VERSION ""

NS_ :

BS_:

BU_: ARM APIM_CDC APIM_CISM APIM ESPM DSP APIM_CIM FCIMB RACM_RCIM HUD_ADV WCM TRM_ITRM ACM GWM _delete IPC GENERIC TSTR

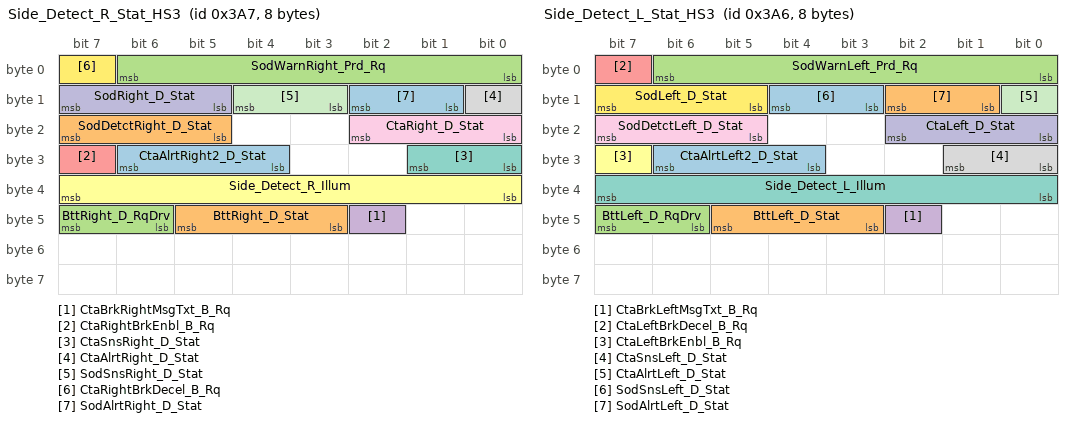
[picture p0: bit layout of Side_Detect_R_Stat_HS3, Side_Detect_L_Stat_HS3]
BO_ 935 Side_Detect_R_Stat_HS3: 8 GWM
 SG_ CtaAlrtRight2_D_Stat : 30|3@0+ (1,0) [0|7] "SED"  APIM_CDC,APIM_CIM,IPC
 SG_ BttRight_D_Stat : 45|3@0+ (1,0) [0|7] "SED"  APIM_CDC,APIM,APIM_CISM,APIM_CIM,IPC
 SG_ BttRight_D_RqDrv : 47|2@0+ (1,0) [0|3] "SED"  APIM_CDC,APIM,APIM_CISM,APIM_CIM,IPC
 SG_ CtaBrkRightMsgTxt_B_Rq : 42|1@0+ (1,0) [0|1] "SED"  APIM_CDC,APIM,APIM_CISM,APIM_CIM,IPC
 SG_ CtaRightBrkEnbl_B_Rq : 31|1@0+ (1,0) [0|1] "SED"  GENERIC
 SG_ Side_Detect_R_Illum : 39|8@0+ (1,0) [0|255] "Percent"  APIM_CDC,APIM_CIM,IPC
 SG_ CtaSnsRight_D_Stat : 25|2@0+ (1,0) [0|3] "SED"  APIM_CDC,APIM_CIM,IPC
 SG_ CtaAlrtRight_D_Stat : 8|1@0+ (1,0) [0|1] "SED"  APIM_CDC,APIM,APIM_CISM,APIM_CIM,IPC
 SG_ CtaRight_D_Stat : 18|3@0+ (1,0) [0|7] "SED"  APIM_CDC,APIM_CIM,IPC
 SG_ SodRight_D_Stat : 15|3@0+ (1,0) [0|7] "SED"  APIM_CDC,APIM_CIM,IPC
 SG_ SodSnsRight_D_Stat : 12|2@0+ (1,0) [0|3] "SED"  APIM_CDC,APIM_CIM,IPC
 SG_ CtaRightBrkDecel_B_Rq : 7|1@0+ (1,0) [0|1] "SED"  GENERIC
 SG_ SodAlrtRight_D_Stat : 10|2@0+ (1,0) [0|3] "SED"  APIM_CDC,APIM,APIM_CIM,HUD_ADV,APIM_CISM,IPC
 SG_ SodDetctRight_D_Stat : 23|3@0+ (1,0) [0|7] "SED"  APIM_CDC,APIM_CIM,IPC
 SG_ SodWarnRight_Prd_Rq : 6|7@0+ (1,0) [0|127] "millisecond" Vector__XXX

BO_ 934 Side_Detect_L_Stat_HS3: 8 GWM
 SG_ CtaAlrtLeft2_D_Stat : 30|3@0+ (1,0) [0|7] "SED"  APIM_CDC,APIM_CIM,IPC
 SG_ BttLeft_D_Stat : 45|3@0+ (1,0) [0|7] "SED"  APIM_CDC,APIM,APIM_CISM,APIM_CIM,IPC
 SG_ BttLeft_D_RqDrv : 47|2@0+ (1,0) [0|3] "SED"  APIM_CDC,APIM,APIM_CIM,APIM_CISM,IPC
 SG_ CtaBrkLeftMsgTxt_B_Rq : 42|1@0+ (1,0) [0|1] "SED"  APIM_CDC,APIM,APIM_CISM,APIM_CIM,IPC
 SG_ CtaLeftBrkDecel_B_Rq : 7|1@0+ (1,0) [0|1] "SED"  GENERIC
 SG_ CtaLeftBrkEnbl_B_Rq : 31|1@0+ (1,0) [0|1] "SED"  GENERIC
 SG_ Side_Detect_L_Illum : 39|8@0+ (1,0) [0|255] "Percent"  APIM_CDC,APIM_CIM,IPC
 SG_ CtaSnsLeft_D_Stat : 25|2@0+ (1,0) [0|3] "SED"  APIM_CDC,APIM_CIM,IPC
 SG_ SodDetctLeft_D_Stat : 23|3@0+ (1,0) [0|7] "SED"  APIM_CDC,APIM_CIM,IPC
 SG_ CtaLeft_D_Stat : 18|3@0+ (1,0) [0|7] "SED"  APIM_CDC,APIM_CIM,IPC
 SG_ CtaAlrtLeft_D_Stat : 8|1@0+ (1,0) [0|1] "SED"  APIM_CDC,APIM,APIM_CISM,APIM_CIM,IPC
 SG_ SodLeft_D_Stat : 15|3@0+ (1,0) [0|7] "SED"  APIM_CDC,APIM_CIM,IPC
 SG_ SodSnsLeft_D_Stat : 12|2@0+ (1,0) [0|3] "SED"  APIM_CDC,APIM_CIM,IPC
 SG_ SodAlrtLeft_D_Stat : 10|2@0+ (1,0) [0|3] "SED"  APIM_CDC,APIM,HUD_ADV,APIM_CISM,APIM_CIM,IPC
 SG_ SodWarnLeft_Prd_Rq : 6|7@0+ (1,0) [0|127] "millisecond" Vector__XXX

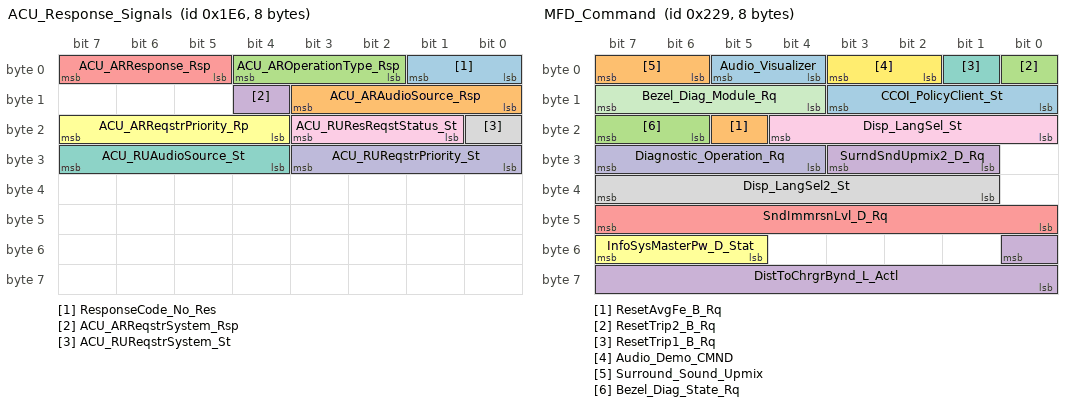
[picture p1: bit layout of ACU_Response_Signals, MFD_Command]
BO_ 486 ACU_Response_Signals: 8 APIM_CIM
 SG_ ResponseCode_No_Res : 1|2@0+ (1,0) [0|3] "SED"  APIM_CDC,APIM
 SG_ ACU_ARAudioSource_Rsp : 11|4@0+ (1,0) [0|15] "SED"  APIM_CDC,APIM,GWM,DSP,IPC
 SG_ ACU_AROperationType_Rsp : 4|3@0+ (1,0) [0|7] "SED"  APIM_CDC,APIM,GWM,DSP,IPC
 SG_ ACU_ARReqstrSystem_Rsp : 12|1@0+ (1,0) [0|1] "SED"  APIM_CDC,APIM,GWM,DSP,IPC
 SG_ ACU_ARResponse_Rsp : 7|3@0+ (1,0) [0|6] "SED"  APIM_CDC,APIM,GWM,DSP,IPC
 SG_ ACU_ARReqstrPriority_Rp : 23|4@0+ (1,0) [0|15] "SED"  APIM_CDC,APIM,GWM,DSP,IPC
 SG_ ACU_RUAudioSource_St : 31|4@0+ (1,0) [0|15] "SED"  HUD_ADV,APIM_CDC,APIM,DSP,GWM,RACM_RCIM,WCM,IPC
 SG_ ACU_RUReqstrSystem_St : 16|1@0+ (1,0) [0|1] "SED"  HUD_ADV,APIM_CDC,APIM,WCM,GWM,DSP,RACM_RCIM,IPC
 SG_ ACU_RUResReqstStatus_St : 19|3@0+ (1,0) [0|7] "SED"  HUD_ADV,APIM_CDC,APIM,DSP,GWM,RACM_RCIM,WCM,IPC
 SG_ ACU_RUReqstrPriority_St : 27|4@0+ (1,0) [0|15] "SED"  HUD_ADV,APIM_CDC,APIM,GWM,DSP,RACM_RCIM,WCM,IPC

BO_ 553 MFD_Command: 8 APIM
 SG_ CCOI_PolicyClient_St : 11|4@0+ (1,0) [0|15] "SED"  GWM
 SG_ ResetAvgFe_B_Rq : 21|1@0+ (1,0) [0|1] "SED"  IPC,GWM
 SG_ ResetTrip2_B_Rq : 0|1@0+ (1,0) [0|1] "SED"  IPC,GWM
 SG_ DistToChrgrBynd_L_Actl : 48|9@0+ (1,0) [0|509] "kilometer"  GWM
 SG_ SndImmrsnLvl_D_Rq : 47|8@0+ (1,0) [0|255] "SED"  DSP,GWM
 SG_ InfoSysMasterPw_D_Stat : 55|3@0+ (1,0) [0|7] "SED"  GWM
 SG_ ResetTrip1_B_Rq : 1|1@0+ (1,0) [0|1] "SED"  IPC,GWM
 SG_ Disp_LangSel2_St : 39|7@0+ (1,0) [0|127] "SED"  IPC,GWM
 SG_ Disp_LangSel_St : 20|5@0+ (1,0) [0|31] "SED"  GWM,RACM_RCIM,IPC
 SG_ Diagnostic_Operation_Rq : 31|4@0+ (1,0) [0|15] "SED"  DSP,GWM,ACM
 SG_ Bezel_Diag_Module_Rq : 15|4@0+ (1,0) [0|15] "SED"  DSP,GWM,ACM
 SG_ Audio_Demo_CMND : 3|2@0+ (1,0) [0|3] "SED"  GWM,DSP,ACM
 SG_ Audio_Visualizer : 5|2@0+ (1,0) [0|3] "SED"  GWM,DSP,ACM
 SG_ Surround_Sound_Upmix : 7|2@0+ (1,0) [0|3] "SED"  GWM,DSP
 SG_ Bezel_Diag_State_Rq : 23|2@0+ (1,0) [0|3] "SED"  DSP,GWM,ACM
 SG_ SurndSndUpmix2_D_Rq : 27|3@0+ (1,0) [0|7] "SED"  DSP,GWM

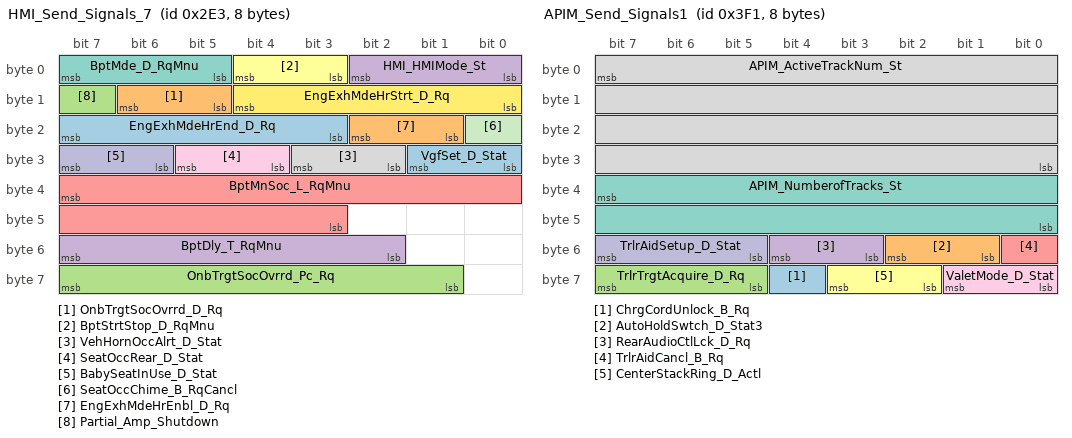
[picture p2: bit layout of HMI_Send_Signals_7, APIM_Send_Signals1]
BO_ 739 HMI_Send_Signals_7: 8 APIM
 SG_ VgfSet_D_Stat : 25|2@0+ (1,0) [0|3] "SED"  GWM
 SG_ OnbTrgtSocOvrrd_D_Rq : 14|2@0+ (1,0) [0|3] "SED"  GWM
 SG_ OnbTrgtSocOvrrd_Pc_Rq : 63|7@0+ (1,0) [0|127] "percent"  GWM
 SG_ BptDly_T_RqMnu : 55|6@0+ (0.5,0) [0|30.5] "minute"  GWM
 SG_ BptMnSoc_L_RqMnu : 39|13@0+ (0.1,0) [0|818.9] "kilometer"  GWM
 SG_ BptStrtStop_D_RqMnu : 4|2@0+ (1,0) [0|3] "SED"  GWM
 SG_ BptMde_D_RqMnu : 7|3@0+ (1,0) [0|7] "SED"  GWM
 SG_ VehHornOccAlrt_D_Stat : 27|2@0+ (1,0) [0|3] "SED"  GWM
 SG_ SeatOccRear_D_Stat : 29|2@0+ (1,0) [0|3] "SED"  GWM
 SG_ BabySeatInUse_D_Stat : 31|2@0+ (1,0) [0|3] "SED"  GWM
 SG_ SeatOccChime_B_RqCancl : 16|1@0+ (1,0) [0|1] "SED"  GWM
 SG_ EngExhMdeHrStrt_D_Rq : 12|5@0+ (1,0) [0|31] "SED"  GWM
 SG_ EngExhMdeHrEnd_D_Rq : 23|5@0+ (1,0) [0|31] "SED"  GWM
 SG_ EngExhMdeHrEnbl_D_Rq : 18|2@0+ (1,0) [0|3] "SED"  GWM
 SG_ Partial_Amp_Shutdown : 15|1@0+ (1,0) [0|1] "SED"  GWM,ACM
 SG_ HMI_HMIMode_St : 2|3@0+ (1,0) [0|7] "SED"  RACM_RCIM,DSP,HUD_ADV,ACM,WCM,IPC,GWM

BO_ 1009 APIM_Send_Signals1: 8 APIM
 SG_ ChrgCordUnlock_B_Rq : 60|1@0+ (1,0) [0|1] "SED"  GWM
 SG_ AutoHoldSwtch_D_Stat3 : 50|2@0+ (1,0) [0|3] "SED"  GWM
 SG_ TrlrTrgtAcquire_D_Rq : 63|3@0+ (1,0) [0|7] "SED"  GWM
 SG_ RearAudioCtlLck_D_Rq : 52|2@0+ (1,0) [0|3] "SED"  RACM_RCIM,GWM
 SG_ TrlrAidCancl_B_Rq : 48|1@0+ (1,0) [0|1] "SED"  GWM
 SG_ CenterStackRing_D_Actl : 59|2@0+ (1,0) [0|3] "SED"  GWM
 SG_ APIM_NumberofTracks_St : 39|16@0+ (1,0) [0|65535] "unitless"  RACM_RCIM,GWM,HUD_ADV,IPC
 SG_ APIM_ActiveTrackNum_St : 7|32@0+ (1,0) [0|4294967295] "unitless"  RACM_RCIM,GWM,HUD_ADV,IPC
 SG_ ValetMode_D_Stat : 57|2@0+ (1,0) [0|3] "SED"  GWM
 SG_ TrlrAidSetup_D_Stat : 55|3@0+ (1,0) [0|7] "SED"  GWM,IPC

BO_ 531 DesiredTorqBrk_HS3: 8 GWM
 SG_ VehStop_D_Stat : 28|2@0+ (1,0) [0|3] "SED"  GENERIC
 SG_ TracCtlPtActv_B_Actl : 31|1@0+ (1,0) [0|1] "SED"  GENERIC
 SG_ PrkBrkYwLamp_D_Rq : 38|2@0+ (1,0) [0|3] "SED"  APIM_CDC,APIM_CISM,APIM_CIM,IPC
 SG_ PrkBrkRedLamp_D_Rq : 30|2@0+ (1,0) [0|3] "SED"  APIM_CDC,APIM_CISM,APIM_CIM,IPC
 SG_ PrkBrkMsgTxt_D_Rq : 36|4@0+ (1,0) [0|15] "SED"  APIM_CDC,APIM_CISM,APIM_CIM,IPC
 SG_ PrkBrkStatus : 26|3@0+ (1,0) [0|7] "SED"  APIM_CDC,IPC,APIM,APIM_CIM,APIM_CISM
 SG_ LscmbbMntr_B_Err : 17|1@0+ (1,0) [0|1] "SED"  APIM_CDC,APIM,APIM_CISM,APIM_CIM,IPC
 SG_ LscmbbBrkDis_B_Actl : 19|1@0+ (1,0) [0|1] "SED"  GENERIC
 SG_ StabCtlBrkActv_B_Actl : 23|1@0+ (1,0) [0|1] "SED"  APIM_CDC,APIM,APIM_CIM,APIM_CISM
 SG_ CmbbBrkPrchg_B_Actl : 59|1@0+ (1,0) [0|1] "SED"  TRM_ITRM
 SG_ CmbbBrkDecel_B_Actl : 58|1@0+ (1,0) [0|1] "SED"  TRM_ITRM
 SG_ CmbbBaSensInc_B_Actl : 57|1@0+ (1,0) [0|1] "SED"  GENERIC
 SG_ AccBrkWarm_B_Actl : 63|1@0+ (1,0) [0|1] "SED"  GENERIC
 SG_ AccBrkTotTqMn_B_Actl : 62|1@0+ (1,0) [0|1] "SED"  TRM_ITRM
 SG_ AccBrkPrchgActv_B_Actl : 61|1@0+ (1,0) [0|1] "SED"  GENERIC
 SG_ AccBrkDis_B_Actl : 44|1@0+ (1,0) [0|1] "SED"  GENERIC
 SG_ AccBrkDeny_B_Actl : 42|1@0+ (1,0) [0|1] "SED"  GENERIC
 SG_ AccBrkActv_B_Actl : 43|1@0+ (1,0) [0|1] "SED"  GENERIC
 SG_ PrplDrgCtlActv_B_Actl : 46|1@0+ (1,0) [0|1] "SED"  GENERIC
 SG_ PrplWhlTot_Tq_RqMx : 7|16@0+ (4,-131072) [-131072|131068] "Nm"  GENERIC
 SG_ AbsActv_B_Actl : 45|1@0+ (1,0) [0|1] "SED"  APIM_CDC,APIM,APIM_CIM,APIM_CISM,TRM_ITRM
 SG_ CmbbBrkDis_B_Actl : 56|1@0+ (1,0) [0|1] "SED"  GENERIC
 SG_ CmbbDeny_B_ActlBrk : 60|1@0+ (1,0) [0|1] "SED"  GENERIC
 SG_ CcDis_B_Cmd : 47|1@0+ (1,0) [0|1] "SED"  GENERIC
 SG_ VehLongOvrGnd_A_Est : 41|10@0+ (0.035,-17.9) [-17.9|17.835] "m/s^2"  TRM_ITRM
 SG_ AccStopActv_B_ActlBrk : 22|1@0+ (1,0) [0|1] "SED"  GENERIC
 SG_ AccDis_B_ActlEpb : 32|1@0+ (1,0) [0|1] "SED"  GENERIC
 SG_ LscmbbDeny_B_ActlBrk : 18|1@0+ (1,0) [0|1] "SED"  GENERIC
 SG_ LscmbbBrkDecel_B_Actl : 20|1@0+ (1,0) [0|1] "SED"  GENERIC
 SG_ LscmbbBaSensInc_B_Actl : 21|1@0+ (1,0) [0|1] "SED"  GENERIC
 SG_ LscmbBrkPrchg_B_Actl : 16|1@0+ (1,0) [0|1] "SED"  GENERIC
 SG_ VehicleStationary : 39|1@0+ (1,0) [0|1] "SED"  GENERIC

BO_ 702 PHONE_MC_WORD_Rx: 8 IPC
 SG_ PHONE_MC_WORD_Rx : 7|64@0+ (1,0) [0|1.84467440737096E+019] "unitless"  APIM,APIM_CISM

BO_ 711 MyKeySrvr_MyKeyClient_Word: 8 IPC
 SG_ MyKeySrvr_Clnt_Word_Tx : 7|64@0+ (1,0) [0|1.84467440737096E+019] "unitless"  APIM,APIM_CISM

BO_ 549 IPC_Infotainment: 8 IPC
 SG_ BattTracLoThres_D_Rq2 : 52|3@0+ (1,0) [0|7] "SED"  GWM
 SG_ NavIod_D_Rq : 55|3@0+ (1,0) [0|7] "SED"  GWM,APIM_CISM
 SG_ StrtInGearOk_D_Stat : 17|2@0+ (1,0) [0|3] "SED"  GWM
 SG_ WwaActv_B_Stat : 46|1@0+ (1,0) [0|1] "SED"  APIM,APIM_CISM,GWM,ACM
 SG_ Veh_V2_Dsply : 39|9@0+ (1,0) [0|511] "unitless"  APIM_CDC,APIM,APIM_CISM,GWM,HUD_ADV
 SG_ IPC_MyKeyVolLimit_St : 9|2@0+ (1,0) [0|3] "SED"  APIM,APIM_CISM,GWM,DSP,ACM
 SG_ HudVertSzMnuOn_B_Rq : 21|1@0+ (1,0) [0|1] "SED"  GWM,HUD_ADV
 SG_ HudVertMnuOn_B_Rq : 11|1@0+ (1,0) [0|1] "SED"  GWM,HUD_ADV
 SG_ HudRotatMnuOn_B_Rq : 22|1@0+ (1,0) [0|1] "SED"  GWM,HUD_ADV
 SG_ HudCntntMnuOn_B_Rq : 20|1@0+ (1,0) [0|1] "SED"  GWM,HUD_ADV
 SG_ HudBrightMnuOn_B_Rq : 1|1@0+ (1,0) [0|1] "SED"  GWM,HUD_ADV
 SG_ HdcOn_B_Rq : 19|1@0+ (1,0) [0|1] "SED"  GWM
 SG_ IPC_Attn_Info_Audio : 4|3@0+ (1,0) [0|7] "SED"  APIM,APIM_CISM,GWM,DSP,ACM
 SG_ BeltminderAudioMute : 6|2@0+ (1,0) [0|3] "SED"  APIM,APIM_CISM,GWM,DSP,ACM
 SG_ Power_Up_Chime_Modules : 23|1@0+ (1,0) [0|1] "SED"  APIM_CISM,GWM,DSP,ACM
 SG_ Chime_Source : 15|2@0+ (1,0) [0|3] "SED"  APIM_CISM,GWM,DSP,ACM
 SG_ TjaLcEnbl_D_DrvRq : 41|2@0+ (1,0) [0|3] "SED"  GWM
 SG_ CCOI_PolicyClient_St2 : 45|4@0+ (1,0) [0|15] "SED"  GWM
 SG_ FactoryReset_Rq2 : 18|1@0+ (1,0) [0|1] "SED"  GWM
 SG_ IPC_New_Attn_Event : 0|1@0+ (1,0) [0|1] "SED"  APIM,APIM_CISM,GWM,DSP,ACM
 SG_ MetricActv_B_Dsply : 7|1@0+ (1,0) [0|1] "SED"  ARM,HUD_ADV,GWM

BO_ 765 Mc_Send_Signals_2: 8 IPC
 SG_ BalrSwtch_D_Stat : 57|2@0+ (1,0) [0|3] "SED"  GWM
 SG_ BalrMde_D_Rq : 59|2@0+ (1,0) [0|3] "SED"  GWM
 SG_ RstrnOnPsngr_D_RqMnu : 63|4@0+ (1,0) [0|15] "SED"  GWM
 SG_ WaitToStartLamp_D_Falt : 50|2@0+ (1,0) [0|3] "SED"  GWM
 SG_ EsaOn_B_Rq : 15|1@0+ (1,0) [0|1] "SED"  GWM
 SG_ BttOn_B_Rq : 26|1@0+ (1,0) [0|1] "SED"  GWM
 SG_ Btt_L_Actl : 39|7@0+ (0.1,0) [0|12.5] "meter"  GWM
 SG_ RearDiffLck_D_RqArb : 25|2@0+ (1,0) [0|3] "SED"  GWM
 SG_ AwdMde_D_RqArb : 47|3@0+ (1,0) [0|7] "SED"  GWM
 SG_ SelDrvMdeTxtReset_B_Rq : 40|1@0+ (1,0) [0|1] "SED"  GWM
 SG_ AutoTowAllw_D_RqMnu : 52|2@0+ (1,0) [0|3] "SED"  GWM
 SG_ DrvInputRequired_B_Rq : 32|1@0+ (1,0) [0|1] "SED"  GWM
 SG_ SelDrvMdeDsply_B_Avail : 41|1@0+ (1,0) [0|1] "SED"  GWM
 SG_ EngExhMdeQuiet_D_Rq : 17|2@0+ (1,0) [0|3] "SED"  GWM
 SG_ AirSusp_D_RqDrv : 31|2@0+ (1,0) [0|3] "SED"  GWM
 SG_ Mc_VehUntTrpCoUsrSel_St : 23|1@0+ (1,0) [0|1] "SED"  APIM,APIM_CISM,HUD_ADV,GWM
 SG_ Mc_VehUnitTempUsrSel_St : 22|1@0+ (1,0) [0|1] "SED"  APIM,APIM_CISM,HUD_ADV,RACM_RCIM,GWM
 SG_ Mc_VehDayNightUsrSel_St : 14|3@0+ (1,0) [0|7] "SED"  APIM,APIM_CISM,GWM,ACM
 SG_ Mc_VehTimeFrmtUsrSel_St : 1|2@0+ (1,0) [0|3] "SED"  APIM,APIM_CISM,GWM,HUD_ADV,RACM_RCIM
 SG_ Mc_VehThemeUsrSel_St : 11|4@0+ (1,0) [0|15] "SED"  APIM,APIM_CISM,GWM,GENERIC
 SG_ Mc_VehLangUsrSel_St : 7|6@0+ (1,0) [0|63] "SED"  APIM,APIM_CISM,HUD_ADV,ACM,GWM
 SG_ AwdRnge_D_ActlIpc : 29|3@0+ (1,0) [0|7] "SED"  GWM
 SG_ AwdDrvMde_D_Rq : 44|3@0+ (1,0) [0|7] "SED"  GWM
 SG_ EngExhMdeQuiet_D2_Rq : 55|3@0+ (1,0) [0|7] "SED"  GWM
 SG_ BrkLineLck_D_Rq : 19|2@0+ (1,0) [0|3] "SED"  GWM
 SG_ EdmSailMde_B_RqDrv : 48|1@0+ (1,0) [0|1] "SED"  GWM
 SG_ Running_Board_Cmd : 21|2@0+ (1,0) [0|3] "SED"  GWM

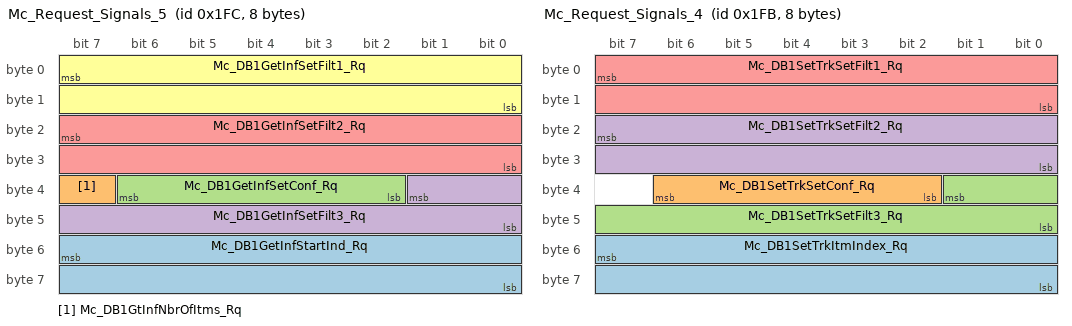
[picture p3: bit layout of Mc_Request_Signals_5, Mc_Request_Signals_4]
BO_ 508 Mc_Request_Signals_5: 8 IPC
 SG_ Mc_DB1GetInfStartInd_Rq : 55|16@0+ (1,0) [0|65535] "unitless"  APIM_CISM,ACM,GWM
 SG_ Mc_DB1GtInfNbrOfItms_Rq : 39|1@0+ (1,0) [0|1] "SED"  APIM_CISM,ACM,GWM
 SG_ Mc_DB1GetInfSetConf_Rq : 38|5@0+ (1,0) [0|31] "SED"  APIM_CISM,ACM,GWM
 SG_ Mc_DB1GetInfSetFilt3_Rq : 33|10@0+ (1,0) [0|1023] "unitless"  APIM_CISM,ACM,GWM
 SG_ Mc_DB1GetInfSetFilt2_Rq : 23|16@0+ (1,0) [0|65535] "unitless"  APIM_CISM,ACM,GWM
 SG_ Mc_DB1GetInfSetFilt1_Rq : 7|16@0+ (1,0) [0|65535] "unitless"  APIM_CISM,ACM,GWM

BO_ 507 Mc_Request_Signals_4: 8 IPC
 SG_ Mc_DB1SetTrkItmIndex_Rq : 55|16@0+ (1,0) [0|65535] "unitless"  APIM_CISM,ACM,GWM
 SG_ Mc_DB1SetTrkSetConf_Rq : 38|5@0+ (1,0) [0|31] "SED"  APIM_CISM,ACM,GWM
 SG_ Mc_DB1SetTrkSetFilt3_Rq : 33|10@0+ (1,0) [0|1023] "unitless"  APIM_CISM,ACM,GWM
 SG_ Mc_DB1SetTrkSetFilt2_Rq : 23|16@0+ (1,0) [0|65535] "unitless"  APIM_CISM,ACM,GWM
 SG_ Mc_DB1SetTrkSetFilt1_Rq : 7|16@0+ (1,0) [0|65535] "unitless"  APIM_CISM,ACM,GWM

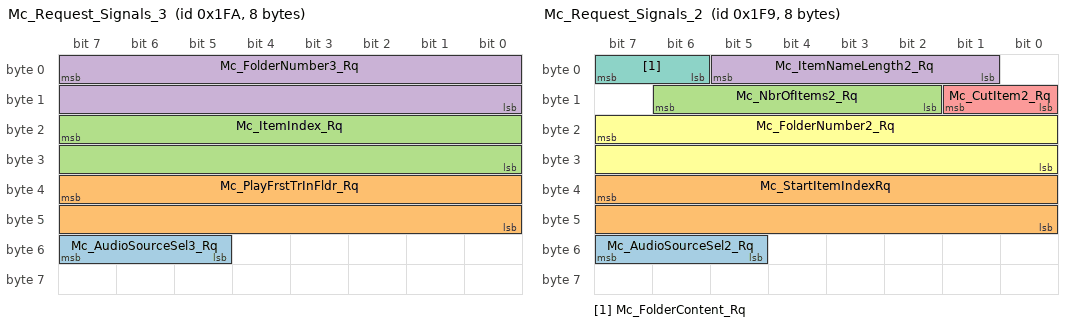
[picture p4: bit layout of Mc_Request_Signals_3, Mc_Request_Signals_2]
BO_ 506 Mc_Request_Signals_3: 8 IPC
 SG_ Mc_AudioSourceSel3_Rq : 55|3@0+ (1,0) [0|7] "SED"  APIM_CISM,ACM,GWM
 SG_ Mc_PlayFrstTrInFldr_Rq : 39|16@0+ (1,0) [0|65535] "unitless"  APIM_CISM,ACM,GWM
 SG_ Mc_ItemIndex_Rq : 23|16@0+ (1,0) [0|65535] "unitless"  APIM_CISM,ACM,GWM
 SG_ Mc_FolderNumber3_Rq : 7|16@0+ (1,0) [0|65535] "unitless"  APIM_CISM,ACM,GWM

BO_ 505 Mc_Request_Signals_2: 8 IPC
 SG_ Mc_AudioSourceSel2_Rq : 55|3@0+ (1,0) [0|7] "SED"  APIM_CISM,ACM,GWM
 SG_ Mc_StartItemIndexRq : 39|16@0+ (1,0) [0|65535] "unitless"  APIM_CISM,ACM,GWM
 SG_ Mc_NbrOfItems2_Rq : 14|5@0+ (1,0) [0|20] "SED"  APIM_CISM,ACM,GWM
 SG_ Mc_ItemNameLength2_Rq : 5|5@0+ (1,0) [0|20] "SED"  APIM_CISM,ACM,GWM
 SG_ Mc_CutItem2_Rq : 9|2@0+ (1,0) [0|3] "SED"  APIM_CISM,ACM,GWM
 SG_ Mc_FolderNumber2_Rq : 23|16@0+ (1,0) [0|65535] "unitless"  APIM_CISM,ACM,GWM
 SG_ Mc_FolderContent_Rq : 7|2@0+ (1,0) [0|3] "SED"  APIM_CISM,ACM,GWM

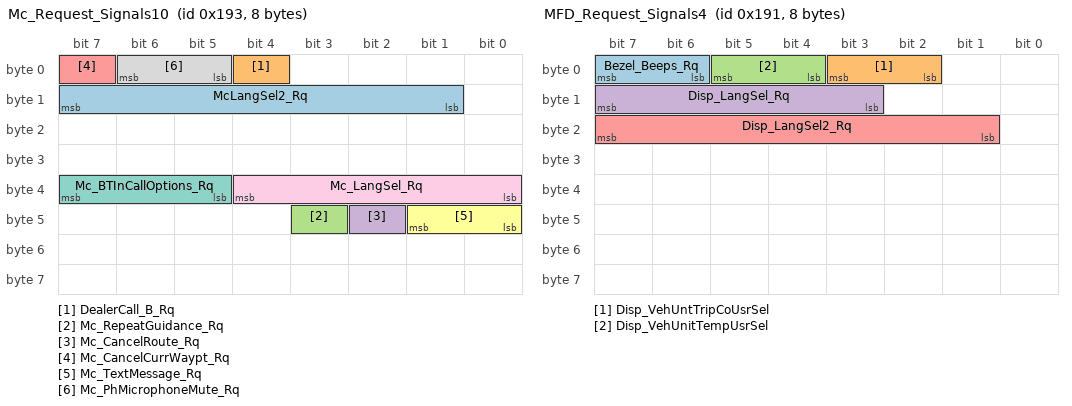
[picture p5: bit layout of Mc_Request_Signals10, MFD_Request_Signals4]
BO_ 403 Mc_Request_Signals10: 8 IPC
 SG_ McLangSel2_Rq : 15|7@0+ (1,0) [0|127] "SED"  APIM,APIM_CISM,GWM
 SG_ DealerCall_B_Rq : 4|1@0+ (1,0) [0|1] "SED"  APIM,APIM_CISM,GWM
 SG_ Mc_RepeatGuidance_Rq : 43|1@0+ (1,0) [0|1] "SED"  APIM,APIM_CISM,GWM
 SG_ Mc_CancelRoute_Rq : 42|1@0+ (1,0) [0|1] "SED"  APIM,APIM_CISM,GWM
 SG_ Mc_CancelCurrWaypt_Rq : 7|1@0+ (1,0) [0|1] "SED"  APIM,APIM_CISM,GWM
 SG_ Mc_TextMessage_Rq : 41|2@0+ (1,0) [0|3] "SED"  APIM,APIM_CISM,GWM
 SG_ Mc_BTInCallOptions_Rq : 39|3@0+ (1,0) [0|7] "SED"  APIM,APIM_CISM,GWM
 SG_ Mc_PhMicrophoneMute_Rq : 6|2@0+ (1,0) [0|3] "SED"  APIM,APIM_CISM,GWM
 SG_ Mc_LangSel_Rq : 36|5@0+ (1,0) [0|31] "SED"  APIM,APIM_CISM,GWM

BO_ 401 MFD_Request_Signals4: 8 APIM
 SG_ Bezel_Beeps_Rq : 7|2@0+ (1,0) [0|3] "SED"  FCIMB,GWM
 SG_ Disp_VehUntTripCoUsrSel : 3|2@0+ (1,0) [0|3] "SED"  GWM,IPC
 SG_ Disp_VehUnitTempUsrSel : 5|2@0+ (1,0) [0|3] "SED"  GWM,IPC
 SG_ Disp_LangSel_Rq : 15|5@0+ (1,0) [0|31] "SED"  GWM,IPC
 SG_ Disp_LangSel2_Rq : 23|7@0+ (1,0) [0|127] "SED"  IPC

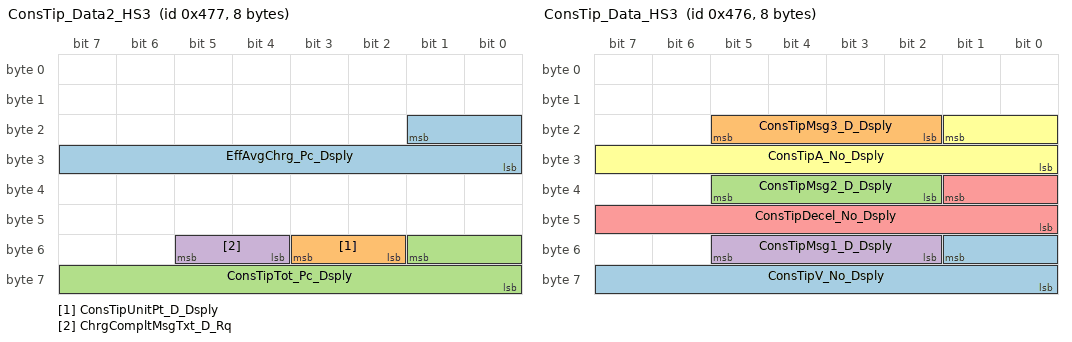
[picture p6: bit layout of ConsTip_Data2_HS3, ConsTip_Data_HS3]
BO_ 1143 ConsTip_Data2_HS3: 8 GWM
 SG_ EffAvgChrg_Pc_Dsply : 17|10@0+ (0.1,0) [0|102.3] "percent"  APIM_CDC,APIM_CISM,APIM_CIM,IPC
 SG_ ConsTipUnitPt_D_Dsply : 51|2@0+ (1,0) [0|3] "SED"  APIM_CDC,APIM,APIM_CIM,APIM_CISM,IPC
 SG_ ConsTipTot_Pc_Dsply : 49|10@0+ (0.1,0) [0|102.1] "percent"  APIM_CDC,APIM_CIM,IPC
 SG_ ChrgCompltMsgTxt_D_Rq : 53|2@0+ (1,0) [0|3] "SED"  APIM_CDC,APIM,APIM_CIM,APIM_CISM,IPC

BO_ 1142 ConsTip_Data_HS3: 8 GWM
 SG_ ConsTipV_No_Dsply : 49|10@0+ (0.1,0) [0|102.1] "percent"  APIM_CDC,APIM,APIM_CIM,APIM_CISM,IPC
 SG_ ConsTipMsg3_D_Dsply : 21|4@0+ (1,0) [0|15] "SED"  APIM_CDC,APIM,APIM_CIM,APIM_CISM,IPC
 SG_ ConsTipMsg2_D_Dsply : 37|4@0+ (1,0) [0|15] "SED"  APIM_CDC,APIM,APIM_CIM,APIM_CISM,IPC
 SG_ ConsTipMsg1_D_Dsply : 53|4@0+ (1,0) [0|15] "SED"  APIM_CDC,APIM,APIM_CIM,APIM_CISM,IPC
 SG_ ConsTipDecel_No_Dsply : 33|10@0+ (0.1,0) [0|102.1] "percent"  APIM_CDC,APIM,APIM_CIM,APIM_CISM,IPC
 SG_ ConsTipA_No_Dsply : 17|10@0+ (0.1,0) [0|102.1] "percent"  APIM_CDC,APIM,APIM_CIM,APIM_CISM,IPC

BO_ 973 Traffic_RecogitionData_HS3: 8 GWM
 SG_ PersCtaSplitView_D_Stat : 12|2@0+ (1,0) [0|3] "SED"  APIM_CDC,APIM,APIM_CIM,APIM_CISM
 SG_ LaSysOffStat_D_Dsply : 58|2@0+ (1,0) [0|3] "SED"  APIM_CDC,APIM_CIM,IPC
 SG_ TsrVl1RstrcMsgTxt2_D_Rq : 51|3@0+ (1,0) [0|7] "SED"  APIM_CDC,APIM_CISM,APIM_CIM,HUD_ADV,IPC
 SG_ TsrVl2RstrcMsgTxt2_D_Rq : 63|3@0+ (1,0) [0|7] "SED"  APIM_CDC,APIM_CISM,APIM_CIM,HUD_ADV,IPC
 SG_ TsrVl2PrmntMsgTxt_D_Rq : 60|2@0+ (1,0) [0|3] "SED"  APIM_CDC,APIM_CISM,APIM_CIM,HUD_ADV,IPC
 SG_ TsrVl1PrmntMsgTxt_D_Rq : 41|2@0+ (1,0) [0|3] "SED"  APIM_CDC,APIM_CISM,APIM_CIM,HUD_ADV,IPC
 SG_ TsrOvtkMsgTxt2_D_Rq : 55|4@0+ (1,0) [0|15] "SED"  APIM_CDC,APIM_CISM,HUD_ADV,APIM_CIM,IPC
 SG_ WwaWarn_B_Rq : 48|1@0+ (1,0) [0|1] "SED"  APIM_CDC,APIM_CISM,APIM_CIM,HUD_ADV,IPC
 SG_ RoadSignRgltry_D_Dsply : 19|2@0+ (1,0) [0|3] "SED"  APIM_CDC,APIM_CIM,IPC
 SG_ TsrVlUnitMsgTxt_D_Rq : 43|2@0+ (1,0) [0|3] "SED"  APIM_CDC,APIM,APIM_CISM,APIM_CIM,HUD_ADV,IPC
 SG_ TsrVLim2MsgTxt_D_Rq : 39|8@0+ (1,0) [0|255] "SED"  APIM_CDC,APIM_CISM,APIM_CIM,HUD_ADV,IPC
 SG_ TsrVLim1MsgTxt_D_Rq : 31|8@0+ (1,0) [0|255] "SED"  APIM_CDC,APIM_CISM,APIM_CIM,HUD_ADV,IPC
 SG_ TsrVl2StatMsgTxt_D_Rq : 47|2@0+ (1,0) [0|3] "SED"  APIM_CDC,APIM_CISM,APIM_CIM,HUD_ADV,IPC
 SG_ TsrVl2RstrcMsgTxt_D_Rq : 17|2@0+ (1,0) [0|3] "SED"  APIM_CDC,APIM_CISM,APIM_CIM,IPC
 SG_ TsrVl1StatMsgTxt_D_Rq : 21|2@0+ (1,0) [0|3] "SED"  APIM_CDC,APIM_CISM,APIM_CIM,HUD_ADV,IPC
 SG_ TsrVl1RstrcMsgTxt_D_Rq : 23|2@0+ (1,0) [0|3] "SED"  APIM_CDC,APIM_CISM,APIM_CIM,IPC
 SG_ TsrStatMsgTxt_D_Rq : 10|3@0+ (1,0) [0|7] "SED"  APIM_CDC,APIM_CISM,APIM_CIM,IPC
 SG_ TsrOvtkStatMsgTxt_D_Rq : 1|2@0+ (1,0) [0|3] "SED"  APIM_CDC,APIM_CISM,APIM_CIM,HUD_ADV,IPC
 SG_ TsrOvtkMsgTxt_D_Rq : 15|3@0+ (1,0) [0|7] "SED"  APIM_CDC,APIM_CISM,HUD_ADV,APIM_CIM,IPC
 SG_ TsrOswWarnMsgTxt_D_Rq : 3|2@0+ (1,0) [0|3] "SED"  APIM_CDC,APIM_CISM,HUD_ADV,APIM_CIM,IPC
 SG_ TsrMsgTxt_D_Rq : 7|4@0+ (1,0) [0|15] "SED"  APIM_CDC,APIM_CISM,APIM_CIM,IPC

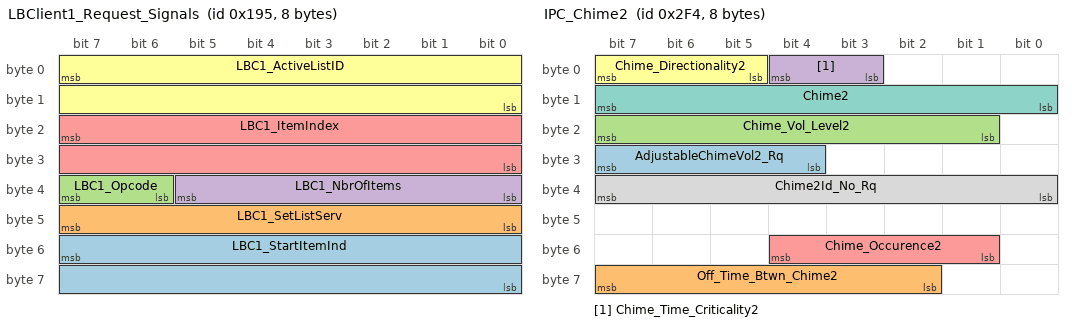
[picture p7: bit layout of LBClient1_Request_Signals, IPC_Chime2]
BO_ 405 LBClient1_Request_Signals: 8 IPC
 SG_ LBC1_StartItemInd : 55|16@0+ (1,0) [0|65535] "unitless"  APIM,APIM_CISM,GWM,ACM
 SG_ LBC1_SetListServ : 47|8@0+ (1,0) [0|255] "unitless"  APIM,APIM_CISM,GWM,ACM
 SG_ LBC1_Opcode : 39|2@0+ (1,0) [0|3] "SED"  APIM,APIM_CISM,GWM,ACM
 SG_ LBC1_NbrOfItems : 37|6@0+ (1,0) [0|63] "unitless"  APIM,APIM_CISM,GWM,ACM
 SG_ LBC1_ItemIndex : 23|16@0+ (1,0) [0|65535] "unitless"  APIM,APIM_CISM,GWM,ACM
 SG_ LBC1_ActiveListID : 7|16@0+ (1,0) [0|65535] "unitless"  APIM,APIM_CISM,GWM,ACM

BO_ 756 IPC_Chime2: 8 IPC
 SG_ AdjustableChimeVol2_Rq : 31|4@0+ (1,0) [0|15] "SED"  APIM_CISM,GWM,ACM,DSP
 SG_ Off_Time_Btwn_Chime2 : 63|6@0+ (1,0) [0|52] "unitless"  APIM_CISM,GWM,DSP,ACM
 SG_ Chime_Vol_Level2 : 23|7@0+ (1,0) [0|127] "unitless"  APIM_CISM,GWM,DSP,ACM
 SG_ Chime_Time_Criticality2 : 4|2@0+ (1,0) [0|3] "SED"  APIM_CISM,GWM,DSP,ACM
 SG_ Chime_Occurence2 : 52|4@0+ (1,0) [0|15] "SED"  APIM_CISM,GWM,DSP,ACM
 SG_ Chime_Directionality2 : 7|3@0+ (1,0) [0|7] "SED"  APIM_CISM,GWM,DSP,ACM
 SG_ Chime2 : 15|8@0+ (1,0) [0|255] "unitless"  APIM_CISM,GWM,DSP,ACM
 SG_ Chime2Id_No_Rq : 39|8@0+ (1,0) [0|255] "SED"  APIM_CISM,DSP,ACM

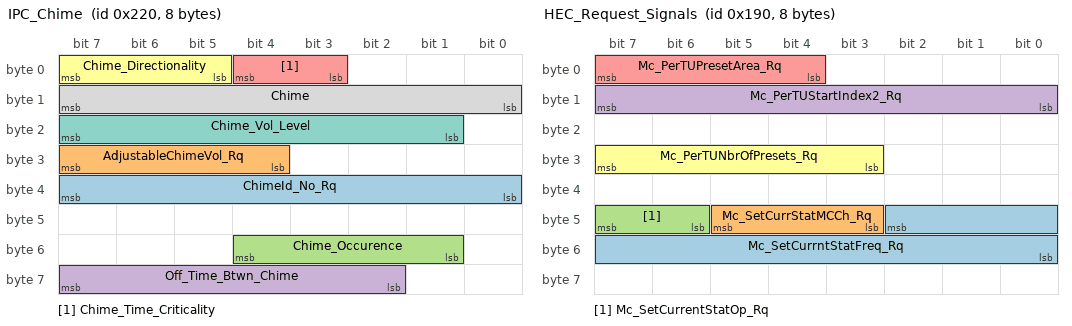
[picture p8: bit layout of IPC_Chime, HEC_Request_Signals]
BO_ 544 IPC_Chime: 8 IPC
 SG_ ChimeId_No_Rq : 39|8@0+ (1,0) [0|255] "SED"  APIM_CISM,GWM,ACM
 SG_ AdjustableChimeVol_Rq : 31|4@0+ (1,0) [0|15] "SED"  APIM_CISM,GWM,ACM,DSP
 SG_ Chime_Occurence : 52|4@0+ (1,0) [0|15] "SED"  APIM_CISM,GWM,DSP,ACM
 SG_ Off_Time_Btwn_Chime : 63|6@0+ (1,0) [0|52] "unitless"  APIM_CISM,GWM,DSP,ACM
 SG_ Chime_Time_Criticality : 4|2@0+ (1,0) [0|3] "SED"  APIM_CISM,GWM,DSP,ACM
 SG_ Chime_Directionality : 7|3@0+ (1,0) [0|7] "SED"  APIM_CISM,GWM,DSP,ACM
 SG_ Chime_Vol_Level : 23|7@0+ (1,0) [0|127] "unitless"  APIM_CISM,GWM,DSP,ACM
 SG_ Chime : 15|8@0+ (1,0) [0|255] "unitless"  APIM_CISM,GWM,DSP,ACM

BO_ 291 HEC_Response_Signals: 8 IPC
 SG_ LangUpdate_Rsp : 7|2@0+ (1,0) [0|3] "SED"  APIM,APIM_CISM,GWM

BO_ 400 HEC_Request_Signals: 8 IPC
 SG_ Mc_SetCurrntStatFreq_Rq : 42|11@0+ (1,0) [0|1557] "unitless"  GWM,APIM_CISM,ACM
 SG_ Mc_SetCurrStatMCCh_Rq : 45|3@0+ (1,0) [0|7] "SED"  GWM,APIM_CISM,ACM
 SG_ Mc_SetCurrentStatOp_Rq : 47|2@0+ (1,0) [0|3] "SED"  GWM,APIM_CISM,ACM
 SG_ Mc_PerTUStartIndex2_Rq : 15|8@0+ (1,0) [0|255] "unitless"  APIM,APIM_CISM,ACM,GWM
 SG_ Mc_PerTUPresetArea_Rq : 7|4@0+ (1,0) [0|15] "SED"  APIM,APIM_CISM,ACM,GWM
 SG_ Mc_PerTUNbrOfPresets_Rq : 31|5@0+ (1,0) [0|31] "SED"  APIM,APIM_CISM,ACM,GWM

BO_ 647 HEC_DispDimm: 8 IPC
 SG_ HEC_BTIncomingCall_Rq : 23|2@0+ (1,0) [0|3] "SED"  APIM,APIM_CISM
 SG_ HEC_BTEndTelService_Rq : 3|2@0+ (1,0) [0|3] "SED"  APIM,APIM_CISM

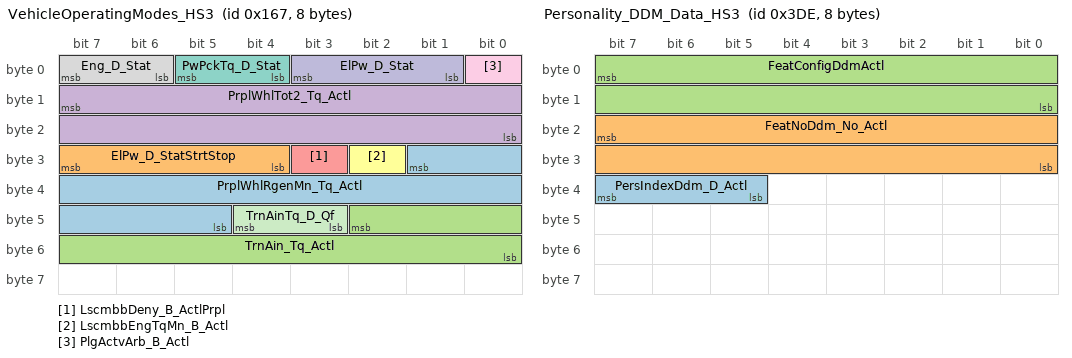
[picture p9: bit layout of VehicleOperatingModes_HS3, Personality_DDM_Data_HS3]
BO_ 359 VehicleOperatingModes_HS3: 8 GWM
 SG_ PrplWhlRgenMn_Tq_Actl : 25|13@0+ (4,-16380) [-16380|16380] "Nm"  GENERIC
 SG_ ElPw_D_StatStrtStop : 31|4@0+ (1,0) [0|15] "SED"  GENERIC
 SG_ TrnAin_Tq_Actl : 42|11@0+ (1,-500) [-500|1547] "Nm"  APIM_CDC,APIM,APIM_CISM,APIM_CIM,IPC,ACM
 SG_ PrplWhlTot2_Tq_Actl : 15|16@0+ (4,-131072) [-131072|131060] "Nm"  APIM_CDC,APIM,APIM_CISM,APIM_CIM,IPC
 SG_ LscmbbDeny_B_ActlPrpl : 27|1@0+ (1,0) [0|1] "SED"  GENERIC
 SG_ LscmbbEngTqMn_B_Actl : 26|1@0+ (1,0) [0|1] "SED"  GENERIC
 SG_ PwPckTq_D_Stat : 5|2@0+ (1,0) [0|3] "SED"  APIM_CDC,APIM,APIM_CISM,APIM_CIM,RACM_RCIM,TRM_ITRM,DSP,ACM,WCM,IPC
 SG_ Eng_D_Stat : 7|2@0+ (1,0) [0|3] "SED"  APIM_CDC,APIM,APIM_CISM,APIM_CIM,RACM_RCIM,TRM_ITRM,WCM,DSP,ACM
 SG_ PlgActvArb_B_Actl : 0|1@0+ (1,0) [0|1] "SED"  APIM_CDC,IPC
 SG_ ElPw_D_Stat : 3|3@0+ (1,0) [0|7] "SED"  APIM_CDC,APIM,APIM_CISM,RACM_RCIM,TRM_ITRM,APIM_CIM,DSP,ACM,IPC
 SG_ TrnAinTq_D_Qf : 44|2@0+ (1,0) [0|3] "SED"  APIM_CISM,ACM

BO_ 990 Personality_DDM_Data_HS3: 8 GWM
 SG_ PersIndexDdm_D_Actl : 39|3@0+ (1,0) [0|7] "SED"  APIM_CDC,APIM,APIM_CIM,APIM_CISM,IPC
 SG_ FeatNoDdm_No_Actl : 23|16@0+ (1,0) [0|65535] "Number"  APIM_CDC,APIM,APIM_CIM,APIM_CISM,IPC
 SG_ FeatConfigDdmActl : 7|16@0+ (1,0) [0|65535] "Undefined"  APIM_CDC,APIM,APIM_CIM,APIM_CISM,IPC

BO_ 989 Personality_HCM_Data_HS3: 8 GWM
 SG_ FeatNoHcm_No_Actl : 23|16@0+ (1,0) [0|65535] "Number"  APIM_CDC,APIM,APIM_CIM,APIM_CISM,IPC
 SG_ FeatConfigHcmActl : 7|16@0+ (1,0) [0|65535] "Undefined"  APIM_CDC,APIM,APIM_CIM,APIM_CISM,IPC

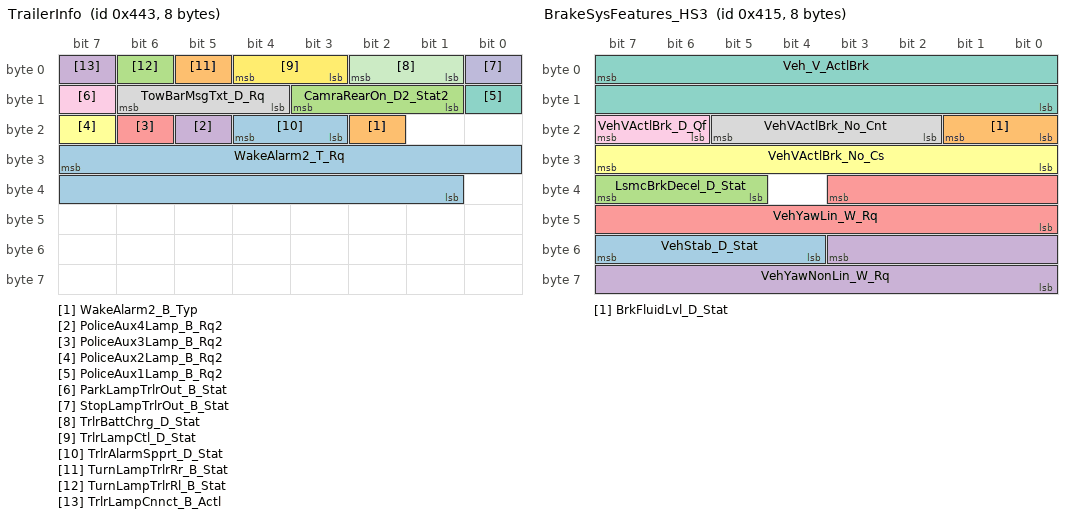
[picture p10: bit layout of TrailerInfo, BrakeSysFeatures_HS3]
BO_ 1091 TrailerInfo: 8 TRM_ITRM
 SG_ WakeAlarm2_T_Rq : 31|15@0+ (1,0) [0|32767] "minute"  GWM
 SG_ WakeAlarm2_B_Typ : 18|1@0+ (1,0) [0|1] "SED"  GWM
 SG_ CamraRearOn_D2_Stat2 : 11|3@0+ (1,0) [0|7] "SED"  APIM_CDC,APIM,APIM_CISM,APIM_CIM,GWM
 SG_ PoliceAux4Lamp_B_Rq2 : 21|1@0+ (1,0) [0|1] "SED"  APIM_CDC,APIM_CIM,IPC,GWM
 SG_ PoliceAux3Lamp_B_Rq2 : 22|1@0+ (1,0) [0|1] "SED"  APIM_CDC,APIM_CIM,IPC,GWM
 SG_ PoliceAux2Lamp_B_Rq2 : 23|1@0+ (1,0) [0|1] "SED"  APIM_CDC,APIM_CIM,IPC,GWM
 SG_ PoliceAux1Lamp_B_Rq2 : 8|1@0+ (1,0) [0|1] "SED"  APIM_CDC,APIM_CIM,IPC,GWM
 SG_ TowBarMsgTxt_D_Rq : 14|3@0+ (1,0) [0|7] "SED"  APIM_CDC,APIM_CIM,IPC,GWM
 SG_ ParkLampTrlrOut_B_Stat : 15|1@0+ (1,0) [0|1] "SED"  APIM_CDC,APIM_CIM,IPC,GWM
 SG_ StopLampTrlrOut_B_Stat : 0|1@0+ (1,0) [0|1] "SED"  APIM_CDC,APIM_CIM,IPC,GWM
 SG_ TrlrBattChrg_D_Stat : 2|2@0+ (1,0) [0|3] "SED"  APIM_CDC,APIM_CIM,IPC,GWM
 SG_ TrlrLampCtl_D_Stat : 4|2@0+ (1,0) [0|3] "SED"  APIM_CDC,APIM_CIM,IPC,GWM
 SG_ TrlrAlarmSpprt_D_Stat : 20|2@0+ (1,0) [0|3] "SED"  APIM_CDC,APIM,APIM_CISM,APIM_CIM,GWM
 SG_ TurnLampTrlrRr_B_Stat : 5|1@0+ (1,0) [0|1] "SED"  APIM_CDC,APIM_CIM,IPC,GWM
 SG_ TurnLampTrlrRl_B_Stat : 6|1@0+ (1,0) [0|1] "SED"  APIM_CDC,APIM_CIM,IPC,GWM
 SG_ TrlrLampCnnct_B_Actl : 7|1@0+ (1,0) [0|1] "SED"  APIM_CDC,APIM,APIM_CISM,APIM_CIM,IPC,GWM

BO_ 1045 BrakeSysFeatures_HS3: 8 GWM
 SG_ VehStab_D_Stat : 55|4@0+ (1,0) [0|15] "SED" Vector__XXX
 SG_ BrkFluidLvl_D_Stat : 17|2@0+ (1,0) [0|3] "SED" Vector__XXX
 SG_ LsmcBrkDecel_D_Stat : 39|3@0+ (1,0) [0|7] "SED" Vector__XXX
 SG_ VehYawNonLin_W_Rq : 51|12@0+ (0.03663,-75) [-75|74.92659] "deg/s" Vector__XXX
 SG_ VehYawLin_W_Rq : 35|12@0+ (0.03663,-75) [-75|74.92659] "deg/s" Vector__XXX
 SG_ VehVActlBrk_No_Cs : 31|8@0+ (1,0) [0|255] "unitless"  TRM_ITRM
 SG_ Veh_V_ActlBrk : 7|16@0+ (0.01,0) [0|655.35] "kph"  TRM_ITRM
 SG_ VehVActlBrk_No_Cnt : 21|4@0+ (1,0) [0|15] "unitless"  TRM_ITRM
 SG_ VehVActlBrk_D_Qf : 23|2@0+ (1,0) [0|3] "SED"  TRM_ITRM

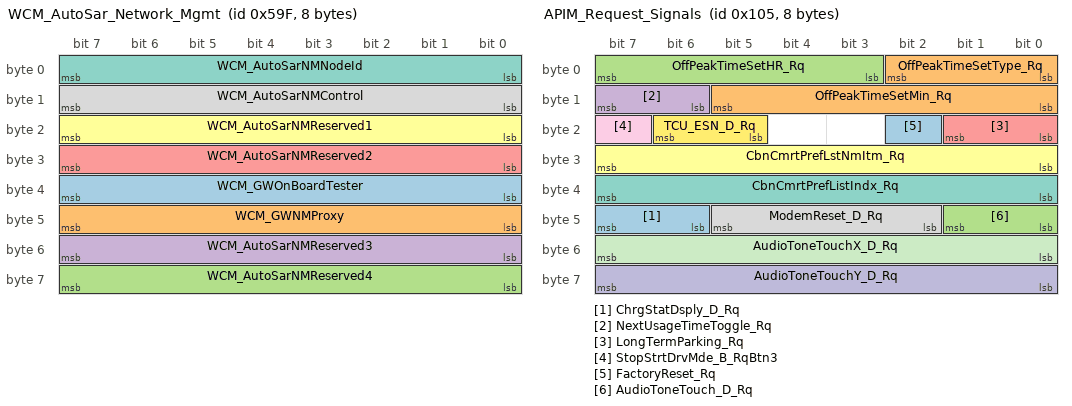
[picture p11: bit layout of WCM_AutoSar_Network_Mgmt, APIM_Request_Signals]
BO_ 1439 WCM_AutoSar_Network_Mgmt: 8 WCM
 SG_ WCM_GWOnBoardTester : 39|8@0+ (1,0) [0|255] "unitless"  IPC,HUD_ADV,GENERIC,ACM
 SG_ WCM_GWNMProxy : 47|8@0+ (1,0) [0|255] "unitless"  IPC,HUD_ADV,GENERIC,ACM
 SG_ WCM_AutoSarNMReserved4 : 63|8@0+ (1,0) [0|255] "unitless"  IPC,HUD_ADV,GENERIC,ACM
 SG_ WCM_AutoSarNMReserved3 : 55|8@0+ (1,0) [0|255] "unitless"  IPC,HUD_ADV,GENERIC,ACM
 SG_ WCM_AutoSarNMReserved2 : 31|8@0+ (1,0) [0|255] "unitless"  IPC,HUD_ADV,GENERIC,ACM
 SG_ WCM_AutoSarNMReserved1 : 23|8@0+ (1,0) [0|255] "unitless"  IPC,HUD_ADV,GENERIC,ACM
 SG_ WCM_AutoSarNMNodeId : 7|8@0+ (1,0) [0|255] "unitless"  IPC,HUD_ADV,GENERIC,ACM
 SG_ WCM_AutoSarNMControl : 15|8@0+ (1,0) [0|255] "unitless"  IPC,HUD_ADV,GENERIC,ACM

BO_ 261 APIM_Request_Signals: 8 ACM
 SG_ ChrgStatDsply_D_Rq : 47|2@0+ (1,0) [0|3] "SED"  GWM
 SG_ OffPeakTimeSetMin_Rq : 13|6@0+ (1,0) [0|63] "unitless"  GWM
 SG_ OffPeakTimeSetHR_Rq : 7|5@0+ (1,0) [0|31] "unitless"  GWM
 SG_ NextUsageTimeToggle_Rq : 15|2@0+ (1,0) [0|3] "SED"  GWM
 SG_ LongTermParking_Rq : 17|2@0+ (1,0) [0|3] "SED"  GWM
 SG_ CbnCmrtPrefLstNmItm_Rq : 31|8@0+ (1,0) [0|255] "unitless"  GWM
 SG_ CbnCmrtPrefListIndx_Rq : 39|8@0+ (1,0) [0|255] "unitless"  GWM
 SG_ ModemReset_D_Rq : 45|4@0+ (1,0) [0|15] "SED"  GWM
 SG_ StopStrtDrvMde_B_RqBtn3 : 23|1@0+ (1,0) [0|1] "SED"  GWM
 SG_ AudioToneTouchY_D_Rq : 63|8@0+ (1,0) [0|255] "SED"  DSP,GWM
 SG_ AudioToneTouchX_D_Rq : 55|8@0+ (1,0) [0|255] "SED"  DSP,GWM
 SG_ TCU_ESN_D_Rq : 22|2@0+ (1,0) [0|3] "SED"  GWM
 SG_ FactoryReset_Rq : 18|1@0+ (1,0) [0|1] "SED"  GWM
 SG_ OffPeakTimeSetType_Rq : 2|3@0+ (1,0) [0|7] "SED"  GWM
 SG_ AudioToneTouch_D_Rq : 41|2@0+ (1,0) [0|3] "SED"  DSP,GWM

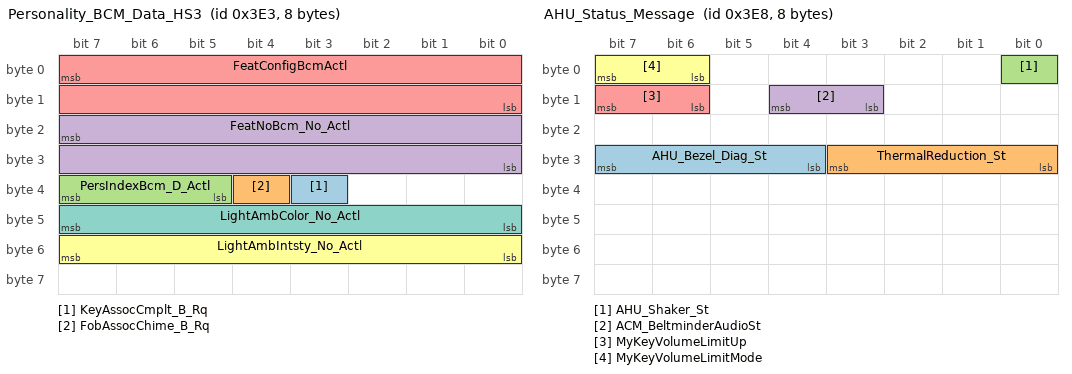
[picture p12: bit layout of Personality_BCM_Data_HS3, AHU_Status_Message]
BO_ 995 Personality_BCM_Data_HS3: 8 GWM
 SG_ KeyAssocCmplt_B_Rq : 35|1@0+ (1,0) [0|1] "SED"  APIM_CDC,APIM_CIM,IPC
 SG_ FobAssocChime_B_Rq : 36|1@0+ (1,0) [0|1] "SED"  APIM_CDC,APIM_CIM,IPC
 SG_ PersIndexBcm_D_Actl : 39|3@0+ (1,0) [0|7] "SED"  APIM_CDC,APIM,APIM_CISM,APIM_CIM,IPC
 SG_ FeatNoBcm_No_Actl : 23|16@0+ (1,0) [0|65535] "Number"  APIM_CDC,APIM,APIM_CISM,APIM_CIM,IPC
 SG_ FeatConfigBcmActl : 7|16@0+ (1,0) [0|65535] "Undefined"  APIM_CDC,APIM,APIM_CISM,APIM_CIM,IPC
 SG_ LightAmbIntsty_No_Actl : 55|8@0+ (1,0) [0|255] "unitless"  APIM_CDC,APIM,APIM_CIM,APIM_CISM
 SG_ LightAmbColor_No_Actl : 47|8@0+ (1,0) [0|255] "Discrete"  APIM_CDC,APIM,APIM_CIM,APIM_CISM

BO_ 753 Vehicle_Stat: 8 APIM_CIM
 SG_ RollCodeValet : 7|16@0+ (1,0) [0|65535] "unitless"  GWM

BO_ 1000 AHU_Status_Message: 8 APIM_CIM
 SG_ AHU_Bezel_Diag_St : 31|4@0+ (1,0) [0|15] "SED"  APIM_CDC,APIM
 SG_ ThermalReduction_St : 27|4@0+ (1,0) [0|15] "SED"  DSP
 SG_ AHU_Shaker_St : 0|1@0+ (1,0) [0|1] "SED"  APIM_CDC,APIM,GWM
 SG_ ACM_BeltminderAudioSt : 12|2@0+ (1,0) [0|3] "SED"  APIM_CDC,APIM,IPC
 SG_ MyKeyVolumeLimitUp : 15|2@0+ (1,0) [0|3] "SED"  APIM_CDC,APIM
 SG_ MyKeyVolumeLimitMode : 7|2@0+ (1,0) [0|3] "SED"  APIM_CDC,APIM

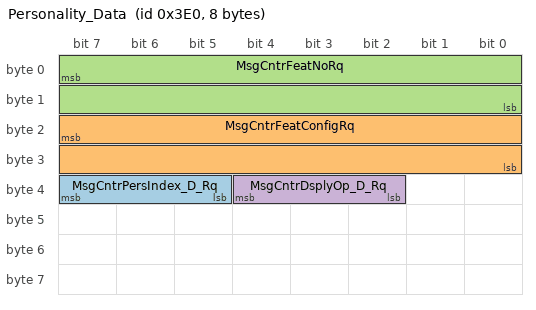
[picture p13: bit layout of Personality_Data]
BO_ 992 Personality_Data: 8 IPC
 SG_ MsgCntrPersIndex_D_Rq : 39|3@0+ (1,0) [0|7] "SED"  HUD_ADV,GWM
 SG_ MsgCntrFeatConfigRq : 23|16@0+ (1,0) [0|65535] "unitless"  HUD_ADV,GWM
 SG_ MsgCntrFeatNoRq : 7|16@0+ (1,0) [0|65535] "Number"  HUD_ADV,GWM
 SG_ MsgCntrDsplyOp_D_Rq : 36|3@0+ (1,0) [0|7] "SED"  HUD_ADV,GWM

BO_TX_BU_ 486 : ACM,APIM_CISM,APIM_CIM;
BO_TX_BU_ 553 : APIM_CDC,APIM_CIM,APIM_CISM,APIM;
BO_TX_BU_ 739 : APIM_CDC,APIM_CIM,APIM_CISM,APIM;
BO_TX_BU_ 1009 : APIM_CDC,APIM_CIM,APIM_CISM,APIM;
BO_TX_BU_ 549 : APIM_CDC,APIM_CIM,IPC;
BO_TX_BU_ 765 : APIM_CDC,APIM_CIM,IPC;
BO_TX_BU_ 508 : APIM_CDC,IPC;
BO_TX_BU_ 507 : APIM_CDC,IPC;
BO_TX_BU_ 506 : APIM_CDC,IPC;
BO_TX_BU_ 505 : APIM_CDC,IPC;
BO_TX_BU_ 403 : APIM_CDC,IPC;
BO_TX_BU_ 401 : APIM_CDC,APIM_CIM,APIM_CISM,APIM;
BO_TX_BU_ 405 : APIM_CDC,IPC;
BO_TX_BU_ 756 : APIM_CDC,APIM_CIM,IPC;
BO_TX_BU_ 544 : APIM_CDC,APIM_CIM,IPC;
BO_TX_BU_ 400 : APIM_CDC,IPC;
BO_TX_BU_ 261 : APIM,APIM_CDC,APIM_CIM,APIM_CISM,ACM;
BO_TX_BU_ 753 : APIM,APIM_CDC,APIM_CISM,APIM_CIM;
BO_TX_BU_ 1000 : ACM,APIM_CISM,APIM_CIM;
BO_TX_BU_ 992 : APIM_CDC,APIM_CIM,IPC;
CM_ SG_ 935 Side_Detect_R_Illum "DDMGenSigTimeoutTime=2000";
CM_ SG_ 935 SodRight_D_Stat "IPCGenSigTimeoutTime=1600";
CM_ SG_ 935 SodSnsRight_D_Stat "IPCGenSigTimeoutTime=1600";
CM_ SG_ 935 SodAlrtRight_D_Stat "DDMGenSigTimeoutTime=2000";
CM_ SG_ 934 Side_Detect_L_Illum "DDMGenSigTimeoutTime=2000";
CM_ SG_ 934 SodLeft_D_Stat "IPCGenSigTimeoutTime=1600";
CM_ SG_ 934 SodSnsLeft_D_Stat "IPCGenSigTimeoutTime=1600";
CM_ SG_ 934 SodAlrtLeft_D_Stat "DDMGenSigTimeoutTime=2000";
CM_ BO_ 486 "ACM Tx";
CM_ SG_ 486 ACU_ARAudioSource_Rsp "Object Audio Management AudioClient.AudioRequest.Requested Audio Source";
CM_ SG_ 486 ACU_AROperationType_Rsp "Object Audio Management AudioClient.AudioRequest.Operation Type";
CM_ SG_ 486 ACU_ARReqstrSystem_Rsp "Object Audio Management AudioClient.AudioRequest.Requester System";
CM_ SG_ 486 ACU_ARResponse_Rsp "Object Audio Management AudioClient.AudioRequest.Response";
CM_ SG_ 486 ACU_ARReqstrPriority_Rp "AR = Audio Request (this signal belongs to the logical signal AudioRequest.Rsp)
Object = AudioClient
Logical Signal = AudioRequest
Parameter = Requester Priority

Disc shall be used for both CD and MC";
CM_ SG_ 486 ACU_RUAudioSource_St "Object Audio Management Audio Client.ResourceUpdate.Requested Audio Source
";
CM_ SG_ 486 ACU_RUReqstrSystem_St "Object Audio Management Audio Client.ResourceUpdate.Requester System";
CM_ SG_ 486 ACU_RUResReqstStatus_St "Object Audio Management Audio Client.ResourceUpdate.Resource Request Status";
CM_ SG_ 486 ACU_RUReqstrPriority_St "Object Audio Management Audio Client.ResourceUpdate.Requester Priority";
CM_ BO_ 553 "FCDIM, APIM Tx";
CM_ SG_ 553 SndImmrsnLvl_D_Rq "ImmersionLevel_D_Rq";
CM_ SG_ 553 Disp_LangSel2_St "Reference GSDB for encoding: 009522/B;2-ZZ_LangSel";
CM_ SG_ 553 Disp_LangSel_St "Object.VehicleSettings.Disp_LangSel.St.Language";
CM_ SG_ 553 Diagnostic_Operation_Rq "Object:BezelDiagnostics.MFD_Bezel_Diagnostic.St";
CM_ SG_ 553 Bezel_Diag_Module_Rq "Object:BezelDiagnostics.MFD_Bezel_Diagnostic.St";
CM_ SG_ 553 Audio_Demo_CMND "Object. AudioSettings.Audio Demo_CMND";
CM_ SG_ 553 Audio_Visualizer "Object.AudioSettings.Audio_Visualizer
";
CM_ SG_ 553 Surround_Sound_Upmix "Object.AudioSettings.Surround_Sound_Upmix

";
CM_ SG_ 553 Bezel_Diag_State_Rq "Object:BezelDiagnostics.MFD_Bezel_Diagnostic.Rq";
CM_ SG_ 553 SurndSndUpmix2_D_Rq "Object:Surround_Sound_Upmix2_Rq";
CM_ BO_ 739 "FCDIM Tx";
CM_ SG_ 739 Partial_Amp_Shutdown "Method Partial_Amp_Shutdown";
CM_ SG_ 739 HMI_HMIMode_St "Object ACU System Master.HMIMode
OR
Object NAV System Master.HMIMode

Refer Method HMIAudioMode in the SPSS";
CM_ BO_ 1009 "APIM Tx";
CM_ SG_ 1009 CenterStackRing_D_Actl "The Center Stack sends the CPLR a signal to turn On or Off the light Ring, This is a customer selectable preference switch";
CM_ SG_ 1009 APIM_NumberofTracks_St "Object NumberofTracks";
CM_ SG_ 1009 APIM_ActiveTrackNum_St "Object.ActiveTrackNum";
CM_ BO_ 531 "IC is NOT to use data in this message for displays, Used data from 415 instead.";
CM_ SG_ 531 VehLongOvrGnd_A_Est "CCMGenSigTimeoutTime=1000";
CM_ SG_ 702 PHONE_MC_WORD_Rx "MM ISO 15765-2 Message Catalogue
Section MC - PHONE";
CM_ SG_ 711 MyKeySrvr_Clnt_Word_Tx "TP-LOG-GTPC-201379-SID-7C";
CM_ BO_ 549 "Method IPC _Infotainment";
CM_ SG_ 549 BeltminderAudioMute "Object.MyKey.BeltMinderAudioMute.St";
CM_ SG_ 549 Power_Up_Chime_Modules "Object.AlertMethod.IPC _Infotainment";
CM_ SG_ 549 Chime_Source "Object.AlertMethod.IPC_infotainment";
CM_ SG_ 765 Mc_VehUntTrpCoUsrSel_St "Object.VehicleSettings.Disp_Miles_Kilometers.Rq";
CM_ SG_ 765 Mc_VehUnitTempUsrSel_St "Object.VehicleSettings.Disp_Temperature.Rq";
CM_ SG_ 765 Mc_VehDayNightUsrSel_St "Object.BodyInterface.Settings.VehicleDayNightUserSelection
Object.BodyInterface.Status.AMDayNightSensitivity";
CM_ SG_ 765 Mc_VehTimeFrmtUsrSel_St "Object.BodyInterface.Settings.VehicleTimeFormatUserSelection";
CM_ SG_ 765 Mc_VehThemeUsrSel_St "Object.BodyInterface.Settings.VehicleThemeUserSelection";
CM_ SG_ 765 Mc_VehLangUsrSel_St "Object.BodyInterface.Settings.VehicleLanguageUserSelection
Object Vehicle Settings.Disp_LangSel
";
CM_ SG_ 508 Mc_DB1GetInfStartInd_Rq "Object Media Player iPod.GetMDBInfo.MDBStartItemInd
";
CM_ SG_ 508 Mc_DB1GtInfNbrOfItms_Rq "Object Media Player iPod.GetMDBInfo.MDBNbrOfItems
";
CM_ SG_ 508 Mc_DB1GetInfSetConf_Rq "Object Media Player iPod.GetMDBInfo.MDBSetFilterConf
";
CM_ SG_ 508 Mc_DB1GetInfSetFilt3_Rq "Object Media Player iPod.GetMDBInfo.MDBSetFilter3
";
CM_ SG_ 508 Mc_DB1GetInfSetFilt2_Rq "Object Media Player iPod.GetMDBInfo.MDBSetFilter2
";
CM_ SG_ 508 Mc_DB1GetInfSetFilt1_Rq "Object Media Player iPod.GetMDBInfo.MDBSetFilter1 ";
CM_ SG_ 507 Mc_DB1SetTrkItmIndex_Rq "Object Media Player iPod.MDBSetTrack.MDBItemIndex
";
CM_ SG_ 507 Mc_DB1SetTrkSetConf_Rq "Object Media Player iPod.MDBSetTrack.MDBSetFilterConf";
CM_ SG_ 507 Mc_DB1SetTrkSetFilt3_Rq "Object Media Player iPod.MDBSetTrack.MDBSetFilter3";
CM_ SG_ 507 Mc_DB1SetTrkSetFilt2_Rq "Object Media Player iPod.MDBSetTrack.MDBSetFilter2";
CM_ SG_ 507 Mc_DB1SetTrkSetFilt1_Rq "Object Media Player iPod.MDBSetTrack.MDBSetFilter1";
CM_ SG_ 506 Mc_AudioSourceSel3_Rq "Object Media Player BTAudio.GetDetailedMPInfo.AudioSource
Object Media Player BTAudio.PlayFirstTrackInFolder.AudioSource
Object Media Player USB.GetDetailedMPInfo.AudioSource
Object Media Player USB.PlayFirstTrackInFolder.AudioSource";
CM_ SG_ 506 Mc_PlayFrstTrInFldr_Rq "Object Media Player BTAudio.PlayFirstTrackInFolder.FolderNumber
Object Media Player USB.PlayFirstTrackinFolder.FolderNumber

$FFFF: Inactive";
CM_ SG_ 506 Mc_ItemIndex_Rq "Object Media Player BTAudio.GetDetailedMPInfo.ItemIndex
Object Media Player USB.GetDetailedMPInfo.ItemIndex";
CM_ SG_ 506 Mc_FolderNumber3_Rq "Object Media Player BTAudio.GetDetailedMPInfo.FolderNumber
Object Media Player USB.GetDetailedMPInfo.FolderNumber";
CM_ SG_ 505 Mc_AudioSourceSel2_Rq "Object Media Player BTAudio.GetMPInfo.AudioSouce
Object Media Player USB.GetMPInfo.AudioSouce
Object Media Player SDCard.GetMPInfo.AudioSouce";
CM_ SG_ 505 Mc_StartItemIndexRq "Object Media Player BTAudio.GetMPInfo.StartingItemIndex
Object Media Player USB.GetMPInfo.StartingItemIndex
Object Media Player SDCard.GetMPInfo.StartingItemIndex

$FFFF: Inactive";
CM_ SG_ 505 Mc_NbrOfItems2_Rq "Object Media Player BTAudio.GetMPInfo.NbrOfItems
Object Media Player USB.GetMPInfo.NbrOfItems
Object Media Player SDCard.GetMPInfo.NbrOfItems";
CM_ SG_ 505 Mc_ItemNameLength2_Rq "Object Media Player BTAudio.GetMPInfo.ItemNameLength
Object Media Player USB.GetMPInfo.ItemNameLength
Object Media Player SDCard.GetMPInfo.ItemNameLength";
CM_ SG_ 505 Mc_CutItem2_Rq "Object Media Player BTAudio.GetMPInfo.CutItemName
Object Media Player USB.GetMPInfo.CutItemName
Object Media Player SDCard.GetMPInfo.CutItemName";
CM_ SG_ 505 Mc_FolderNumber2_Rq "Object Media Player BTAudio.GetMPInfo.FolderNumber 
Object Media Player USB.GetMPInfo.FolderNumber
Object Media Player SDCard.GetMPInfo.FolderNumber

$FFFF: Inactive";
CM_ SG_ 505 Mc_FolderContent_Rq "Object Media Player USB.GetMPInfo.FolderContent
Object Media Player SDCard.GetMPInfo.FolderContent

Note: Value table entries were truncated from:
$0: RequestContentFromParameterFolderNumber
$1: RequestContentFromParentFolderOfParameterFolderNumber";
CM_ SG_ 403 Mc_RepeatGuidance_Rq "Object.NavigationRepeater.Guidance_Repeat.Rq.RepeatGuidance";
CM_ SG_ 403 Mc_CancelRoute_Rq "Object.NavigationRepater.CancelRoute.Rq.CancelRoute";
CM_ SG_ 403 Mc_CancelCurrWaypt_Rq "Object.NavigationRepeater.CancelCurrentWayPoint.Rq.Cancelwaypoint";
CM_ SG_ 403 Mc_TextMessage_Rq "Object. BTPhoneClient.TextMessage.Rq";
CM_ SG_ 403 Mc_BTInCallOptions_Rq "Object.BTPhoneClient.BTInCallOptions.Rq.SingleParam";
CM_ SG_ 403 Mc_PhMicrophoneMute_Rq "Object Blueetoth Phone.PhMicrophoneMute";
CM_ SG_ 403 Mc_LangSel_Rq "Object.VehicleSettings.Disp_LangSel.Rq.Language";
CM_ BO_ 401 "APIM Tx";
CM_ SG_ 401 Bezel_Beeps_Rq "Vehicle Settings";
CM_ SG_ 401 Disp_VehUntTripCoUsrSel "Obect.VehicleSettings.Disp_Miles_Kilometers.Rq.Mode";
CM_ SG_ 401 Disp_VehUnitTempUsrSel "Obect.VehicleSettings.Disp_Temperature.Rq.Mode";
CM_ SG_ 401 Disp_LangSel_Rq "Object.VehicleSettings.Disp_LangSel.Rq.Language";
CM_ SG_ 401 Disp_LangSel2_Rq "Reference GSDB for encoding: 009522/B;2-ZZ_LangSel";
CM_ SG_ 405 LBC1_StartItemInd "Object. ListBrowser.ItemInf.Rq.StartItemInd
0x0000:Inactive
0x0001:1
0xFFFE:65634
0xFFFF:Reserved";
CM_ SG_ 405 LBC1_SetListServ "Object. ListBrowser.ItemInf.Rq.SetListServ
0x00:Inactive
0x01:ServerID_1
0xFF:ALL";
CM_ SG_ 405 LBC1_Opcode "Object. ListBrowser.ItemInf.Rq.Opcode";
CM_ SG_ 405 LBC1_NbrOfItems "Object. ListBrowser.ItemInf.Rq.NbrOfItems
0x00:Inactive
0x01:1Item
0x3F:63Items";
CM_ SG_ 405 LBC1_ItemIndex "Object. ListBrowser.ItemInf.Rq.ItemIndex
0x0000:BrowseActiveListID
0x0001:EntryIndex_1
0xFFFF:ParentOfActiveListID";
CM_ SG_ 405 LBC1_ActiveListID "Object. ListBrowser.ItemInf.Rq.ActiveListID
0x0000:Root
0xFFFF:Reserved";
CM_ BO_ 756 "IPC_Chime2";
CM_ SG_ 756 Off_Time_Btwn_Chime2 "Object.AlertMethod.IPC_Chime
0x0 Inactive
0x1 Continuously (repeat continuously) 
0x2 5 msec
0x3 10 msec
0x4 15 msec
0x5 20 msec
0x6 40 msec
0x7 60 msec (increment is 20 msec steps until 800 msec)
cont....Refer SPSS for rest of encodings";
CM_ SG_ 756 Chime_Vol_Level2 "Object.AlertMethod. IPC_Chime
0x0 Inactive (no change to stored chime volume - 100% of stored chime volume)
0x1 99% (of stored chime volume)
....
0x63 1% (of stored chime volume)
0x64 Reserved";
CM_ SG_ 756 Chime_Time_Criticality2 "Object.AlertMethod. IPC_Chime";
CM_ SG_ 756 Chime_Occurence2 "Object.AlertMethod. IPC_Chime";
CM_ SG_ 756 Chime_Directionality2 "Object.AlertMethod. IPC_Chime";
CM_ SG_ 756 Chime2 "Object.AlertMethod. IPC_Chime
0x0 No_Chime  (note: if >No Chime< is selected then ignore other signals in this message)
0x1 Chime_1
0x2 Chime_2
0x3 Chime_3
cont.
0x3F Chime_63

";
CM_ BO_ 544 "Method IPC_Chime";
CM_ SG_ 544 Chime_Occurence "Object.AlertMethod. IPC_Chime";
CM_ SG_ 544 Off_Time_Btwn_Chime "Object.AlertMethod.IPC_Chime
0x0 Inactive
0x1 Continuously (repeat continuously) 
0x2 5 msec
0x3 10 msec
0x4 15 msec
0x5 20 msec
0x6 40 msec
0x7 60 msec (increment is 20 msec steps until 800 msec)
cont....Refer SPSS for rest of the encodings.
";
CM_ SG_ 544 Chime_Time_Criticality "Object.AlertMethod. IPC_Chime";
CM_ SG_ 544 Chime_Directionality "Object.AlertMethod. IPC_Chime";
CM_ SG_ 544 Chime_Vol_Level "Object.AlertMethod. IPC_Chime
0x0 Inactive (no change to stored chime volume - 100% of stored chime volume)
0x1 99% (of stored chime volume)
....
0x63 1% (of stored chime volume)
0x64 Reserved";
CM_ SG_ 544 Chime "Object.AlertMethod. IPC_Chime
0x0 No_Chime  (note: if >No Chime< is selected then ignore other signals in this message)
0x1 Chime_1
0x2 Chime_2
0x3 Chime_3
cont.
0x3F Chime_63
";
CM_ SG_ 291 LangUpdate_Rsp "Object. LanguageUpdate.Rsp";
CM_ SG_ 400 Mc_SetCurrntStatFreq_Rq "Object Tuner.SetCurrentStat.Request.Frequency

AM: Freq = 153+ Offset kHz.
Offset 0..1557

FM: Freq = 76+ Offset*0.05 MHz. Offset 0..640
Selected tuned band determine frequency (kHz or MHz).";
CM_ SG_ 400 Mc_SetCurrStatMCCh_Rq "Object Tuner.SetCurrentStation.MCChannel";
CM_ SG_ 400 Mc_SetCurrentStatOp_Rq "Object Tuner.SetCurrentStat.Request.Operation";
CM_ SG_ 400 Mc_PerTUStartIndex2_Rq "Object Personalization. DAB.GetTUPresetInfo.StartIndex2

$1-$FF: Preset 1 to 255";
CM_ SG_ 400 Mc_PerTUPresetArea_Rq "Object Personalization.DAB.GetTUPresetInfo.PresetArea

$5: Get AMAST (MW) Preset Data
$6: Get AM (LW) Preset Data";
CM_ SG_ 400 Mc_PerTUNbrOfPresets_Rq "Object Personalization. DAB.GetTUPresetInfo.NumberOfPresets

$1-$1E: Preset 1 to 30";
CM_ SG_ 647 HEC_BTIncomingCall_Rq "Object Bluetooth Phone.BTIncomingCall";
CM_ SG_ 647 HEC_BTEndTelService_Rq "Object Bluetooth Phone.BTEndTelService";
CM_ SG_ 359 TrnAin_Tq_Actl "Signal not transmitted on HEV variances.";
CM_ SG_ 359 PlgActvArb_B_Actl "Only supported on PHEV programs.  PlgActvArb_B_Actl HPCM will Tx on Powersplit PHEV’s,  On MHT PHEVs the PCM_HEV will Tx and HPCM will Rx. 
";
CM_ SG_ 359 TrnAinTq_D_Qf "Signal not transmitted on HEV variances.";
CM_ SG_ 1091 PoliceAux4Lamp_B_Rq2 "Signal not transmitted on programs that do not have AWD.";
CM_ SG_ 1091 PoliceAux3Lamp_B_Rq2 "Signal not transmitted on programs that do not have AWD.";
CM_ SG_ 1091 PoliceAux2Lamp_B_Rq2 "Signal not transmitted on programs that do not have AWD.";
CM_ SG_ 1091 PoliceAux1Lamp_B_Rq2 "Signal not transmitted on programs that do not have AWD.";
CM_ SG_ 261 OffPeakTimeSetType_Rq "Object:OffPeakTimeSet_Rq";
CM_ BO_ 753 "APIM Tx";
CM_ SG_ 1000 AHU_Bezel_Diag_St "Object:BezelDiagnostics.AHU_Bezel_Diag.St";
CM_ SG_ 1000 AHU_Shaker_St "Object:AudioSettings.AHU_Shaker ";
CM_ SG_ 1000 ACM_BeltminderAudioSt "Method: BeltminderAudioIsMuted";
CM_ SG_ 1000 MyKeyVolumeLimitUp "Method MykeyvolumeIsLimited:VolumeUpdate";
CM_ SG_ 1000 MyKeyVolumeLimitMode "Method MykeyvolumeIsLimited: Mode";
BA_DEF_ BO_  "FrameRouting" STRING ;
BA_DEF_ BO_  "NetworkInitialization" ENUM  "No","Yes";
BA_DEF_ BO_  "GenMsgStartDelayTime" INT 0 10000;
BA_DEF_ BO_  "GenMsgNrOfRepetition" INT 0 100;
BA_DEF_ BO_  "GenMsgDelayTime" INT 0 1000;
BA_DEF_ BO_  "GenMsgCycleTime" INT 0 100000;
BA_DEF_ BO_  "GenMsgSendType" ENUM  "FixedPeriodic","Event","EnabledPeriodic","NotUsed","NotUsed","EventPeriodic","NotUsed","NotUsed","NoMsgSendType";
BA_DEF_ SG_  "U_P702_MY2024_Tx" ENUM  "No","Yes";
BA_DEF_ SG_  "U_V710_MY2023_Tx" ENUM  "No","Yes";
BA_DEF_ SG_  "U_CDX74X_MY2024_Tx" ENUM  "No","Yes";
BA_DEF_ SG_  "U_CDX707_MY2023_Tx" ENUM  "No","Yes";
BA_DEF_ SG_  "U_P708_MY2023_Tx" ENUM  "No","Yes";
BA_DEF_ SG_  "U_V713AV_MY2022_Tx" ENUM  "No","Yes";
BA_DEF_ SG_  "U_V713N_MY2022_Tx" ENUM  "No","Yes";
BA_DEF_ SG_  "ECGUsedTxSignal" ENUM  "No","Yes";
BA_DEF_ SG_  "U_P702_MY2024_Rx" ENUM  "No","Yes";
BA_DEF_ SG_  "U_V710_MY2023_Rx" ENUM  "No","Yes";
BA_DEF_ SG_  "U_CDX74X_MY2024_Rx" ENUM  "No","Yes";
BA_DEF_ SG_  "U_CDX707_MY2023_Rx" ENUM  "No","Yes";
BA_DEF_ SG_  "U_P708_MY2023_Rx" ENUM  "No","Yes";
BA_DEF_ SG_  "U_V713AV_MY2022_Rx" ENUM  "No","Yes";
BA_DEF_ SG_  "U_V713N_MY2022_Rx" ENUM  "No","Yes";
BA_DEF_ SG_  "ECGUsedRxSignal" ENUM  "No","Yes";
BA_DEF_ SG_  "UsedOnPgmDBC" ENUM  "No","Yes";
BA_DEF_ SG_  "ContentDependant" ENUM  "No","Yes";
BA_DEF_ SG_  "GenSigStartValue" HEX 0 268435455;
BA_DEF_ SG_  "MetaData" ENUM  "No","Yes";
BA_DEF_ SG_  "WakeupSignal" ENUM  "No","Yes";
BA_DEF_ SG_  "GenSigInactiveValue" INT 0 100000;
BA_DEF_ SG_  "GenSigSendType" ENUM  "Cyclic","OnWrite","vector_leerstring","OnChange","vector_leerstring","IfActive","vector_leerstring","NoSigSendType";
BA_DEF_ BO_  "TpTxIndex" INT 0 536870911;
BA_DEF_ BO_  "OvtpPushApplication" ENUM  "FALSE","TRUE";
BA_DEF_ BO_  "SCP_FreshnessValueLength" INT 0 512;
BA_DEF_ BO_  "SCP_DataId" INT 0 17663;
BA_DEF_ BO_  "SCP_FreshnessValueTxLength" INT 0 512;
BA_DEF_ BO_  "SCP_AuthInfoTxLength" INT 0 512;
BA_DEF_ BO_  "SC_Message" ENUM  "No","Yes";
BA_DEF_ BO_  "GenMsgRoutingTimeoutTime" INT 0 5000;
BA_DEF_ BO_  "MessageGateway" ENUM  "No","Yes";
BA_DEF_ BO_  "NmAsrMessage" ENUM  "No","Yes";
BA_DEF_ BO_  "DiagState" ENUM  "No","Yes";
BA_DEF_ BO_  "DiagRequest" ENUM  "No","Yes";
BA_DEF_ BO_  "DiagResponse" ENUM  "No","Yes";
BA_DEF_ BO_  "NmMessage" ENUM  "No","Yes";
BA_DEF_ BO_  "GenMsgILSupport" ENUM  "No","Yes";
BA_DEF_DEF_  "FrameRouting" "";
BA_DEF_DEF_  "NetworkInitialization" "Yes";
BA_DEF_DEF_  "GenMsgStartDelayTime" 0;
BA_DEF_DEF_  "GenMsgNrOfRepetition" 1;
BA_DEF_DEF_  "GenMsgDelayTime" 20;
BA_DEF_DEF_  "GenMsgCycleTime" 0;
BA_DEF_DEF_  "GenMsgSendType" "NoMsgSendType";
BA_DEF_DEF_  "U_P702_MY2024_Tx" "No";
BA_DEF_DEF_  "U_V710_MY2023_Tx" "No";
BA_DEF_DEF_  "U_CDX74X_MY2024_Tx" "No";
BA_DEF_DEF_  "U_CDX707_MY2023_Tx" "No";
BA_DEF_DEF_  "U_P708_MY2023_Tx" "No";
BA_DEF_DEF_  "U_V713AV_MY2022_Tx" "No";
BA_DEF_DEF_  "U_V713N_MY2022_Tx" "No";
BA_DEF_DEF_  "ECGUsedTxSignal" "No";
BA_DEF_DEF_  "U_P702_MY2024_Rx" "No";
BA_DEF_DEF_  "U_V710_MY2023_Rx" "No";
BA_DEF_DEF_  "U_CDX74X_MY2024_Rx" "No";
BA_DEF_DEF_  "U_CDX707_MY2023_Rx" "No";
BA_DEF_DEF_  "U_P708_MY2023_Rx" "No";
BA_DEF_DEF_  "U_V713AV_MY2022_Rx" "No";
BA_DEF_DEF_  "U_V713N_MY2022_Rx" "No";
BA_DEF_DEF_  "ECGUsedRxSignal" "No";
BA_DEF_DEF_  "UsedOnPgmDBC" "Yes";
BA_DEF_DEF_  "ContentDependant" "No";
BA_DEF_DEF_  "GenSigStartValue" 0;
BA_DEF_DEF_  "MetaData" "No";
BA_DEF_DEF_  "WakeupSignal" "No";
BA_DEF_DEF_  "GenSigInactiveValue" 0;
BA_DEF_DEF_  "GenSigSendType" "NoSigSendType";
BA_DEF_DEF_  "TpTxIndex" 0;
BA_DEF_DEF_  "OvtpPushApplication" "FALSE";
BA_DEF_DEF_  "SCP_FreshnessValueLength" 64;
BA_DEF_DEF_  "SCP_DataId" 0;
BA_DEF_DEF_  "SCP_FreshnessValueTxLength" 11;
BA_DEF_DEF_  "SCP_AuthInfoTxLength" 53;
BA_DEF_DEF_  "SC_Message" "No";
BA_DEF_DEF_  "GenMsgRoutingTimeoutTime" 0;
BA_DEF_DEF_  "MessageGateway" "No";
BA_DEF_DEF_  "NmAsrMessage" "No";
BA_DEF_DEF_  "DiagState" "No";
BA_DEF_DEF_  "DiagRequest" "No";
BA_DEF_DEF_  "DiagResponse" "No";
BA_DEF_DEF_  "NmMessage" "No";
BA_DEF_DEF_  "GenMsgILSupport" "Yes";
BA_ "FrameRouting" BO_ 935 "FD1_CAN,0x3A7;FD3_CAN,0x3A7";
BA_ "FrameRouting" BO_ 934 "FD1_CAN,0x3A6;FD3_CAN,0x3A6";
BA_ "GenMsgSendType" BO_ 486 1;
BA_ "GenMsgSendType" BO_ 553 5;
BA_ "GenMsgCycleTime" BO_ 553 1000;
BA_ "GenMsgSendType" BO_ 739 5;
BA_ "GenMsgCycleTime" BO_ 739 1000;
BA_ "GenMsgSendType" BO_ 1009 5;
BA_ "GenMsgCycleTime" BO_ 1009 1000;
BA_ "FrameRouting" BO_ 531 "FD1_CAN,0x213;";
BA_ "TpTxIndex" BO_ 702 17;
BA_ "NetworkInitialization" BO_ 702 0;
BA_ "TpTxIndex" BO_ 711 24;
BA_ "NetworkInitialization" BO_ 711 0;
BA_ "GenMsgSendType" BO_ 549 5;
BA_ "GenMsgCycleTime" BO_ 549 1000;
BA_ "GenMsgSendType" BO_ 765 5;
BA_ "GenMsgCycleTime" BO_ 765 1000;
BA_ "GenMsgSendType" BO_ 508 1;
BA_ "NetworkInitialization" BO_ 508 0;
BA_ "GenMsgSendType" BO_ 507 1;
BA_ "NetworkInitialization" BO_ 507 0;
BA_ "GenMsgSendType" BO_ 506 1;
BA_ "NetworkInitialization" BO_ 506 0;
BA_ "GenMsgSendType" BO_ 505 1;
BA_ "NetworkInitialization" BO_ 505 0;
BA_ "GenMsgSendType" BO_ 403 1;
BA_ "NetworkInitialization" BO_ 403 0;
BA_ "GenMsgSendType" BO_ 401 1;
BA_ "FrameRouting" BO_ 1143 "FD1_CAN,0x477;";
BA_ "FrameRouting" BO_ 1142 "FD1_CAN,0x476;";
BA_ "FrameRouting" BO_ 973 "FD1_CAN,0x3CD;FD3_CAN,0x3CD";
BA_ "GenMsgSendType" BO_ 405 1;
BA_ "NetworkInitialization" BO_ 405 0;
BA_ "GenMsgSendType" BO_ 756 5;
BA_ "GenMsgCycleTime" BO_ 756 1000;
BA_ "GenMsgSendType" BO_ 544 5;
BA_ "GenMsgCycleTime" BO_ 544 1000;
BA_ "GenMsgSendType" BO_ 291 1;
BA_ "NetworkInitialization" BO_ 291 0;
BA_ "GenMsgSendType" BO_ 400 1;
BA_ "NetworkInitialization" BO_ 400 0;
BA_ "GenMsgSendType" BO_ 647 5;
BA_ "GenMsgCycleTime" BO_ 647 200;
BA_ "GenMsgDelayTime" BO_ 359 0;
BA_ "FrameRouting" BO_ 359 "FD1_CAN,0x167;";
BA_ "FrameRouting" BO_ 990 "FD3_CAN,0x3DE;";
BA_ "FrameRouting" BO_ 989 "FD1_CAN,0x3DD;FD3_CAN,0x3DD";
BA_ "GenMsgSendType" BO_ 1091 5;
BA_ "GenMsgCycleTime" BO_ 1091 1000;
BA_ "FrameRouting" BO_ 1045 "FD1_CAN,0x415;";
BA_ "GenMsgILSupport" BO_ 1439 0;
BA_ "NmAsrMessage" BO_ 1439 1;
BA_ "GenMsgSendType" BO_ 1439 0;
BA_ "GenMsgCycleTime" BO_ 1439 1000;
BA_ "NetworkInitialization" BO_ 1439 0;
BA_ "GenMsgSendType" BO_ 261 1;
BA_ "FrameRouting" BO_ 995 "FD1_CAN,0x3E3;";
BA_ "GenMsgSendType" BO_ 753 5;
BA_ "GenMsgCycleTime" BO_ 753 1000;
BA_ "GenMsgSendType" BO_ 1000 5;
BA_ "GenMsgCycleTime" BO_ 1000 1000;
BA_ "GenMsgSendType" BO_ 992 5;
BA_ "GenMsgCycleTime" BO_ 992 1000;
BA_ "U_V713N_MY2022_Rx" SG_ 935 CtaAlrtRight2_D_Stat 1;
BA_ "U_V713AV_MY2022_Rx" SG_ 935 CtaAlrtRight2_D_Stat 1;
BA_ "U_V710_MY2023_Rx" SG_ 935 CtaAlrtRight2_D_Stat 1;
BA_ "U_P708_MY2023_Rx" SG_ 935 CtaAlrtRight2_D_Stat 1;
BA_ "U_P702_MY2024_Rx" SG_ 935 CtaAlrtRight2_D_Stat 1;
BA_ "U_V713N_MY2022_Rx" SG_ 935 BttRight_D_Stat 1;
BA_ "U_V713AV_MY2022_Rx" SG_ 935 BttRight_D_Stat 1;
BA_ "U_P708_MY2023_Rx" SG_ 935 BttRight_D_Stat 1;
BA_ "U_V710_MY2023_Rx" SG_ 935 BttRight_D_Stat 1;
BA_ "U_P702_MY2024_Rx" SG_ 935 BttRight_D_Stat 1;
BA_ "U_V713N_MY2022_Rx" SG_ 935 BttRight_D_RqDrv 1;
BA_ "U_V713AV_MY2022_Rx" SG_ 935 BttRight_D_RqDrv 1;
BA_ "U_P708_MY2023_Rx" SG_ 935 BttRight_D_RqDrv 1;
BA_ "U_V710_MY2023_Rx" SG_ 935 BttRight_D_RqDrv 1;
BA_ "U_P702_MY2024_Rx" SG_ 935 BttRight_D_RqDrv 1;
BA_ "U_V713N_MY2022_Rx" SG_ 935 CtaBrkRightMsgTxt_B_Rq 1;
BA_ "U_V713AV_MY2022_Rx" SG_ 935 CtaBrkRightMsgTxt_B_Rq 1;
BA_ "U_P708_MY2023_Rx" SG_ 935 CtaBrkRightMsgTxt_B_Rq 1;
BA_ "U_V710_MY2023_Rx" SG_ 935 CtaBrkRightMsgTxt_B_Rq 1;
BA_ "U_P702_MY2024_Rx" SG_ 935 CtaBrkRightMsgTxt_B_Rq 1;
BA_ "GenSigStartValue" SG_ 935 Side_Detect_R_Illum 100;
BA_ "U_V713N_MY2022_Rx" SG_ 935 Side_Detect_R_Illum 1;
BA_ "U_V713AV_MY2022_Rx" SG_ 935 Side_Detect_R_Illum 1;
BA_ "U_P708_MY2023_Rx" SG_ 935 Side_Detect_R_Illum 1;
BA_ "U_V710_MY2023_Rx" SG_ 935 Side_Detect_R_Illum 1;
BA_ "U_P702_MY2024_Rx" SG_ 935 Side_Detect_R_Illum 1;
BA_ "U_V713N_MY2022_Rx" SG_ 935 CtaSnsRight_D_Stat 1;
BA_ "U_V713AV_MY2022_Rx" SG_ 935 CtaSnsRight_D_Stat 1;
BA_ "U_P708_MY2023_Rx" SG_ 935 CtaSnsRight_D_Stat 1;
BA_ "U_V710_MY2023_Rx" SG_ 935 CtaSnsRight_D_Stat 1;
BA_ "U_P702_MY2024_Rx" SG_ 935 CtaSnsRight_D_Stat 1;
BA_ "U_V713N_MY2022_Rx" SG_ 935 CtaAlrtRight_D_Stat 1;
BA_ "U_V713AV_MY2022_Rx" SG_ 935 CtaAlrtRight_D_Stat 1;
BA_ "U_P708_MY2023_Rx" SG_ 935 CtaAlrtRight_D_Stat 1;
BA_ "U_V710_MY2023_Rx" SG_ 935 CtaAlrtRight_D_Stat 1;
BA_ "U_P702_MY2024_Rx" SG_ 935 CtaAlrtRight_D_Stat 1;
BA_ "U_V713N_MY2022_Rx" SG_ 935 CtaRight_D_Stat 1;
BA_ "U_V713AV_MY2022_Rx" SG_ 935 CtaRight_D_Stat 1;
BA_ "U_P708_MY2023_Rx" SG_ 935 CtaRight_D_Stat 1;
BA_ "U_V710_MY2023_Rx" SG_ 935 CtaRight_D_Stat 1;
BA_ "U_P702_MY2024_Rx" SG_ 935 CtaRight_D_Stat 1;
BA_ "GenSigStartValue" SG_ 935 SodRight_D_Stat 2;
BA_ "U_V713N_MY2022_Rx" SG_ 935 SodRight_D_Stat 1;
BA_ "U_V713AV_MY2022_Rx" SG_ 935 SodRight_D_Stat 1;
BA_ "U_P708_MY2023_Rx" SG_ 935 SodRight_D_Stat 1;
BA_ "U_V710_MY2023_Rx" SG_ 935 SodRight_D_Stat 1;
BA_ "U_P702_MY2024_Rx" SG_ 935 SodRight_D_Stat 1;
BA_ "U_V713N_MY2022_Rx" SG_ 935 SodSnsRight_D_Stat 1;
BA_ "U_V713AV_MY2022_Rx" SG_ 935 SodSnsRight_D_Stat 1;
BA_ "U_P708_MY2023_Rx" SG_ 935 SodSnsRight_D_Stat 1;
BA_ "U_V710_MY2023_Rx" SG_ 935 SodSnsRight_D_Stat 1;
BA_ "U_P702_MY2024_Rx" SG_ 935 SodSnsRight_D_Stat 1;
BA_ "U_V713N_MY2022_Rx" SG_ 935 SodAlrtRight_D_Stat 1;
BA_ "U_V713AV_MY2022_Rx" SG_ 935 SodAlrtRight_D_Stat 1;
BA_ "U_P708_MY2023_Rx" SG_ 935 SodAlrtRight_D_Stat 1;
BA_ "U_V710_MY2023_Rx" SG_ 935 SodAlrtRight_D_Stat 1;
BA_ "U_P702_MY2024_Rx" SG_ 935 SodAlrtRight_D_Stat 1;
BA_ "U_V713N_MY2022_Rx" SG_ 935 SodDetctRight_D_Stat 1;
BA_ "U_V713AV_MY2022_Rx" SG_ 935 SodDetctRight_D_Stat 1;
BA_ "U_P708_MY2023_Rx" SG_ 935 SodDetctRight_D_Stat 1;
BA_ "U_V710_MY2023_Rx" SG_ 935 SodDetctRight_D_Stat 1;
BA_ "U_P702_MY2024_Rx" SG_ 935 SodDetctRight_D_Stat 1;
BA_ "GenSigStartValue" SG_ 935 SodWarnRight_Prd_Rq 14;
BA_ "U_V713N_MY2022_Rx" SG_ 934 CtaAlrtLeft2_D_Stat 1;
BA_ "U_V713AV_MY2022_Rx" SG_ 934 CtaAlrtLeft2_D_Stat 1;
BA_ "U_P708_MY2023_Rx" SG_ 934 CtaAlrtLeft2_D_Stat 1;
BA_ "U_V710_MY2023_Rx" SG_ 934 CtaAlrtLeft2_D_Stat 1;
BA_ "U_P702_MY2024_Rx" SG_ 934 CtaAlrtLeft2_D_Stat 1;
BA_ "U_V713N_MY2022_Rx" SG_ 934 BttLeft_D_Stat 1;
BA_ "U_V713AV_MY2022_Rx" SG_ 934 BttLeft_D_Stat 1;
BA_ "U_P708_MY2023_Rx" SG_ 934 BttLeft_D_Stat 1;
BA_ "U_V710_MY2023_Rx" SG_ 934 BttLeft_D_Stat 1;
BA_ "U_P702_MY2024_Rx" SG_ 934 BttLeft_D_Stat 1;
BA_ "U_V713N_MY2022_Rx" SG_ 934 BttLeft_D_RqDrv 1;
BA_ "U_V713AV_MY2022_Rx" SG_ 934 BttLeft_D_RqDrv 1;
BA_ "U_P708_MY2023_Rx" SG_ 934 BttLeft_D_RqDrv 1;
BA_ "U_V710_MY2023_Rx" SG_ 934 BttLeft_D_RqDrv 1;
BA_ "U_P702_MY2024_Rx" SG_ 934 BttLeft_D_RqDrv 1;
BA_ "U_V713N_MY2022_Rx" SG_ 934 CtaBrkLeftMsgTxt_B_Rq 1;
BA_ "U_V713AV_MY2022_Rx" SG_ 934 CtaBrkLeftMsgTxt_B_Rq 1;
BA_ "U_P708_MY2023_Rx" SG_ 934 CtaBrkLeftMsgTxt_B_Rq 1;
BA_ "U_V710_MY2023_Rx" SG_ 934 CtaBrkLeftMsgTxt_B_Rq 1;
BA_ "U_P702_MY2024_Rx" SG_ 934 CtaBrkLeftMsgTxt_B_Rq 1;
BA_ "GenSigStartValue" SG_ 934 Side_Detect_L_Illum 100;
BA_ "U_V713N_MY2022_Rx" SG_ 934 Side_Detect_L_Illum 1;
BA_ "U_V713AV_MY2022_Rx" SG_ 934 Side_Detect_L_Illum 1;
BA_ "U_P708_MY2023_Rx" SG_ 934 Side_Detect_L_Illum 1;
BA_ "U_V710_MY2023_Rx" SG_ 934 Side_Detect_L_Illum 1;
BA_ "U_P702_MY2024_Rx" SG_ 934 Side_Detect_L_Illum 1;
BA_ "U_V713N_MY2022_Rx" SG_ 934 CtaSnsLeft_D_Stat 1;
BA_ "U_V713AV_MY2022_Rx" SG_ 934 CtaSnsLeft_D_Stat 1;
BA_ "U_P708_MY2023_Rx" SG_ 934 CtaSnsLeft_D_Stat 1;
BA_ "U_V710_MY2023_Rx" SG_ 934 CtaSnsLeft_D_Stat 1;
BA_ "U_P702_MY2024_Rx" SG_ 934 CtaSnsLeft_D_Stat 1;
BA_ "U_V713N_MY2022_Rx" SG_ 934 SodDetctLeft_D_Stat 1;
BA_ "U_V713AV_MY2022_Rx" SG_ 934 SodDetctLeft_D_Stat 1;
BA_ "U_P708_MY2023_Rx" SG_ 934 SodDetctLeft_D_Stat 1;
BA_ "U_V710_MY2023_Rx" SG_ 934 SodDetctLeft_D_Stat 1;
BA_ "U_P702_MY2024_Rx" SG_ 934 SodDetctLeft_D_Stat 1;
BA_ "U_V713N_MY2022_Rx" SG_ 934 CtaLeft_D_Stat 1;
BA_ "U_V713AV_MY2022_Rx" SG_ 934 CtaLeft_D_Stat 1;
BA_ "U_P708_MY2023_Rx" SG_ 934 CtaLeft_D_Stat 1;
BA_ "U_V710_MY2023_Rx" SG_ 934 CtaLeft_D_Stat 1;
BA_ "U_P702_MY2024_Rx" SG_ 934 CtaLeft_D_Stat 1;
BA_ "U_V713N_MY2022_Rx" SG_ 934 CtaAlrtLeft_D_Stat 1;
BA_ "U_V713AV_MY2022_Rx" SG_ 934 CtaAlrtLeft_D_Stat 1;
BA_ "U_P708_MY2023_Rx" SG_ 934 CtaAlrtLeft_D_Stat 1;
BA_ "U_V710_MY2023_Rx" SG_ 934 CtaAlrtLeft_D_Stat 1;
BA_ "U_P702_MY2024_Rx" SG_ 934 CtaAlrtLeft_D_Stat 1;
BA_ "GenSigStartValue" SG_ 934 SodLeft_D_Stat 2;
BA_ "U_V713N_MY2022_Rx" SG_ 934 SodLeft_D_Stat 1;
BA_ "U_V713AV_MY2022_Rx" SG_ 934 SodLeft_D_Stat 1;
BA_ "U_P708_MY2023_Rx" SG_ 934 SodLeft_D_Stat 1;
BA_ "U_V710_MY2023_Rx" SG_ 934 SodLeft_D_Stat 1;
BA_ "U_P702_MY2024_Rx" SG_ 934 SodLeft_D_Stat 1;
BA_ "U_V713N_MY2022_Rx" SG_ 934 SodSnsLeft_D_Stat 1;
BA_ "U_V713AV_MY2022_Rx" SG_ 934 SodSnsLeft_D_Stat 1;
BA_ "U_P708_MY2023_Rx" SG_ 934 SodSnsLeft_D_Stat 1;
BA_ "U_V710_MY2023_Rx" SG_ 934 SodSnsLeft_D_Stat 1;
BA_ "U_P702_MY2024_Rx" SG_ 934 SodSnsLeft_D_Stat 1;
BA_ "U_V713N_MY2022_Rx" SG_ 934 SodAlrtLeft_D_Stat 1;
BA_ "U_V713AV_MY2022_Rx" SG_ 934 SodAlrtLeft_D_Stat 1;
BA_ "U_P708_MY2023_Rx" SG_ 934 SodAlrtLeft_D_Stat 1;
BA_ "U_V710_MY2023_Rx" SG_ 934 SodAlrtLeft_D_Stat 1;
BA_ "U_P702_MY2024_Rx" SG_ 934 SodAlrtLeft_D_Stat 1;
BA_ "GenSigStartValue" SG_ 934 SodWarnLeft_Prd_Rq 14;
BA_ "GenSigSendType" SG_ 486 ResponseCode_No_Res 3;
BA_ "U_P708_MY2023_Rx" SG_ 486 ResponseCode_No_Res 1;
BA_ "U_P702_MY2024_Rx" SG_ 486 ResponseCode_No_Res 1;
BA_ "U_V713N_MY2022_Tx" SG_ 486 ResponseCode_No_Res 1;
BA_ "U_V713AV_MY2022_Tx" SG_ 486 ResponseCode_No_Res 1;
BA_ "U_P708_MY2023_Tx" SG_ 486 ResponseCode_No_Res 1;
BA_ "U_V710_MY2023_Tx" SG_ 486 ResponseCode_No_Res 1;
BA_ "U_V713N_MY2022_Rx" SG_ 486 ACU_ARAudioSource_Rsp 1;
BA_ "U_V713AV_MY2022_Rx" SG_ 486 ACU_ARAudioSource_Rsp 1;
BA_ "U_P708_MY2023_Rx" SG_ 486 ACU_ARAudioSource_Rsp 1;
BA_ "U_CDX74X_MY2024_Rx" SG_ 486 ACU_ARAudioSource_Rsp 1;
BA_ "U_V710_MY2023_Rx" SG_ 486 ACU_ARAudioSource_Rsp 1;
BA_ "U_P702_MY2024_Rx" SG_ 486 ACU_ARAudioSource_Rsp 1;
BA_ "U_V713N_MY2022_Tx" SG_ 486 ACU_ARAudioSource_Rsp 1;
BA_ "U_V713AV_MY2022_Tx" SG_ 486 ACU_ARAudioSource_Rsp 1;
BA_ "U_P708_MY2023_Tx" SG_ 486 ACU_ARAudioSource_Rsp 1;
BA_ "U_V710_MY2023_Tx" SG_ 486 ACU_ARAudioSource_Rsp 1;
BA_ "U_V713N_MY2022_Rx" SG_ 486 ACU_AROperationType_Rsp 1;
BA_ "U_V713AV_MY2022_Rx" SG_ 486 ACU_AROperationType_Rsp 1;
BA_ "U_CDX74X_MY2024_Rx" SG_ 486 ACU_AROperationType_Rsp 1;
BA_ "U_V710_MY2023_Rx" SG_ 486 ACU_AROperationType_Rsp 1;
BA_ "U_P708_MY2023_Rx" SG_ 486 ACU_AROperationType_Rsp 1;
BA_ "U_P702_MY2024_Rx" SG_ 486 ACU_AROperationType_Rsp 1;
BA_ "U_V713N_MY2022_Tx" SG_ 486 ACU_AROperationType_Rsp 1;
BA_ "U_V713AV_MY2022_Tx" SG_ 486 ACU_AROperationType_Rsp 1;
BA_ "U_P708_MY2023_Tx" SG_ 486 ACU_AROperationType_Rsp 1;
BA_ "U_V710_MY2023_Tx" SG_ 486 ACU_AROperationType_Rsp 1;
BA_ "U_V713N_MY2022_Rx" SG_ 486 ACU_ARReqstrSystem_Rsp 1;
BA_ "U_V713AV_MY2022_Rx" SG_ 486 ACU_ARReqstrSystem_Rsp 1;
BA_ "U_CDX74X_MY2024_Rx" SG_ 486 ACU_ARReqstrSystem_Rsp 1;
BA_ "U_V710_MY2023_Rx" SG_ 486 ACU_ARReqstrSystem_Rsp 1;
BA_ "U_P708_MY2023_Rx" SG_ 486 ACU_ARReqstrSystem_Rsp 1;
BA_ "U_P702_MY2024_Rx" SG_ 486 ACU_ARReqstrSystem_Rsp 1;
BA_ "U_V713N_MY2022_Tx" SG_ 486 ACU_ARReqstrSystem_Rsp 1;
BA_ "U_V713AV_MY2022_Tx" SG_ 486 ACU_ARReqstrSystem_Rsp 1;
BA_ "U_P708_MY2023_Tx" SG_ 486 ACU_ARReqstrSystem_Rsp 1;
BA_ "U_V710_MY2023_Tx" SG_ 486 ACU_ARReqstrSystem_Rsp 1;
BA_ "GenSigSendType" SG_ 486 ACU_ARResponse_Rsp 1;
BA_ "U_V713N_MY2022_Rx" SG_ 486 ACU_ARResponse_Rsp 1;
BA_ "U_V713AV_MY2022_Rx" SG_ 486 ACU_ARResponse_Rsp 1;
BA_ "U_CDX74X_MY2024_Rx" SG_ 486 ACU_ARResponse_Rsp 1;
BA_ "U_V710_MY2023_Rx" SG_ 486 ACU_ARResponse_Rsp 1;
BA_ "U_P708_MY2023_Rx" SG_ 486 ACU_ARResponse_Rsp 1;
BA_ "U_P702_MY2024_Rx" SG_ 486 ACU_ARResponse_Rsp 1;
BA_ "U_V713N_MY2022_Tx" SG_ 486 ACU_ARResponse_Rsp 1;
BA_ "U_V713AV_MY2022_Tx" SG_ 486 ACU_ARResponse_Rsp 1;
BA_ "U_P708_MY2023_Tx" SG_ 486 ACU_ARResponse_Rsp 1;
BA_ "U_V710_MY2023_Tx" SG_ 486 ACU_ARResponse_Rsp 1;
BA_ "U_V713N_MY2022_Rx" SG_ 486 ACU_ARReqstrPriority_Rp 1;
BA_ "U_V713AV_MY2022_Rx" SG_ 486 ACU_ARReqstrPriority_Rp 1;
BA_ "U_CDX74X_MY2024_Rx" SG_ 486 ACU_ARReqstrPriority_Rp 1;
BA_ "U_V710_MY2023_Rx" SG_ 486 ACU_ARReqstrPriority_Rp 1;
BA_ "U_P708_MY2023_Rx" SG_ 486 ACU_ARReqstrPriority_Rp 1;
BA_ "U_P702_MY2024_Rx" SG_ 486 ACU_ARReqstrPriority_Rp 1;
BA_ "U_V713N_MY2022_Tx" SG_ 486 ACU_ARReqstrPriority_Rp 1;
BA_ "U_V713AV_MY2022_Tx" SG_ 486 ACU_ARReqstrPriority_Rp 1;
BA_ "U_P708_MY2023_Tx" SG_ 486 ACU_ARReqstrPriority_Rp 1;
BA_ "U_V710_MY2023_Tx" SG_ 486 ACU_ARReqstrPriority_Rp 1;
BA_ "U_V713N_MY2022_Rx" SG_ 486 ACU_RUAudioSource_St 1;
BA_ "U_V713AV_MY2022_Rx" SG_ 486 ACU_RUAudioSource_St 1;
BA_ "U_P708_MY2023_Rx" SG_ 486 ACU_RUAudioSource_St 1;
BA_ "U_CDX74X_MY2024_Rx" SG_ 486 ACU_RUAudioSource_St 1;
BA_ "U_V710_MY2023_Rx" SG_ 486 ACU_RUAudioSource_St 1;
BA_ "U_P702_MY2024_Rx" SG_ 486 ACU_RUAudioSource_St 1;
BA_ "ECGUsedRxSignal" SG_ 486 ACU_RUAudioSource_St 1;
BA_ "U_V713N_MY2022_Tx" SG_ 486 ACU_RUAudioSource_St 1;
BA_ "U_V713AV_MY2022_Tx" SG_ 486 ACU_RUAudioSource_St 1;
BA_ "U_P708_MY2023_Tx" SG_ 486 ACU_RUAudioSource_St 1;
BA_ "U_V710_MY2023_Tx" SG_ 486 ACU_RUAudioSource_St 1;
BA_ "U_V713N_MY2022_Rx" SG_ 486 ACU_RUReqstrSystem_St 1;
BA_ "U_V713AV_MY2022_Rx" SG_ 486 ACU_RUReqstrSystem_St 1;
BA_ "U_P708_MY2023_Rx" SG_ 486 ACU_RUReqstrSystem_St 1;
BA_ "U_CDX74X_MY2024_Rx" SG_ 486 ACU_RUReqstrSystem_St 1;
BA_ "U_V710_MY2023_Rx" SG_ 486 ACU_RUReqstrSystem_St 1;
BA_ "U_P702_MY2024_Rx" SG_ 486 ACU_RUReqstrSystem_St 1;
BA_ "U_V713N_MY2022_Tx" SG_ 486 ACU_RUReqstrSystem_St 1;
BA_ "U_V713AV_MY2022_Tx" SG_ 486 ACU_RUReqstrSystem_St 1;
BA_ "U_P708_MY2023_Tx" SG_ 486 ACU_RUReqstrSystem_St 1;
BA_ "U_V710_MY2023_Tx" SG_ 486 ACU_RUReqstrSystem_St 1;
BA_ "U_V713N_MY2022_Rx" SG_ 486 ACU_RUResReqstStatus_St 1;
BA_ "U_V713AV_MY2022_Rx" SG_ 486 ACU_RUResReqstStatus_St 1;
BA_ "U_P708_MY2023_Rx" SG_ 486 ACU_RUResReqstStatus_St 1;
BA_ "U_CDX74X_MY2024_Rx" SG_ 486 ACU_RUResReqstStatus_St 1;
BA_ "U_V710_MY2023_Rx" SG_ 486 ACU_RUResReqstStatus_St 1;
BA_ "U_P702_MY2024_Rx" SG_ 486 ACU_RUResReqstStatus_St 1;
BA_ "ECGUsedRxSignal" SG_ 486 ACU_RUResReqstStatus_St 1;
BA_ "U_V713N_MY2022_Tx" SG_ 486 ACU_RUResReqstStatus_St 1;
BA_ "U_V713AV_MY2022_Tx" SG_ 486 ACU_RUResReqstStatus_St 1;
BA_ "U_P708_MY2023_Tx" SG_ 486 ACU_RUResReqstStatus_St 1;
BA_ "U_V710_MY2023_Tx" SG_ 486 ACU_RUResReqstStatus_St 1;
BA_ "U_V713N_MY2022_Rx" SG_ 486 ACU_RUReqstrPriority_St 1;
BA_ "U_V713AV_MY2022_Rx" SG_ 486 ACU_RUReqstrPriority_St 1;
BA_ "U_P708_MY2023_Rx" SG_ 486 ACU_RUReqstrPriority_St 1;
BA_ "U_CDX74X_MY2024_Rx" SG_ 486 ACU_RUReqstrPriority_St 1;
BA_ "U_V710_MY2023_Rx" SG_ 486 ACU_RUReqstrPriority_St 1;
BA_ "U_P702_MY2024_Rx" SG_ 486 ACU_RUReqstrPriority_St 1;
BA_ "U_V713N_MY2022_Tx" SG_ 486 ACU_RUReqstrPriority_St 1;
BA_ "U_V713AV_MY2022_Tx" SG_ 486 ACU_RUReqstrPriority_St 1;
BA_ "U_P708_MY2023_Tx" SG_ 486 ACU_RUReqstrPriority_St 1;
BA_ "U_V710_MY2023_Tx" SG_ 486 ACU_RUReqstrPriority_St 1;
BA_ "U_V710_MY2023_Tx" SG_ 553 CCOI_PolicyClient_St 1;
BA_ "U_P708_MY2023_Tx" SG_ 553 CCOI_PolicyClient_St 1;
BA_ "U_P702_MY2024_Tx" SG_ 553 CCOI_PolicyClient_St 1;
BA_ "GenSigSendType" SG_ 553 ResetAvgFe_B_Rq 3;
BA_ "U_V713N_MY2022_Rx" SG_ 553 ResetAvgFe_B_Rq 1;
BA_ "U_V713AV_MY2022_Rx" SG_ 553 ResetAvgFe_B_Rq 1;
BA_ "U_V710_MY2023_Tx" SG_ 553 ResetAvgFe_B_Rq 1;
BA_ "U_P708_MY2023_Tx" SG_ 553 ResetAvgFe_B_Rq 1;
BA_ "U_P702_MY2024_Tx" SG_ 553 ResetAvgFe_B_Rq 1;
BA_ "GenSigSendType" SG_ 553 ResetTrip2_B_Rq 3;
BA_ "U_V713N_MY2022_Rx" SG_ 553 ResetTrip2_B_Rq 1;
BA_ "U_V713AV_MY2022_Rx" SG_ 553 ResetTrip2_B_Rq 1;
BA_ "U_V710_MY2023_Rx" SG_ 553 ResetTrip2_B_Rq 1;
BA_ "U_V710_MY2023_Tx" SG_ 553 ResetTrip2_B_Rq 1;
BA_ "U_P708_MY2023_Tx" SG_ 553 ResetTrip2_B_Rq 1;
BA_ "U_P702_MY2024_Tx" SG_ 553 ResetTrip2_B_Rq 1;
BA_ "GenSigStartValue" SG_ 553 DistToChrgrBynd_L_Actl 510;
BA_ "U_V710_MY2023_Tx" SG_ 553 DistToChrgrBynd_L_Actl 1;
BA_ "U_P708_MY2023_Tx" SG_ 553 DistToChrgrBynd_L_Actl 1;
BA_ "U_P702_MY2024_Tx" SG_ 553 DistToChrgrBynd_L_Actl 1;
BA_ "GenSigSendType" SG_ 553 SndImmrsnLvl_D_Rq 3;
BA_ "U_V710_MY2023_Tx" SG_ 553 SndImmrsnLvl_D_Rq 1;
BA_ "U_P708_MY2023_Tx" SG_ 553 SndImmrsnLvl_D_Rq 1;
BA_ "U_P702_MY2024_Tx" SG_ 553 SndImmrsnLvl_D_Rq 1;
BA_ "GenSigSendType" SG_ 553 InfoSysMasterPw_D_Stat 3;
BA_ "ECGUsedRxSignal" SG_ 553 InfoSysMasterPw_D_Stat 1;
BA_ "U_V713N_MY2022_Rx" SG_ 553 InfoSysMasterPw_D_Stat 1;
BA_ "U_V713AV_MY2022_Rx" SG_ 553 InfoSysMasterPw_D_Stat 1;
BA_ "U_P708_MY2023_Rx" SG_ 553 InfoSysMasterPw_D_Stat 1;
BA_ "U_CDX74X_MY2024_Rx" SG_ 553 InfoSysMasterPw_D_Stat 1;
BA_ "U_V710_MY2023_Rx" SG_ 553 InfoSysMasterPw_D_Stat 1;
BA_ "U_V710_MY2023_Tx" SG_ 553 InfoSysMasterPw_D_Stat 1;
BA_ "U_P708_MY2023_Tx" SG_ 553 InfoSysMasterPw_D_Stat 1;
BA_ "U_P702_MY2024_Tx" SG_ 553 InfoSysMasterPw_D_Stat 1;
BA_ "GenSigSendType" SG_ 553 ResetTrip1_B_Rq 3;
BA_ "U_V713N_MY2022_Rx" SG_ 553 ResetTrip1_B_Rq 1;
BA_ "U_V713AV_MY2022_Rx" SG_ 553 ResetTrip1_B_Rq 1;
BA_ "U_V710_MY2023_Rx" SG_ 553 ResetTrip1_B_Rq 1;
BA_ "U_V710_MY2023_Tx" SG_ 553 ResetTrip1_B_Rq 1;
BA_ "U_P708_MY2023_Tx" SG_ 553 ResetTrip1_B_Rq 1;
BA_ "U_P702_MY2024_Tx" SG_ 553 ResetTrip1_B_Rq 1;
BA_ "GenSigSendType" SG_ 553 Disp_LangSel2_St 3;
BA_ "ECGUsedRxSignal" SG_ 553 Disp_LangSel2_St 1;
BA_ "U_V713N_MY2022_Rx" SG_ 553 Disp_LangSel2_St 1;
BA_ "U_V713AV_MY2022_Rx" SG_ 553 Disp_LangSel2_St 1;
BA_ "U_P708_MY2023_Rx" SG_ 553 Disp_LangSel2_St 1;
BA_ "U_CDX74X_MY2024_Rx" SG_ 553 Disp_LangSel2_St 1;
BA_ "U_V710_MY2023_Rx" SG_ 553 Disp_LangSel2_St 1;
BA_ "U_V710_MY2023_Tx" SG_ 553 Disp_LangSel2_St 1;
BA_ "U_P708_MY2023_Tx" SG_ 553 Disp_LangSel2_St 1;
BA_ "U_P702_MY2024_Tx" SG_ 553 Disp_LangSel2_St 1;
BA_ "GenSigSendType" SG_ 553 Disp_LangSel_St 3;
BA_ "U_V713N_MY2022_Rx" SG_ 553 Disp_LangSel_St 1;
BA_ "U_V713AV_MY2022_Rx" SG_ 553 Disp_LangSel_St 1;
BA_ "U_CDX74X_MY2024_Rx" SG_ 553 Disp_LangSel_St 1;
BA_ "ECGUsedRxSignal" SG_ 553 Disp_LangSel_St 1;
BA_ "U_P708_MY2023_Rx" SG_ 553 Disp_LangSel_St 1;
BA_ "U_V710_MY2023_Rx" SG_ 553 Disp_LangSel_St 1;
BA_ "U_V710_MY2023_Tx" SG_ 553 Disp_LangSel_St 1;
BA_ "U_P708_MY2023_Tx" SG_ 553 Disp_LangSel_St 1;
BA_ "U_P702_MY2024_Tx" SG_ 553 Disp_LangSel_St 1;
BA_ "GenSigSendType" SG_ 553 Diagnostic_Operation_Rq 3;
BA_ "U_V713N_MY2022_Rx" SG_ 553 Diagnostic_Operation_Rq 1;
BA_ "U_V713AV_MY2022_Rx" SG_ 553 Diagnostic_Operation_Rq 1;
BA_ "U_P708_MY2023_Rx" SG_ 553 Diagnostic_Operation_Rq 1;
BA_ "U_V710_MY2023_Rx" SG_ 553 Diagnostic_Operation_Rq 1;
BA_ "U_V710_MY2023_Tx" SG_ 553 Diagnostic_Operation_Rq 1;
BA_ "U_P708_MY2023_Tx" SG_ 553 Diagnostic_Operation_Rq 1;
BA_ "U_P702_MY2024_Tx" SG_ 553 Diagnostic_Operation_Rq 1;
BA_ "GenSigSendType" SG_ 553 Bezel_Diag_Module_Rq 3;
BA_ "U_V713N_MY2022_Rx" SG_ 553 Bezel_Diag_Module_Rq 1;
BA_ "U_V713AV_MY2022_Rx" SG_ 553 Bezel_Diag_Module_Rq 1;
BA_ "U_P708_MY2023_Rx" SG_ 553 Bezel_Diag_Module_Rq 1;
BA_ "U_V710_MY2023_Rx" SG_ 553 Bezel_Diag_Module_Rq 1;
BA_ "U_V710_MY2023_Tx" SG_ 553 Bezel_Diag_Module_Rq 1;
BA_ "U_P708_MY2023_Tx" SG_ 553 Bezel_Diag_Module_Rq 1;
BA_ "U_P702_MY2024_Tx" SG_ 553 Bezel_Diag_Module_Rq 1;
BA_ "GenSigSendType" SG_ 553 Audio_Demo_CMND 3;
BA_ "U_V713N_MY2022_Rx" SG_ 553 Audio_Demo_CMND 1;
BA_ "U_V713AV_MY2022_Rx" SG_ 553 Audio_Demo_CMND 1;
BA_ "U_P708_MY2023_Rx" SG_ 553 Audio_Demo_CMND 1;
BA_ "U_V710_MY2023_Rx" SG_ 553 Audio_Demo_CMND 1;
BA_ "U_V710_MY2023_Tx" SG_ 553 Audio_Demo_CMND 1;
BA_ "U_P708_MY2023_Tx" SG_ 553 Audio_Demo_CMND 1;
BA_ "U_P702_MY2024_Tx" SG_ 553 Audio_Demo_CMND 1;
BA_ "GenSigSendType" SG_ 553 Audio_Visualizer 3;
BA_ "U_V713N_MY2022_Rx" SG_ 553 Audio_Visualizer 1;
BA_ "U_V713AV_MY2022_Rx" SG_ 553 Audio_Visualizer 1;
BA_ "U_P708_MY2023_Rx" SG_ 553 Audio_Visualizer 1;
BA_ "U_V710_MY2023_Rx" SG_ 553 Audio_Visualizer 1;
BA_ "U_V710_MY2023_Tx" SG_ 553 Audio_Visualizer 1;
BA_ "U_P708_MY2023_Tx" SG_ 553 Audio_Visualizer 1;
BA_ "U_P702_MY2024_Tx" SG_ 553 Audio_Visualizer 1;
BA_ "GenSigSendType" SG_ 553 Surround_Sound_Upmix 3;
BA_ "U_CDX74X_MY2024_Rx" SG_ 553 Surround_Sound_Upmix 1;
BA_ "U_V710_MY2023_Rx" SG_ 553 Surround_Sound_Upmix 1;
BA_ "U_V710_MY2023_Tx" SG_ 553 Surround_Sound_Upmix 1;
BA_ "U_P708_MY2023_Tx" SG_ 553 Surround_Sound_Upmix 1;
BA_ "U_P702_MY2024_Tx" SG_ 553 Surround_Sound_Upmix 1;
BA_ "GenSigSendType" SG_ 553 Bezel_Diag_State_Rq 3;
BA_ "U_V713N_MY2022_Rx" SG_ 553 Bezel_Diag_State_Rq 1;
BA_ "U_V713AV_MY2022_Rx" SG_ 553 Bezel_Diag_State_Rq 1;
BA_ "U_P708_MY2023_Rx" SG_ 553 Bezel_Diag_State_Rq 1;
BA_ "U_V710_MY2023_Rx" SG_ 553 Bezel_Diag_State_Rq 1;
BA_ "U_V710_MY2023_Tx" SG_ 553 Bezel_Diag_State_Rq 1;
BA_ "U_P708_MY2023_Tx" SG_ 553 Bezel_Diag_State_Rq 1;
BA_ "U_P702_MY2024_Tx" SG_ 553 Bezel_Diag_State_Rq 1;
BA_ "GenSigSendType" SG_ 553 SurndSndUpmix2_D_Rq 3;
BA_ "U_V710_MY2023_Rx" SG_ 553 SurndSndUpmix2_D_Rq 1;
BA_ "U_V710_MY2023_Tx" SG_ 553 SurndSndUpmix2_D_Rq 1;
BA_ "U_P708_MY2023_Tx" SG_ 553 SurndSndUpmix2_D_Rq 1;
BA_ "U_P702_MY2024_Tx" SG_ 553 SurndSndUpmix2_D_Rq 1;
BA_ "GenSigSendType" SG_ 739 VgfSet_D_Stat 3;
BA_ "ECGUsedRxSignal" SG_ 739 VgfSet_D_Stat 1;
BA_ "GenSigSendType" SG_ 739 OnbTrgtSocOvrrd_D_Rq 3;
BA_ "U_P702_MY2024_Tx" SG_ 739 OnbTrgtSocOvrrd_D_Rq 1;
BA_ "GenSigStartValue" SG_ 739 OnbTrgtSocOvrrd_Pc_Rq 100;
BA_ "U_P702_MY2024_Tx" SG_ 739 OnbTrgtSocOvrrd_Pc_Rq 1;
BA_ "GenSigStartValue" SG_ 739 BptDly_T_RqMnu 62;
BA_ "GenSigSendType" SG_ 739 BptDly_T_RqMnu 3;
BA_ "U_V710_MY2023_Tx" SG_ 739 BptDly_T_RqMnu 1;
BA_ "U_P708_MY2023_Tx" SG_ 739 BptDly_T_RqMnu 1;
BA_ "U_P702_MY2024_Tx" SG_ 739 BptDly_T_RqMnu 1;
BA_ "GenSigStartValue" SG_ 739 BptMnSoc_L_RqMnu 8190;
BA_ "U_V710_MY2023_Tx" SG_ 739 BptMnSoc_L_RqMnu 1;
BA_ "U_P708_MY2023_Tx" SG_ 739 BptMnSoc_L_RqMnu 1;
BA_ "U_P702_MY2024_Tx" SG_ 739 BptMnSoc_L_RqMnu 1;
BA_ "GenSigSendType" SG_ 739 BptStrtStop_D_RqMnu 3;
BA_ "U_V710_MY2023_Tx" SG_ 739 BptStrtStop_D_RqMnu 1;
BA_ "U_P708_MY2023_Tx" SG_ 739 BptStrtStop_D_RqMnu 1;
BA_ "U_P702_MY2024_Tx" SG_ 739 BptStrtStop_D_RqMnu 1;
BA_ "GenSigSendType" SG_ 739 BptMde_D_RqMnu 3;
BA_ "U_V710_MY2023_Tx" SG_ 739 BptMde_D_RqMnu 1;
BA_ "U_P708_MY2023_Tx" SG_ 739 BptMde_D_RqMnu 1;
BA_ "U_P702_MY2024_Tx" SG_ 739 BptMde_D_RqMnu 1;
BA_ "GenSigSendType" SG_ 739 VehHornOccAlrt_D_Stat 3;
BA_ "ECGUsedRxSignal" SG_ 739 VehHornOccAlrt_D_Stat 1;
BA_ "U_CDX74X_MY2024_Rx" SG_ 739 VehHornOccAlrt_D_Stat 1;
BA_ "U_V710_MY2023_Rx" SG_ 739 VehHornOccAlrt_D_Stat 1;
BA_ "U_V710_MY2023_Tx" SG_ 739 VehHornOccAlrt_D_Stat 1;
BA_ "U_P708_MY2023_Tx" SG_ 739 VehHornOccAlrt_D_Stat 1;
BA_ "U_P702_MY2024_Tx" SG_ 739 VehHornOccAlrt_D_Stat 1;
BA_ "GenSigSendType" SG_ 739 SeatOccRear_D_Stat 3;
BA_ "ECGUsedRxSignal" SG_ 739 SeatOccRear_D_Stat 1;
BA_ "U_CDX74X_MY2024_Rx" SG_ 739 SeatOccRear_D_Stat 1;
BA_ "U_V710_MY2023_Rx" SG_ 739 SeatOccRear_D_Stat 1;
BA_ "U_V710_MY2023_Tx" SG_ 739 SeatOccRear_D_Stat 1;
BA_ "U_P708_MY2023_Tx" SG_ 739 SeatOccRear_D_Stat 1;
BA_ "U_P702_MY2024_Tx" SG_ 739 SeatOccRear_D_Stat 1;
BA_ "GenSigSendType" SG_ 739 BabySeatInUse_D_Stat 3;
BA_ "ECGUsedRxSignal" SG_ 739 BabySeatInUse_D_Stat 1;
BA_ "U_CDX74X_MY2024_Rx" SG_ 739 BabySeatInUse_D_Stat 1;
BA_ "U_V710_MY2023_Rx" SG_ 739 BabySeatInUse_D_Stat 1;
BA_ "U_V710_MY2023_Tx" SG_ 739 BabySeatInUse_D_Stat 1;
BA_ "U_P708_MY2023_Tx" SG_ 739 BabySeatInUse_D_Stat 1;
BA_ "U_P702_MY2024_Tx" SG_ 739 BabySeatInUse_D_Stat 1;
BA_ "GenSigSendType" SG_ 739 SeatOccChime_B_RqCancl 3;
BA_ "ECGUsedRxSignal" SG_ 739 SeatOccChime_B_RqCancl 1;
BA_ "U_CDX74X_MY2024_Rx" SG_ 739 SeatOccChime_B_RqCancl 1;
BA_ "U_V710_MY2023_Rx" SG_ 739 SeatOccChime_B_RqCancl 1;
BA_ "U_V710_MY2023_Tx" SG_ 739 SeatOccChime_B_RqCancl 1;
BA_ "U_P708_MY2023_Tx" SG_ 739 SeatOccChime_B_RqCancl 1;
BA_ "U_P702_MY2024_Tx" SG_ 739 SeatOccChime_B_RqCancl 1;
BA_ "GenSigSendType" SG_ 739 EngExhMdeHrStrt_D_Rq 3;
BA_ "U_V713AV_MY2022_Tx" SG_ 739 EngExhMdeHrStrt_D_Rq 1;
BA_ "U_P708_MY2023_Tx" SG_ 739 EngExhMdeHrStrt_D_Rq 1;
BA_ "U_V710_MY2023_Tx" SG_ 739 EngExhMdeHrStrt_D_Rq 1;
BA_ "U_P702_MY2024_Tx" SG_ 739 EngExhMdeHrStrt_D_Rq 1;
BA_ "GenSigSendType" SG_ 739 EngExhMdeHrEnd_D_Rq 3;
BA_ "U_V713AV_MY2022_Tx" SG_ 739 EngExhMdeHrEnd_D_Rq 1;
BA_ "U_P708_MY2023_Tx" SG_ 739 EngExhMdeHrEnd_D_Rq 1;
BA_ "U_V710_MY2023_Tx" SG_ 739 EngExhMdeHrEnd_D_Rq 1;
BA_ "U_P702_MY2024_Tx" SG_ 739 EngExhMdeHrEnd_D_Rq 1;
BA_ "GenSigSendType" SG_ 739 EngExhMdeHrEnbl_D_Rq 3;
BA_ "U_V713AV_MY2022_Tx" SG_ 739 EngExhMdeHrEnbl_D_Rq 1;
BA_ "U_P708_MY2023_Tx" SG_ 739 EngExhMdeHrEnbl_D_Rq 1;
BA_ "U_V710_MY2023_Tx" SG_ 739 EngExhMdeHrEnbl_D_Rq 1;
BA_ "U_P702_MY2024_Tx" SG_ 739 EngExhMdeHrEnbl_D_Rq 1;
BA_ "GenSigSendType" SG_ 739 Partial_Amp_Shutdown 3;
BA_ "U_V713N_MY2022_Rx" SG_ 739 Partial_Amp_Shutdown 1;
BA_ "U_V713AV_MY2022_Rx" SG_ 739 Partial_Amp_Shutdown 1;
BA_ "U_P708_MY2023_Rx" SG_ 739 Partial_Amp_Shutdown 1;
BA_ "U_V710_MY2023_Rx" SG_ 739 Partial_Amp_Shutdown 1;
BA_ "U_V713AV_MY2022_Tx" SG_ 739 Partial_Amp_Shutdown 1;
BA_ "U_P708_MY2023_Tx" SG_ 739 Partial_Amp_Shutdown 1;
BA_ "U_V710_MY2023_Tx" SG_ 739 Partial_Amp_Shutdown 1;
BA_ "U_P702_MY2024_Tx" SG_ 739 Partial_Amp_Shutdown 1;
BA_ "WakeupSignal" SG_ 739 HMI_HMIMode_St 1;
BA_ "GenSigSendType" SG_ 739 HMI_HMIMode_St 3;
BA_ "U_V713N_MY2022_Rx" SG_ 739 HMI_HMIMode_St 1;
BA_ "U_V713AV_MY2022_Rx" SG_ 739 HMI_HMIMode_St 1;
BA_ "U_V710_MY2023_Rx" SG_ 739 HMI_HMIMode_St 1;
BA_ "U_P708_MY2023_Rx" SG_ 739 HMI_HMIMode_St 1;
BA_ "U_CDX74X_MY2024_Rx" SG_ 739 HMI_HMIMode_St 1;
BA_ "U_P702_MY2024_Rx" SG_ 739 HMI_HMIMode_St 1;
BA_ "ECGUsedRxSignal" SG_ 739 HMI_HMIMode_St 1;
BA_ "U_V713AV_MY2022_Tx" SG_ 739 HMI_HMIMode_St 1;
BA_ "U_P708_MY2023_Tx" SG_ 739 HMI_HMIMode_St 1;
BA_ "U_V710_MY2023_Tx" SG_ 739 HMI_HMIMode_St 1;
BA_ "U_P702_MY2024_Tx" SG_ 739 HMI_HMIMode_St 1;
BA_ "GenSigSendType" SG_ 1009 ChrgCordUnlock_B_Rq 3;
BA_ "U_V710_MY2023_Tx" SG_ 1009 ChrgCordUnlock_B_Rq 1;
BA_ "U_P708_MY2023_Tx" SG_ 1009 ChrgCordUnlock_B_Rq 1;
BA_ "U_P702_MY2024_Tx" SG_ 1009 ChrgCordUnlock_B_Rq 1;
BA_ "GenSigSendType" SG_ 1009 AutoHoldSwtch_D_Stat3 3;
BA_ "U_V710_MY2023_Tx" SG_ 1009 AutoHoldSwtch_D_Stat3 1;
BA_ "U_P708_MY2023_Tx" SG_ 1009 AutoHoldSwtch_D_Stat3 1;
BA_ "U_P702_MY2024_Tx" SG_ 1009 AutoHoldSwtch_D_Stat3 1;
BA_ "GenSigSendType" SG_ 1009 TrlrTrgtAcquire_D_Rq 3;
BA_ "U_V710_MY2023_Tx" SG_ 1009 TrlrTrgtAcquire_D_Rq 1;
BA_ "U_P708_MY2023_Tx" SG_ 1009 TrlrTrgtAcquire_D_Rq 1;
BA_ "U_P702_MY2024_Tx" SG_ 1009 TrlrTrgtAcquire_D_Rq 1;
BA_ "GenSigSendType" SG_ 1009 RearAudioCtlLck_D_Rq 3;
BA_ "U_CDX74X_MY2024_Rx" SG_ 1009 RearAudioCtlLck_D_Rq 1;
BA_ "U_V710_MY2023_Tx" SG_ 1009 RearAudioCtlLck_D_Rq 1;
BA_ "U_P708_MY2023_Tx" SG_ 1009 RearAudioCtlLck_D_Rq 1;
BA_ "U_P702_MY2024_Tx" SG_ 1009 RearAudioCtlLck_D_Rq 1;
BA_ "GenSigSendType" SG_ 1009 TrlrAidCancl_B_Rq 3;
BA_ "U_V710_MY2023_Tx" SG_ 1009 TrlrAidCancl_B_Rq 1;
BA_ "U_P708_MY2023_Tx" SG_ 1009 TrlrAidCancl_B_Rq 1;
BA_ "U_P702_MY2024_Tx" SG_ 1009 TrlrAidCancl_B_Rq 1;
BA_ "GenSigStartValue" SG_ 1009 CenterStackRing_D_Actl 2;
BA_ "GenSigSendType" SG_ 1009 CenterStackRing_D_Actl 3;
BA_ "U_V710_MY2023_Tx" SG_ 1009 CenterStackRing_D_Actl 1;
BA_ "U_P708_MY2023_Tx" SG_ 1009 CenterStackRing_D_Actl 1;
BA_ "U_P702_MY2024_Tx" SG_ 1009 CenterStackRing_D_Actl 1;
BA_ "GenSigSendType" SG_ 1009 APIM_NumberofTracks_St 3;
BA_ "U_P708_MY2023_Rx" SG_ 1009 APIM_NumberofTracks_St 1;
BA_ "U_CDX74X_MY2024_Rx" SG_ 1009 APIM_NumberofTracks_St 1;
BA_ "U_P702_MY2024_Rx" SG_ 1009 APIM_NumberofTracks_St 1;
BA_ "U_V710_MY2023_Tx" SG_ 1009 APIM_NumberofTracks_St 1;
BA_ "U_P708_MY2023_Tx" SG_ 1009 APIM_NumberofTracks_St 1;
BA_ "U_P702_MY2024_Tx" SG_ 1009 APIM_NumberofTracks_St 1;
BA_ "GenSigSendType" SG_ 1009 APIM_ActiveTrackNum_St 3;
BA_ "U_P708_MY2023_Rx" SG_ 1009 APIM_ActiveTrackNum_St 1;
BA_ "U_CDX74X_MY2024_Rx" SG_ 1009 APIM_ActiveTrackNum_St 1;
BA_ "U_P702_MY2024_Rx" SG_ 1009 APIM_ActiveTrackNum_St 1;
BA_ "U_V710_MY2023_Tx" SG_ 1009 APIM_ActiveTrackNum_St 1;
BA_ "U_P708_MY2023_Tx" SG_ 1009 APIM_ActiveTrackNum_St 1;
BA_ "U_P702_MY2024_Tx" SG_ 1009 APIM_ActiveTrackNum_St 1;
BA_ "GenSigSendType" SG_ 1009 ValetMode_D_Stat 3;
BA_ "U_V710_MY2023_Tx" SG_ 1009 ValetMode_D_Stat 1;
BA_ "U_P708_MY2023_Tx" SG_ 1009 ValetMode_D_Stat 1;
BA_ "U_P702_MY2024_Tx" SG_ 1009 ValetMode_D_Stat 1;
BA_ "GenSigSendType" SG_ 1009 TrlrAidSetup_D_Stat 3;
BA_ "U_V710_MY2023_Tx" SG_ 1009 TrlrAidSetup_D_Stat 1;
BA_ "U_P708_MY2023_Tx" SG_ 1009 TrlrAidSetup_D_Stat 1;
BA_ "U_P702_MY2024_Tx" SG_ 1009 TrlrAidSetup_D_Stat 1;
BA_ "GenSigStartValue" SG_ 531 VehStop_D_Stat 2;
BA_ "WakeupSignal" SG_ 531 PrkBrkYwLamp_D_Rq 1;
BA_ "U_V713N_MY2022_Rx" SG_ 531 PrkBrkYwLamp_D_Rq 1;
BA_ "U_V713AV_MY2022_Rx" SG_ 531 PrkBrkYwLamp_D_Rq 1;
BA_ "U_P708_MY2023_Rx" SG_ 531 PrkBrkYwLamp_D_Rq 1;
BA_ "U_V710_MY2023_Rx" SG_ 531 PrkBrkYwLamp_D_Rq 1;
BA_ "U_P702_MY2024_Rx" SG_ 531 PrkBrkYwLamp_D_Rq 1;
BA_ "WakeupSignal" SG_ 531 PrkBrkRedLamp_D_Rq 1;
BA_ "U_V713N_MY2022_Rx" SG_ 531 PrkBrkRedLamp_D_Rq 1;
BA_ "U_V713AV_MY2022_Rx" SG_ 531 PrkBrkRedLamp_D_Rq 1;
BA_ "U_P708_MY2023_Rx" SG_ 531 PrkBrkRedLamp_D_Rq 1;
BA_ "U_V710_MY2023_Rx" SG_ 531 PrkBrkRedLamp_D_Rq 1;
BA_ "U_P702_MY2024_Rx" SG_ 531 PrkBrkRedLamp_D_Rq 1;
BA_ "WakeupSignal" SG_ 531 PrkBrkMsgTxt_D_Rq 1;
BA_ "U_V713N_MY2022_Rx" SG_ 531 PrkBrkMsgTxt_D_Rq 1;
BA_ "U_V713AV_MY2022_Rx" SG_ 531 PrkBrkMsgTxt_D_Rq 1;
BA_ "U_P708_MY2023_Rx" SG_ 531 PrkBrkMsgTxt_D_Rq 1;
BA_ "U_V710_MY2023_Rx" SG_ 531 PrkBrkMsgTxt_D_Rq 1;
BA_ "U_P702_MY2024_Rx" SG_ 531 PrkBrkMsgTxt_D_Rq 1;
BA_ "GenSigStartValue" SG_ 531 PrkBrkStatus 7;
BA_ "U_V710_MY2023_Rx" SG_ 531 PrkBrkStatus 1;
BA_ "U_P708_MY2023_Rx" SG_ 531 PrkBrkStatus 1;
BA_ "U_P702_MY2024_Rx" SG_ 531 PrkBrkStatus 1;
BA_ "U_V713N_MY2022_Rx" SG_ 531 LscmbbMntr_B_Err 1;
BA_ "U_P708_MY2023_Rx" SG_ 531 LscmbbMntr_B_Err 1;
BA_ "U_V710_MY2023_Rx" SG_ 531 LscmbbMntr_B_Err 1;
BA_ "U_P702_MY2024_Rx" SG_ 531 LscmbbMntr_B_Err 1;
BA_ "U_V710_MY2023_Rx" SG_ 531 StabCtlBrkActv_B_Actl 1;
BA_ "U_P708_MY2023_Rx" SG_ 531 StabCtlBrkActv_B_Actl 1;
BA_ "U_P702_MY2024_Rx" SG_ 531 StabCtlBrkActv_B_Actl 1;
BA_ "U_P708_MY2023_Rx" SG_ 531 CmbbBrkPrchg_B_Actl 1;
BA_ "U_P702_MY2024_Rx" SG_ 531 CmbbBrkPrchg_B_Actl 1;
BA_ "U_P708_MY2023_Rx" SG_ 531 CmbbBrkDecel_B_Actl 1;
BA_ "U_CDX707_MY2023_Rx" SG_ 531 CmbbBrkDecel_B_Actl 1;
BA_ "U_P702_MY2024_Rx" SG_ 531 CmbbBrkDecel_B_Actl 1;
BA_ "U_P708_MY2023_Rx" SG_ 531 AccBrkTotTqMn_B_Actl 1;
BA_ "U_P702_MY2024_Rx" SG_ 531 AccBrkTotTqMn_B_Actl 1;
BA_ "U_P708_MY2023_Rx" SG_ 531 AbsActv_B_Actl 1;
BA_ "U_P702_MY2024_Rx" SG_ 531 AbsActv_B_Actl 1;
BA_ "U_V710_MY2023_Rx" SG_ 531 AbsActv_B_Actl 1;
BA_ "U_P708_MY2023_Rx" SG_ 531 VehLongOvrGnd_A_Est 1;
BA_ "U_P702_MY2024_Rx" SG_ 531 VehLongOvrGnd_A_Est 1;
BA_ "U_P708_MY2023_Rx" SG_ 702 PHONE_MC_WORD_Rx 1;
BA_ "U_V713N_MY2022_Tx" SG_ 702 PHONE_MC_WORD_Rx 1;
BA_ "U_V713AV_MY2022_Tx" SG_ 702 PHONE_MC_WORD_Rx 1;
BA_ "U_P708_MY2023_Tx" SG_ 702 PHONE_MC_WORD_Rx 1;
BA_ "U_V710_MY2023_Tx" SG_ 702 PHONE_MC_WORD_Rx 1;
BA_ "U_P708_MY2023_Rx" SG_ 711 MyKeySrvr_Clnt_Word_Tx 1;
BA_ "U_V710_MY2023_Tx" SG_ 711 MyKeySrvr_Clnt_Word_Tx 1;
BA_ "GenSigSendType" SG_ 549 BattTracLoThres_D_Rq2 3;
BA_ "U_V710_MY2023_Tx" SG_ 549 BattTracLoThres_D_Rq2 1;
BA_ "U_P702_MY2024_Tx" SG_ 549 BattTracLoThres_D_Rq2 1;
BA_ "GenSigSendType" SG_ 549 NavIod_D_Rq 3;
BA_ "U_P708_MY2023_Tx" SG_ 549 NavIod_D_Rq 1;
BA_ "U_V710_MY2023_Tx" SG_ 549 NavIod_D_Rq 1;
BA_ "GenSigSendType" SG_ 549 StrtInGearOk_D_Stat 3;
BA_ "U_P708_MY2023_Tx" SG_ 549 StrtInGearOk_D_Stat 1;
BA_ "U_V713AV_MY2022_Tx" SG_ 549 StrtInGearOk_D_Stat 1;
BA_ "U_V710_MY2023_Tx" SG_ 549 StrtInGearOk_D_Stat 1;
BA_ "U_P702_MY2024_Tx" SG_ 549 StrtInGearOk_D_Stat 1;
BA_ "GenSigSendType" SG_ 549 WwaActv_B_Stat 3;
BA_ "U_V713N_MY2022_Rx" SG_ 549 WwaActv_B_Stat 1;
BA_ "U_V713AV_MY2022_Rx" SG_ 549 WwaActv_B_Stat 1;
BA_ "U_P708_MY2023_Rx" SG_ 549 WwaActv_B_Stat 1;
BA_ "U_V710_MY2023_Rx" SG_ 549 WwaActv_B_Stat 1;
BA_ "U_V713N_MY2022_Tx" SG_ 549 WwaActv_B_Stat 1;
BA_ "U_V713AV_MY2022_Tx" SG_ 549 WwaActv_B_Stat 1;
BA_ "U_V710_MY2023_Tx" SG_ 549 WwaActv_B_Stat 1;
BA_ "U_P708_MY2023_Tx" SG_ 549 WwaActv_B_Stat 1;
BA_ "U_P702_MY2024_Tx" SG_ 549 WwaActv_B_Stat 1;
BA_ "GenSigSendType" SG_ 549 Veh_V2_Dsply 3;
BA_ "U_P708_MY2023_Rx" SG_ 549 Veh_V2_Dsply 1;
BA_ "U_P702_MY2024_Rx" SG_ 549 Veh_V2_Dsply 1;
BA_ "U_V713N_MY2022_Tx" SG_ 549 Veh_V2_Dsply 1;
BA_ "U_V713AV_MY2022_Tx" SG_ 549 Veh_V2_Dsply 1;
BA_ "U_P708_MY2023_Tx" SG_ 549 Veh_V2_Dsply 1;
BA_ "U_V710_MY2023_Tx" SG_ 549 Veh_V2_Dsply 1;
BA_ "U_P702_MY2024_Tx" SG_ 549 Veh_V2_Dsply 1;
BA_ "GenSigSendType" SG_ 549 IPC_MyKeyVolLimit_St 3;
BA_ "U_V713N_MY2022_Rx" SG_ 549 IPC_MyKeyVolLimit_St 1;
BA_ "U_V713AV_MY2022_Rx" SG_ 549 IPC_MyKeyVolLimit_St 1;
BA_ "U_P708_MY2023_Rx" SG_ 549 IPC_MyKeyVolLimit_St 1;
BA_ "U_V710_MY2023_Rx" SG_ 549 IPC_MyKeyVolLimit_St 1;
BA_ "U_CDX74X_MY2024_Rx" SG_ 549 IPC_MyKeyVolLimit_St 1;
BA_ "U_V713N_MY2022_Tx" SG_ 549 IPC_MyKeyVolLimit_St 1;
BA_ "U_V713AV_MY2022_Tx" SG_ 549 IPC_MyKeyVolLimit_St 1;
BA_ "U_P708_MY2023_Tx" SG_ 549 IPC_MyKeyVolLimit_St 1;
BA_ "U_V710_MY2023_Tx" SG_ 549 IPC_MyKeyVolLimit_St 1;
BA_ "U_P702_MY2024_Tx" SG_ 549 IPC_MyKeyVolLimit_St 1;
BA_ "GenSigSendType" SG_ 549 HudVertSzMnuOn_B_Rq 3;
BA_ "U_P708_MY2023_Rx" SG_ 549 HudVertSzMnuOn_B_Rq 1;
BA_ "U_P702_MY2024_Rx" SG_ 549 HudVertSzMnuOn_B_Rq 1;
BA_ "U_V713N_MY2022_Tx" SG_ 549 HudVertSzMnuOn_B_Rq 1;
BA_ "U_V713AV_MY2022_Tx" SG_ 549 HudVertSzMnuOn_B_Rq 1;
BA_ "U_V710_MY2023_Tx" SG_ 549 HudVertSzMnuOn_B_Rq 1;
BA_ "U_P708_MY2023_Tx" SG_ 549 HudVertSzMnuOn_B_Rq 1;
BA_ "U_P702_MY2024_Tx" SG_ 549 HudVertSzMnuOn_B_Rq 1;
BA_ "GenSigSendType" SG_ 549 HudVertMnuOn_B_Rq 3;
BA_ "U_P708_MY2023_Rx" SG_ 549 HudVertMnuOn_B_Rq 1;
BA_ "U_P702_MY2024_Rx" SG_ 549 HudVertMnuOn_B_Rq 1;
BA_ "U_V713N_MY2022_Tx" SG_ 549 HudVertMnuOn_B_Rq 1;
BA_ "U_V713AV_MY2022_Tx" SG_ 549 HudVertMnuOn_B_Rq 1;
BA_ "U_V710_MY2023_Tx" SG_ 549 HudVertMnuOn_B_Rq 1;
BA_ "U_P708_MY2023_Tx" SG_ 549 HudVertMnuOn_B_Rq 1;
BA_ "U_P702_MY2024_Tx" SG_ 549 HudVertMnuOn_B_Rq 1;
BA_ "GenSigSendType" SG_ 549 HudRotatMnuOn_B_Rq 3;
BA_ "U_P708_MY2023_Rx" SG_ 549 HudRotatMnuOn_B_Rq 1;
BA_ "U_P702_MY2024_Rx" SG_ 549 HudRotatMnuOn_B_Rq 1;
BA_ "U_V713N_MY2022_Tx" SG_ 549 HudRotatMnuOn_B_Rq 1;
BA_ "U_V713AV_MY2022_Tx" SG_ 549 HudRotatMnuOn_B_Rq 1;
BA_ "U_P708_MY2023_Tx" SG_ 549 HudRotatMnuOn_B_Rq 1;
BA_ "U_V710_MY2023_Tx" SG_ 549 HudRotatMnuOn_B_Rq 1;
BA_ "U_P702_MY2024_Tx" SG_ 549 HudRotatMnuOn_B_Rq 1;
BA_ "GenSigSendType" SG_ 549 HudCntntMnuOn_B_Rq 3;
BA_ "U_P708_MY2023_Rx" SG_ 549 HudCntntMnuOn_B_Rq 1;
BA_ "U_P702_MY2024_Rx" SG_ 549 HudCntntMnuOn_B_Rq 1;
BA_ "U_V713N_MY2022_Tx" SG_ 549 HudCntntMnuOn_B_Rq 1;
BA_ "U_V713AV_MY2022_Tx" SG_ 549 HudCntntMnuOn_B_Rq 1;
BA_ "U_V710_MY2023_Tx" SG_ 549 HudCntntMnuOn_B_Rq 1;
BA_ "U_P708_MY2023_Tx" SG_ 549 HudCntntMnuOn_B_Rq 1;
BA_ "U_P702_MY2024_Tx" SG_ 549 HudCntntMnuOn_B_Rq 1;
BA_ "GenSigSendType" SG_ 549 HudBrightMnuOn_B_Rq 3;
BA_ "U_P708_MY2023_Rx" SG_ 549 HudBrightMnuOn_B_Rq 1;
BA_ "U_P702_MY2024_Rx" SG_ 549 HudBrightMnuOn_B_Rq 1;
BA_ "U_V713N_MY2022_Tx" SG_ 549 HudBrightMnuOn_B_Rq 1;
BA_ "U_V713AV_MY2022_Tx" SG_ 549 HudBrightMnuOn_B_Rq 1;
BA_ "U_V710_MY2023_Tx" SG_ 549 HudBrightMnuOn_B_Rq 1;
BA_ "U_P708_MY2023_Tx" SG_ 549 HudBrightMnuOn_B_Rq 1;
BA_ "U_P702_MY2024_Tx" SG_ 549 HudBrightMnuOn_B_Rq 1;
BA_ "GenSigSendType" SG_ 549 HdcOn_B_Rq 3;
BA_ "U_V713N_MY2022_Tx" SG_ 549 HdcOn_B_Rq 1;
BA_ "U_V713AV_MY2022_Tx" SG_ 549 HdcOn_B_Rq 1;
BA_ "U_P708_MY2023_Tx" SG_ 549 HdcOn_B_Rq 1;
BA_ "U_V710_MY2023_Tx" SG_ 549 HdcOn_B_Rq 1;
BA_ "U_P702_MY2024_Tx" SG_ 549 HdcOn_B_Rq 1;
BA_ "GenSigSendType" SG_ 549 IPC_Attn_Info_Audio 3;
BA_ "U_V713N_MY2022_Rx" SG_ 549 IPC_Attn_Info_Audio 1;
BA_ "U_V713AV_MY2022_Rx" SG_ 549 IPC_Attn_Info_Audio 1;
BA_ "U_P708_MY2023_Rx" SG_ 549 IPC_Attn_Info_Audio 1;
BA_ "U_V710_MY2023_Rx" SG_ 549 IPC_Attn_Info_Audio 1;
BA_ "U_CDX74X_MY2024_Rx" SG_ 549 IPC_Attn_Info_Audio 1;
BA_ "U_V713N_MY2022_Tx" SG_ 549 IPC_Attn_Info_Audio 1;
BA_ "U_V713AV_MY2022_Tx" SG_ 549 IPC_Attn_Info_Audio 1;
BA_ "U_P708_MY2023_Tx" SG_ 549 IPC_Attn_Info_Audio 1;
BA_ "U_V710_MY2023_Tx" SG_ 549 IPC_Attn_Info_Audio 1;
BA_ "U_P702_MY2024_Tx" SG_ 549 IPC_Attn_Info_Audio 1;
BA_ "GenSigSendType" SG_ 549 BeltminderAudioMute 3;
BA_ "U_V713N_MY2022_Rx" SG_ 549 BeltminderAudioMute 1;
BA_ "U_V713AV_MY2022_Rx" SG_ 549 BeltminderAudioMute 1;
BA_ "U_P708_MY2023_Rx" SG_ 549 BeltminderAudioMute 1;
BA_ "U_V710_MY2023_Rx" SG_ 549 BeltminderAudioMute 1;
BA_ "U_CDX74X_MY2024_Rx" SG_ 549 BeltminderAudioMute 1;
BA_ "U_V713N_MY2022_Tx" SG_ 549 BeltminderAudioMute 1;
BA_ "U_V713AV_MY2022_Tx" SG_ 549 BeltminderAudioMute 1;
BA_ "U_P708_MY2023_Tx" SG_ 549 BeltminderAudioMute 1;
BA_ "U_V710_MY2023_Tx" SG_ 549 BeltminderAudioMute 1;
BA_ "U_P702_MY2024_Tx" SG_ 549 BeltminderAudioMute 1;
BA_ "WakeupSignal" SG_ 549 Power_Up_Chime_Modules 1;
BA_ "GenSigSendType" SG_ 549 Power_Up_Chime_Modules 3;
BA_ "U_V713N_MY2022_Rx" SG_ 549 Power_Up_Chime_Modules 1;
BA_ "U_V713AV_MY2022_Rx" SG_ 549 Power_Up_Chime_Modules 1;
BA_ "U_P708_MY2023_Rx" SG_ 549 Power_Up_Chime_Modules 1;
BA_ "U_V710_MY2023_Rx" SG_ 549 Power_Up_Chime_Modules 1;
BA_ "ECGUsedRxSignal" SG_ 549 Power_Up_Chime_Modules 1;
BA_ "U_CDX74X_MY2024_Rx" SG_ 549 Power_Up_Chime_Modules 1;
BA_ "U_V713N_MY2022_Tx" SG_ 549 Power_Up_Chime_Modules 1;
BA_ "U_V713AV_MY2022_Tx" SG_ 549 Power_Up_Chime_Modules 1;
BA_ "U_P708_MY2023_Tx" SG_ 549 Power_Up_Chime_Modules 1;
BA_ "U_V710_MY2023_Tx" SG_ 549 Power_Up_Chime_Modules 1;
BA_ "U_P702_MY2024_Tx" SG_ 549 Power_Up_Chime_Modules 1;
BA_ "GenSigSendType" SG_ 549 Chime_Source 3;
BA_ "U_V713N_MY2022_Rx" SG_ 549 Chime_Source 1;
BA_ "U_V713AV_MY2022_Rx" SG_ 549 Chime_Source 1;
BA_ "U_P708_MY2023_Rx" SG_ 549 Chime_Source 1;
BA_ "U_V710_MY2023_Rx" SG_ 549 Chime_Source 1;
BA_ "U_CDX74X_MY2024_Rx" SG_ 549 Chime_Source 1;
BA_ "ECGUsedRxSignal" SG_ 549 Chime_Source 1;
BA_ "U_V713N_MY2022_Tx" SG_ 549 Chime_Source 1;
BA_ "U_V713AV_MY2022_Tx" SG_ 549 Chime_Source 1;
BA_ "U_P708_MY2023_Tx" SG_ 549 Chime_Source 1;
BA_ "U_V710_MY2023_Tx" SG_ 549 Chime_Source 1;
BA_ "U_P702_MY2024_Tx" SG_ 549 Chime_Source 1;
BA_ "GenSigSendType" SG_ 549 TjaLcEnbl_D_DrvRq 3;
BA_ "U_P702_MY2024_Tx" SG_ 549 TjaLcEnbl_D_DrvRq 1;
BA_ "GenSigSendType" SG_ 549 CCOI_PolicyClient_St2 3;
BA_ "ECGUsedRxSignal" SG_ 549 CCOI_PolicyClient_St2 1;
BA_ "U_CDX74X_MY2024_Rx" SG_ 549 CCOI_PolicyClient_St2 1;
BA_ "U_V710_MY2023_Rx" SG_ 549 CCOI_PolicyClient_St2 1;
BA_ "U_P708_MY2023_Tx" SG_ 549 CCOI_PolicyClient_St2 1;
BA_ "U_V710_MY2023_Tx" SG_ 549 CCOI_PolicyClient_St2 1;
BA_ "U_P702_MY2024_Tx" SG_ 549 CCOI_PolicyClient_St2 1;
BA_ "GenSigSendType" SG_ 549 FactoryReset_Rq2 3;
BA_ "ECGUsedRxSignal" SG_ 549 FactoryReset_Rq2 1;
BA_ "U_CDX74X_MY2024_Rx" SG_ 549 FactoryReset_Rq2 1;
BA_ "U_V710_MY2023_Rx" SG_ 549 FactoryReset_Rq2 1;
BA_ "U_P708_MY2023_Tx" SG_ 549 FactoryReset_Rq2 1;
BA_ "U_V710_MY2023_Tx" SG_ 549 FactoryReset_Rq2 1;
BA_ "U_P702_MY2024_Tx" SG_ 549 FactoryReset_Rq2 1;
BA_ "GenSigSendType" SG_ 549 IPC_New_Attn_Event 3;
BA_ "U_V713N_MY2022_Rx" SG_ 549 IPC_New_Attn_Event 1;
BA_ "U_V713AV_MY2022_Rx" SG_ 549 IPC_New_Attn_Event 1;
BA_ "U_P708_MY2023_Rx" SG_ 549 IPC_New_Attn_Event 1;
BA_ "U_V710_MY2023_Rx" SG_ 549 IPC_New_Attn_Event 1;
BA_ "U_CDX74X_MY2024_Rx" SG_ 549 IPC_New_Attn_Event 1;
BA_ "U_V713N_MY2022_Tx" SG_ 549 IPC_New_Attn_Event 1;
BA_ "U_V713AV_MY2022_Tx" SG_ 549 IPC_New_Attn_Event 1;
BA_ "U_P708_MY2023_Tx" SG_ 549 IPC_New_Attn_Event 1;
BA_ "U_V710_MY2023_Tx" SG_ 549 IPC_New_Attn_Event 1;
BA_ "U_P702_MY2024_Tx" SG_ 549 IPC_New_Attn_Event 1;
BA_ "GenSigSendType" SG_ 549 MetricActv_B_Dsply 3;
BA_ "U_P708_MY2023_Rx" SG_ 549 MetricActv_B_Dsply 1;
BA_ "U_P702_MY2024_Rx" SG_ 549 MetricActv_B_Dsply 1;
BA_ "U_V713N_MY2022_Tx" SG_ 549 MetricActv_B_Dsply 1;
BA_ "U_V713AV_MY2022_Tx" SG_ 549 MetricActv_B_Dsply 1;
BA_ "U_P708_MY2023_Tx" SG_ 549 MetricActv_B_Dsply 1;
BA_ "U_V710_MY2023_Tx" SG_ 549 MetricActv_B_Dsply 1;
BA_ "U_P702_MY2024_Tx" SG_ 549 MetricActv_B_Dsply 1;
BA_ "GenSigStartValue" SG_ 765 BalrSwtch_D_Stat 1;
BA_ "GenSigSendType" SG_ 765 BalrSwtch_D_Stat 3;
BA_ "U_V713AV_MY2022_Tx" SG_ 765 BalrSwtch_D_Stat 1;
BA_ "U_P708_MY2023_Tx" SG_ 765 BalrSwtch_D_Stat 1;
BA_ "U_V710_MY2023_Tx" SG_ 765 BalrSwtch_D_Stat 1;
BA_ "U_V713N_MY2022_Tx" SG_ 765 BalrSwtch_D_Stat 1;
BA_ "U_P702_MY2024_Tx" SG_ 765 BalrSwtch_D_Stat 1;
BA_ "GenSigSendType" SG_ 765 BalrMde_D_Rq 3;
BA_ "U_V713AV_MY2022_Tx" SG_ 765 BalrMde_D_Rq 1;
BA_ "U_P708_MY2023_Tx" SG_ 765 BalrMde_D_Rq 1;
BA_ "U_V710_MY2023_Tx" SG_ 765 BalrMde_D_Rq 1;
BA_ "U_V713N_MY2022_Tx" SG_ 765 BalrMde_D_Rq 1;
BA_ "U_P702_MY2024_Tx" SG_ 765 BalrMde_D_Rq 1;
BA_ "GenSigSendType" SG_ 765 RstrnOnPsngr_D_RqMnu 3;
BA_ "U_V713AV_MY2022_Tx" SG_ 765 RstrnOnPsngr_D_RqMnu 1;
BA_ "U_P708_MY2023_Tx" SG_ 765 RstrnOnPsngr_D_RqMnu 1;
BA_ "U_V710_MY2023_Tx" SG_ 765 RstrnOnPsngr_D_RqMnu 1;
BA_ "U_V713N_MY2022_Tx" SG_ 765 RstrnOnPsngr_D_RqMnu 1;
BA_ "U_P702_MY2024_Tx" SG_ 765 RstrnOnPsngr_D_RqMnu 1;
BA_ "GenSigStartValue" SG_ 765 WaitToStartLamp_D_Falt 1;
BA_ "GenSigSendType" SG_ 765 WaitToStartLamp_D_Falt 3;
BA_ "U_V713N_MY2022_Tx" SG_ 765 WaitToStartLamp_D_Falt 1;
BA_ "U_V713AV_MY2022_Tx" SG_ 765 WaitToStartLamp_D_Falt 1;
BA_ "U_P708_MY2023_Tx" SG_ 765 WaitToStartLamp_D_Falt 1;
BA_ "U_V710_MY2023_Tx" SG_ 765 WaitToStartLamp_D_Falt 1;
BA_ "U_P702_MY2024_Tx" SG_ 765 WaitToStartLamp_D_Falt 1;
BA_ "GenSigStartValue" SG_ 765 EsaOn_B_Rq 1;
BA_ "GenSigSendType" SG_ 765 EsaOn_B_Rq 3;
BA_ "U_V713N_MY2022_Tx" SG_ 765 EsaOn_B_Rq 1;
BA_ "U_V713AV_MY2022_Tx" SG_ 765 EsaOn_B_Rq 1;
BA_ "U_P708_MY2023_Tx" SG_ 765 EsaOn_B_Rq 1;
BA_ "U_V710_MY2023_Tx" SG_ 765 EsaOn_B_Rq 1;
BA_ "U_P702_MY2024_Tx" SG_ 765 EsaOn_B_Rq 1;
BA_ "GenSigSendType" SG_ 765 BttOn_B_Rq 3;
BA_ "U_V713N_MY2022_Tx" SG_ 765 BttOn_B_Rq 1;
BA_ "U_V713AV_MY2022_Tx" SG_ 765 BttOn_B_Rq 1;
BA_ "U_P708_MY2023_Tx" SG_ 765 BttOn_B_Rq 1;
BA_ "U_V710_MY2023_Tx" SG_ 765 BttOn_B_Rq 1;
BA_ "U_P702_MY2024_Tx" SG_ 765 BttOn_B_Rq 1;
BA_ "GenSigStartValue" SG_ 765 Btt_L_Actl 126;
BA_ "U_V713N_MY2022_Tx" SG_ 765 Btt_L_Actl 1;
BA_ "U_V713AV_MY2022_Tx" SG_ 765 Btt_L_Actl 1;
BA_ "U_P708_MY2023_Tx" SG_ 765 Btt_L_Actl 1;
BA_ "U_V710_MY2023_Tx" SG_ 765 Btt_L_Actl 1;
BA_ "U_P702_MY2024_Tx" SG_ 765 Btt_L_Actl 1;
BA_ "GenSigStartValue" SG_ 765 RearDiffLck_D_RqArb 3;
BA_ "GenSigSendType" SG_ 765 RearDiffLck_D_RqArb 3;
BA_ "U_V713N_MY2022_Tx" SG_ 765 RearDiffLck_D_RqArb 1;
BA_ "U_V713AV_MY2022_Tx" SG_ 765 RearDiffLck_D_RqArb 1;
BA_ "U_P708_MY2023_Tx" SG_ 765 RearDiffLck_D_RqArb 1;
BA_ "U_V710_MY2023_Tx" SG_ 765 RearDiffLck_D_RqArb 1;
BA_ "U_P702_MY2024_Tx" SG_ 765 RearDiffLck_D_RqArb 1;
BA_ "GenSigStartValue" SG_ 765 AwdMde_D_RqArb 5;
BA_ "GenSigSendType" SG_ 765 AwdMde_D_RqArb 3;
BA_ "U_V713N_MY2022_Tx" SG_ 765 AwdMde_D_RqArb 1;
BA_ "U_V713AV_MY2022_Tx" SG_ 765 AwdMde_D_RqArb 1;
BA_ "U_P708_MY2023_Tx" SG_ 765 AwdMde_D_RqArb 1;
BA_ "U_V710_MY2023_Tx" SG_ 765 AwdMde_D_RqArb 1;
BA_ "U_P702_MY2024_Tx" SG_ 765 AwdMde_D_RqArb 1;
BA_ "GenSigSendType" SG_ 765 SelDrvMdeTxtReset_B_Rq 3;
BA_ "U_V713N_MY2022_Tx" SG_ 765 SelDrvMdeTxtReset_B_Rq 1;
BA_ "U_V713AV_MY2022_Tx" SG_ 765 SelDrvMdeTxtReset_B_Rq 1;
BA_ "U_P708_MY2023_Tx" SG_ 765 SelDrvMdeTxtReset_B_Rq 1;
BA_ "U_V710_MY2023_Tx" SG_ 765 SelDrvMdeTxtReset_B_Rq 1;
BA_ "U_P702_MY2024_Tx" SG_ 765 SelDrvMdeTxtReset_B_Rq 1;
BA_ "GenSigSendType" SG_ 765 AutoTowAllw_D_RqMnu 3;
BA_ "U_V713N_MY2022_Tx" SG_ 765 AutoTowAllw_D_RqMnu 1;
BA_ "U_V713AV_MY2022_Tx" SG_ 765 AutoTowAllw_D_RqMnu 1;
BA_ "U_P708_MY2023_Tx" SG_ 765 AutoTowAllw_D_RqMnu 1;
BA_ "U_V710_MY2023_Tx" SG_ 765 AutoTowAllw_D_RqMnu 1;
BA_ "U_P702_MY2024_Tx" SG_ 765 AutoTowAllw_D_RqMnu 1;
BA_ "WakeupSignal" SG_ 765 DrvInputRequired_B_Rq 1;
BA_ "GenSigSendType" SG_ 765 DrvInputRequired_B_Rq 3;
BA_ "U_V713N_MY2022_Tx" SG_ 765 DrvInputRequired_B_Rq 1;
BA_ "U_V713AV_MY2022_Tx" SG_ 765 DrvInputRequired_B_Rq 1;
BA_ "U_P708_MY2023_Tx" SG_ 765 DrvInputRequired_B_Rq 1;
BA_ "U_V710_MY2023_Tx" SG_ 765 DrvInputRequired_B_Rq 1;
BA_ "U_P702_MY2024_Tx" SG_ 765 DrvInputRequired_B_Rq 1;
BA_ "GenSigSendType" SG_ 765 SelDrvMdeDsply_B_Avail 3;
BA_ "U_V713N_MY2022_Tx" SG_ 765 SelDrvMdeDsply_B_Avail 1;
BA_ "U_V713AV_MY2022_Tx" SG_ 765 SelDrvMdeDsply_B_Avail 1;
BA_ "U_P708_MY2023_Tx" SG_ 765 SelDrvMdeDsply_B_Avail 1;
BA_ "U_V710_MY2023_Tx" SG_ 765 SelDrvMdeDsply_B_Avail 1;
BA_ "U_P702_MY2024_Tx" SG_ 765 SelDrvMdeDsply_B_Avail 1;
BA_ "GenSigStartValue" SG_ 765 EngExhMdeQuiet_D_Rq 2;
BA_ "GenSigSendType" SG_ 765 EngExhMdeQuiet_D_Rq 3;
BA_ "U_V713N_MY2022_Tx" SG_ 765 EngExhMdeQuiet_D_Rq 1;
BA_ "U_V713AV_MY2022_Tx" SG_ 765 EngExhMdeQuiet_D_Rq 1;
BA_ "U_P708_MY2023_Tx" SG_ 765 EngExhMdeQuiet_D_Rq 1;
BA_ "U_V710_MY2023_Tx" SG_ 765 EngExhMdeQuiet_D_Rq 1;
BA_ "U_P702_MY2024_Tx" SG_ 765 EngExhMdeQuiet_D_Rq 1;
BA_ "GenSigSendType" SG_ 765 AirSusp_D_RqDrv 3;
BA_ "U_V713N_MY2022_Tx" SG_ 765 AirSusp_D_RqDrv 1;
BA_ "U_V713AV_MY2022_Tx" SG_ 765 AirSusp_D_RqDrv 1;
BA_ "U_P708_MY2023_Tx" SG_ 765 AirSusp_D_RqDrv 1;
BA_ "U_V710_MY2023_Tx" SG_ 765 AirSusp_D_RqDrv 1;
BA_ "U_P702_MY2024_Tx" SG_ 765 AirSusp_D_RqDrv 1;
BA_ "GenSigSendType" SG_ 765 Mc_VehUntTrpCoUsrSel_St 3;
BA_ "U_P708_MY2023_Rx" SG_ 765 Mc_VehUntTrpCoUsrSel_St 1;
BA_ "U_P702_MY2024_Rx" SG_ 765 Mc_VehUntTrpCoUsrSel_St 1;
BA_ "ECGUsedRxSignal" SG_ 765 Mc_VehUntTrpCoUsrSel_St 1;
BA_ "U_V713N_MY2022_Rx" SG_ 765 Mc_VehUntTrpCoUsrSel_St 1;
BA_ "U_V713AV_MY2022_Rx" SG_ 765 Mc_VehUntTrpCoUsrSel_St 1;
BA_ "U_CDX74X_MY2024_Rx" SG_ 765 Mc_VehUntTrpCoUsrSel_St 1;
BA_ "U_V710_MY2023_Rx" SG_ 765 Mc_VehUntTrpCoUsrSel_St 1;
BA_ "U_V713N_MY2022_Tx" SG_ 765 Mc_VehUntTrpCoUsrSel_St 1;
BA_ "U_V713AV_MY2022_Tx" SG_ 765 Mc_VehUntTrpCoUsrSel_St 1;
BA_ "U_P708_MY2023_Tx" SG_ 765 Mc_VehUntTrpCoUsrSel_St 1;
BA_ "U_V710_MY2023_Tx" SG_ 765 Mc_VehUntTrpCoUsrSel_St 1;
BA_ "U_P702_MY2024_Tx" SG_ 765 Mc_VehUntTrpCoUsrSel_St 1;
BA_ "GenSigSendType" SG_ 765 Mc_VehUnitTempUsrSel_St 3;
BA_ "U_CDX74X_MY2024_Rx" SG_ 765 Mc_VehUnitTempUsrSel_St 1;
BA_ "U_P708_MY2023_Rx" SG_ 765 Mc_VehUnitTempUsrSel_St 1;
BA_ "U_P702_MY2024_Rx" SG_ 765 Mc_VehUnitTempUsrSel_St 1;
BA_ "U_V713N_MY2022_Tx" SG_ 765 Mc_VehUnitTempUsrSel_St 1;
BA_ "U_V713AV_MY2022_Tx" SG_ 765 Mc_VehUnitTempUsrSel_St 1;
BA_ "U_P708_MY2023_Tx" SG_ 765 Mc_VehUnitTempUsrSel_St 1;
BA_ "U_V710_MY2023_Tx" SG_ 765 Mc_VehUnitTempUsrSel_St 1;
BA_ "U_P702_MY2024_Tx" SG_ 765 Mc_VehUnitTempUsrSel_St 1;
BA_ "GenSigSendType" SG_ 765 Mc_VehDayNightUsrSel_St 3;
BA_ "U_V713N_MY2022_Rx" SG_ 765 Mc_VehDayNightUsrSel_St 1;
BA_ "U_V713AV_MY2022_Rx" SG_ 765 Mc_VehDayNightUsrSel_St 1;
BA_ "U_P708_MY2023_Rx" SG_ 765 Mc_VehDayNightUsrSel_St 1;
BA_ "U_V710_MY2023_Rx" SG_ 765 Mc_VehDayNightUsrSel_St 1;
BA_ "U_V713N_MY2022_Tx" SG_ 765 Mc_VehDayNightUsrSel_St 1;
BA_ "U_V713AV_MY2022_Tx" SG_ 765 Mc_VehDayNightUsrSel_St 1;
BA_ "U_P708_MY2023_Tx" SG_ 765 Mc_VehDayNightUsrSel_St 1;
BA_ "U_V710_MY2023_Tx" SG_ 765 Mc_VehDayNightUsrSel_St 1;
BA_ "U_P702_MY2024_Tx" SG_ 765 Mc_VehDayNightUsrSel_St 1;
BA_ "GenSigSendType" SG_ 765 Mc_VehTimeFrmtUsrSel_St 3;
BA_ "U_CDX74X_MY2024_Rx" SG_ 765 Mc_VehTimeFrmtUsrSel_St 1;
BA_ "U_P708_MY2023_Rx" SG_ 765 Mc_VehTimeFrmtUsrSel_St 1;
BA_ "U_P702_MY2024_Rx" SG_ 765 Mc_VehTimeFrmtUsrSel_St 1;
BA_ "U_V713N_MY2022_Tx" SG_ 765 Mc_VehTimeFrmtUsrSel_St 1;
BA_ "U_V713AV_MY2022_Tx" SG_ 765 Mc_VehTimeFrmtUsrSel_St 1;
BA_ "U_P708_MY2023_Tx" SG_ 765 Mc_VehTimeFrmtUsrSel_St 1;
BA_ "U_V710_MY2023_Tx" SG_ 765 Mc_VehTimeFrmtUsrSel_St 1;
BA_ "U_P702_MY2024_Tx" SG_ 765 Mc_VehTimeFrmtUsrSel_St 1;
BA_ "GenSigSendType" SG_ 765 Mc_VehThemeUsrSel_St 3;
BA_ "U_P708_MY2023_Rx" SG_ 765 Mc_VehThemeUsrSel_St 1;
BA_ "U_V713N_MY2022_Tx" SG_ 765 Mc_VehThemeUsrSel_St 1;
BA_ "U_V713AV_MY2022_Tx" SG_ 765 Mc_VehThemeUsrSel_St 1;
BA_ "U_P708_MY2023_Tx" SG_ 765 Mc_VehThemeUsrSel_St 1;
BA_ "U_V710_MY2023_Tx" SG_ 765 Mc_VehThemeUsrSel_St 1;
BA_ "U_P702_MY2024_Tx" SG_ 765 Mc_VehThemeUsrSel_St 1;
BA_ "GenSigSendType" SG_ 765 Mc_VehLangUsrSel_St 3;
BA_ "U_V713N_MY2022_Rx" SG_ 765 Mc_VehLangUsrSel_St 1;
BA_ "U_V713AV_MY2022_Rx" SG_ 765 Mc_VehLangUsrSel_St 1;
BA_ "U_P708_MY2023_Rx" SG_ 765 Mc_VehLangUsrSel_St 1;
BA_ "U_V710_MY2023_Rx" SG_ 765 Mc_VehLangUsrSel_St 1;
BA_ "U_P702_MY2024_Rx" SG_ 765 Mc_VehLangUsrSel_St 1;
BA_ "U_V713N_MY2022_Tx" SG_ 765 Mc_VehLangUsrSel_St 1;
BA_ "U_V713AV_MY2022_Tx" SG_ 765 Mc_VehLangUsrSel_St 1;
BA_ "U_P708_MY2023_Tx" SG_ 765 Mc_VehLangUsrSel_St 1;
BA_ "U_V710_MY2023_Tx" SG_ 765 Mc_VehLangUsrSel_St 1;
BA_ "U_P702_MY2024_Tx" SG_ 765 Mc_VehLangUsrSel_St 1;
BA_ "GenSigStartValue" SG_ 765 AwdRnge_D_ActlIpc 7;
BA_ "GenSigSendType" SG_ 765 AwdRnge_D_ActlIpc 3;
BA_ "U_V713N_MY2022_Tx" SG_ 765 AwdRnge_D_ActlIpc 1;
BA_ "U_V713AV_MY2022_Tx" SG_ 765 AwdRnge_D_ActlIpc 1;
BA_ "U_P708_MY2023_Tx" SG_ 765 AwdRnge_D_ActlIpc 1;
BA_ "U_V710_MY2023_Tx" SG_ 765 AwdRnge_D_ActlIpc 1;
BA_ "U_P702_MY2024_Tx" SG_ 765 AwdRnge_D_ActlIpc 1;
BA_ "GenSigSendType" SG_ 765 AwdDrvMde_D_Rq 3;
BA_ "U_V713N_MY2022_Tx" SG_ 765 AwdDrvMde_D_Rq 1;
BA_ "U_V713AV_MY2022_Tx" SG_ 765 AwdDrvMde_D_Rq 1;
BA_ "U_P708_MY2023_Tx" SG_ 765 AwdDrvMde_D_Rq 1;
BA_ "U_V710_MY2023_Tx" SG_ 765 AwdDrvMde_D_Rq 1;
BA_ "U_P702_MY2024_Tx" SG_ 765 AwdDrvMde_D_Rq 1;
BA_ "GenSigSendType" SG_ 765 EngExhMdeQuiet_D2_Rq 3;
BA_ "U_V713N_MY2022_Tx" SG_ 765 EngExhMdeQuiet_D2_Rq 1;
BA_ "U_V713AV_MY2022_Tx" SG_ 765 EngExhMdeQuiet_D2_Rq 1;
BA_ "U_P708_MY2023_Tx" SG_ 765 EngExhMdeQuiet_D2_Rq 1;
BA_ "U_V710_MY2023_Tx" SG_ 765 EngExhMdeQuiet_D2_Rq 1;
BA_ "U_P702_MY2024_Tx" SG_ 765 EngExhMdeQuiet_D2_Rq 1;
BA_ "GenSigSendType" SG_ 765 BrkLineLck_D_Rq 3;
BA_ "U_V713N_MY2022_Tx" SG_ 765 BrkLineLck_D_Rq 1;
BA_ "U_V713AV_MY2022_Tx" SG_ 765 BrkLineLck_D_Rq 1;
BA_ "U_P708_MY2023_Tx" SG_ 765 BrkLineLck_D_Rq 1;
BA_ "U_V710_MY2023_Tx" SG_ 765 BrkLineLck_D_Rq 1;
BA_ "U_P702_MY2024_Tx" SG_ 765 BrkLineLck_D_Rq 1;
BA_ "GenSigSendType" SG_ 765 EdmSailMde_B_RqDrv 3;
BA_ "U_V713N_MY2022_Tx" SG_ 765 EdmSailMde_B_RqDrv 1;
BA_ "U_V713AV_MY2022_Tx" SG_ 765 EdmSailMde_B_RqDrv 1;
BA_ "U_P708_MY2023_Tx" SG_ 765 EdmSailMde_B_RqDrv 1;
BA_ "U_V710_MY2023_Tx" SG_ 765 EdmSailMde_B_RqDrv 1;
BA_ "U_P702_MY2024_Tx" SG_ 765 EdmSailMde_B_RqDrv 1;
BA_ "GenSigSendType" SG_ 765 Running_Board_Cmd 3;
BA_ "U_P708_MY2023_Tx" SG_ 765 Running_Board_Cmd 1;
BA_ "U_V710_MY2023_Tx" SG_ 765 Running_Board_Cmd 1;
BA_ "U_V713AV_MY2022_Tx" SG_ 765 Running_Board_Cmd 1;
BA_ "U_P702_MY2024_Tx" SG_ 765 Running_Board_Cmd 1;
BA_ "GenSigSendType" SG_ 508 Mc_DB1GetInfStartInd_Rq 1;
BA_ "U_V713N_MY2022_Rx" SG_ 508 Mc_DB1GetInfStartInd_Rq 1;
BA_ "U_V713AV_MY2022_Rx" SG_ 508 Mc_DB1GetInfStartInd_Rq 1;
BA_ "U_P708_MY2023_Rx" SG_ 508 Mc_DB1GetInfStartInd_Rq 1;
BA_ "U_V710_MY2023_Rx" SG_ 508 Mc_DB1GetInfStartInd_Rq 1;
BA_ "U_P702_MY2024_Tx" SG_ 508 Mc_DB1GetInfStartInd_Rq 1;
BA_ "U_V713N_MY2022_Rx" SG_ 508 Mc_DB1GtInfNbrOfItms_Rq 1;
BA_ "U_V713AV_MY2022_Rx" SG_ 508 Mc_DB1GtInfNbrOfItms_Rq 1;
BA_ "U_P708_MY2023_Rx" SG_ 508 Mc_DB1GtInfNbrOfItms_Rq 1;
BA_ "U_V710_MY2023_Rx" SG_ 508 Mc_DB1GtInfNbrOfItms_Rq 1;
BA_ "U_P702_MY2024_Tx" SG_ 508 Mc_DB1GtInfNbrOfItms_Rq 1;
BA_ "U_V713N_MY2022_Rx" SG_ 508 Mc_DB1GetInfSetConf_Rq 1;
BA_ "U_V713AV_MY2022_Rx" SG_ 508 Mc_DB1GetInfSetConf_Rq 1;
BA_ "U_P708_MY2023_Rx" SG_ 508 Mc_DB1GetInfSetConf_Rq 1;
BA_ "U_V710_MY2023_Rx" SG_ 508 Mc_DB1GetInfSetConf_Rq 1;
BA_ "U_P702_MY2024_Tx" SG_ 508 Mc_DB1GetInfSetConf_Rq 1;
BA_ "U_V713N_MY2022_Rx" SG_ 508 Mc_DB1GetInfSetFilt3_Rq 1;
BA_ "U_V713AV_MY2022_Rx" SG_ 508 Mc_DB1GetInfSetFilt3_Rq 1;
BA_ "U_P708_MY2023_Rx" SG_ 508 Mc_DB1GetInfSetFilt3_Rq 1;
BA_ "U_V710_MY2023_Rx" SG_ 508 Mc_DB1GetInfSetFilt3_Rq 1;
BA_ "U_P702_MY2024_Tx" SG_ 508 Mc_DB1GetInfSetFilt3_Rq 1;
BA_ "U_V713N_MY2022_Rx" SG_ 508 Mc_DB1GetInfSetFilt2_Rq 1;
BA_ "U_V713AV_MY2022_Rx" SG_ 508 Mc_DB1GetInfSetFilt2_Rq 1;
BA_ "U_P708_MY2023_Rx" SG_ 508 Mc_DB1GetInfSetFilt2_Rq 1;
BA_ "U_V710_MY2023_Rx" SG_ 508 Mc_DB1GetInfSetFilt2_Rq 1;
BA_ "U_P702_MY2024_Tx" SG_ 508 Mc_DB1GetInfSetFilt2_Rq 1;
BA_ "U_V713N_MY2022_Rx" SG_ 508 Mc_DB1GetInfSetFilt1_Rq 1;
BA_ "U_V713AV_MY2022_Rx" SG_ 508 Mc_DB1GetInfSetFilt1_Rq 1;
BA_ "U_P708_MY2023_Rx" SG_ 508 Mc_DB1GetInfSetFilt1_Rq 1;
BA_ "U_V710_MY2023_Rx" SG_ 508 Mc_DB1GetInfSetFilt1_Rq 1;
BA_ "U_P702_MY2024_Tx" SG_ 508 Mc_DB1GetInfSetFilt1_Rq 1;
BA_ "GenSigSendType" SG_ 507 Mc_DB1SetTrkItmIndex_Rq 1;
BA_ "U_V713N_MY2022_Rx" SG_ 507 Mc_DB1SetTrkItmIndex_Rq 1;
BA_ "U_V713AV_MY2022_Rx" SG_ 507 Mc_DB1SetTrkItmIndex_Rq 1;
BA_ "U_P708_MY2023_Rx" SG_ 507 Mc_DB1SetTrkItmIndex_Rq 1;
BA_ "U_V710_MY2023_Rx" SG_ 507 Mc_DB1SetTrkItmIndex_Rq 1;
BA_ "U_P702_MY2024_Tx" SG_ 507 Mc_DB1SetTrkItmIndex_Rq 1;
BA_ "U_V713N_MY2022_Rx" SG_ 507 Mc_DB1SetTrkSetConf_Rq 1;
BA_ "U_V713AV_MY2022_Rx" SG_ 507 Mc_DB1SetTrkSetConf_Rq 1;
BA_ "U_P708_MY2023_Rx" SG_ 507 Mc_DB1SetTrkSetConf_Rq 1;
BA_ "U_V710_MY2023_Rx" SG_ 507 Mc_DB1SetTrkSetConf_Rq 1;
BA_ "U_P702_MY2024_Tx" SG_ 507 Mc_DB1SetTrkSetConf_Rq 1;
BA_ "U_V713N_MY2022_Rx" SG_ 507 Mc_DB1SetTrkSetFilt3_Rq 1;
BA_ "U_V713AV_MY2022_Rx" SG_ 507 Mc_DB1SetTrkSetFilt3_Rq 1;
BA_ "U_P708_MY2023_Rx" SG_ 507 Mc_DB1SetTrkSetFilt3_Rq 1;
BA_ "U_V710_MY2023_Rx" SG_ 507 Mc_DB1SetTrkSetFilt3_Rq 1;
BA_ "U_P702_MY2024_Tx" SG_ 507 Mc_DB1SetTrkSetFilt3_Rq 1;
BA_ "U_V713N_MY2022_Rx" SG_ 507 Mc_DB1SetTrkSetFilt2_Rq 1;
BA_ "U_V713AV_MY2022_Rx" SG_ 507 Mc_DB1SetTrkSetFilt2_Rq 1;
BA_ "U_P708_MY2023_Rx" SG_ 507 Mc_DB1SetTrkSetFilt2_Rq 1;
BA_ "U_V710_MY2023_Rx" SG_ 507 Mc_DB1SetTrkSetFilt2_Rq 1;
BA_ "U_P702_MY2024_Tx" SG_ 507 Mc_DB1SetTrkSetFilt2_Rq 1;
BA_ "U_V713N_MY2022_Rx" SG_ 507 Mc_DB1SetTrkSetFilt1_Rq 1;
BA_ "U_V713AV_MY2022_Rx" SG_ 507 Mc_DB1SetTrkSetFilt1_Rq 1;
BA_ "U_P708_MY2023_Rx" SG_ 507 Mc_DB1SetTrkSetFilt1_Rq 1;
BA_ "U_V710_MY2023_Rx" SG_ 507 Mc_DB1SetTrkSetFilt1_Rq 1;
BA_ "U_P702_MY2024_Tx" SG_ 507 Mc_DB1SetTrkSetFilt1_Rq 1;
BA_ "GenSigSendType" SG_ 506 Mc_AudioSourceSel3_Rq 3;
BA_ "U_V713N_MY2022_Rx" SG_ 506 Mc_AudioSourceSel3_Rq 1;
BA_ "U_V713AV_MY2022_Rx" SG_ 506 Mc_AudioSourceSel3_Rq 1;
BA_ "U_P708_MY2023_Rx" SG_ 506 Mc_AudioSourceSel3_Rq 1;
BA_ "U_V710_MY2023_Rx" SG_ 506 Mc_AudioSourceSel3_Rq 1;
BA_ "U_P702_MY2024_Tx" SG_ 506 Mc_AudioSourceSel3_Rq 1;
BA_ "U_V713N_MY2022_Rx" SG_ 506 Mc_PlayFrstTrInFldr_Rq 1;
BA_ "U_V713AV_MY2022_Rx" SG_ 506 Mc_PlayFrstTrInFldr_Rq 1;
BA_ "U_P708_MY2023_Rx" SG_ 506 Mc_PlayFrstTrInFldr_Rq 1;
BA_ "U_V710_MY2023_Rx" SG_ 506 Mc_PlayFrstTrInFldr_Rq 1;
BA_ "U_P702_MY2024_Tx" SG_ 506 Mc_PlayFrstTrInFldr_Rq 1;
BA_ "U_V713N_MY2022_Rx" SG_ 506 Mc_ItemIndex_Rq 1;
BA_ "U_V713AV_MY2022_Rx" SG_ 506 Mc_ItemIndex_Rq 1;
BA_ "U_P708_MY2023_Rx" SG_ 506 Mc_ItemIndex_Rq 1;
BA_ "U_V710_MY2023_Rx" SG_ 506 Mc_ItemIndex_Rq 1;
BA_ "U_P702_MY2024_Tx" SG_ 506 Mc_ItemIndex_Rq 1;
BA_ "U_V713N_MY2022_Rx" SG_ 506 Mc_FolderNumber3_Rq 1;
BA_ "U_V713AV_MY2022_Rx" SG_ 506 Mc_FolderNumber3_Rq 1;
BA_ "U_P708_MY2023_Rx" SG_ 506 Mc_FolderNumber3_Rq 1;
BA_ "U_V710_MY2023_Rx" SG_ 506 Mc_FolderNumber3_Rq 1;
BA_ "U_P702_MY2024_Tx" SG_ 506 Mc_FolderNumber3_Rq 1;
BA_ "GenSigSendType" SG_ 505 Mc_AudioSourceSel2_Rq 3;
BA_ "U_V713N_MY2022_Rx" SG_ 505 Mc_AudioSourceSel2_Rq 1;
BA_ "U_V713AV_MY2022_Rx" SG_ 505 Mc_AudioSourceSel2_Rq 1;
BA_ "U_P708_MY2023_Rx" SG_ 505 Mc_AudioSourceSel2_Rq 1;
BA_ "U_V710_MY2023_Rx" SG_ 505 Mc_AudioSourceSel2_Rq 1;
BA_ "U_P702_MY2024_Tx" SG_ 505 Mc_AudioSourceSel2_Rq 1;
BA_ "U_V713N_MY2022_Rx" SG_ 505 Mc_StartItemIndexRq 1;
BA_ "U_V713AV_MY2022_Rx" SG_ 505 Mc_StartItemIndexRq 1;
BA_ "U_P708_MY2023_Rx" SG_ 505 Mc_StartItemIndexRq 1;
BA_ "U_V710_MY2023_Rx" SG_ 505 Mc_StartItemIndexRq 1;
BA_ "U_P702_MY2024_Tx" SG_ 505 Mc_StartItemIndexRq 1;
BA_ "U_V713N_MY2022_Rx" SG_ 505 Mc_NbrOfItems2_Rq 1;
BA_ "U_V713AV_MY2022_Rx" SG_ 505 Mc_NbrOfItems2_Rq 1;
BA_ "U_P708_MY2023_Rx" SG_ 505 Mc_NbrOfItems2_Rq 1;
BA_ "U_V710_MY2023_Rx" SG_ 505 Mc_NbrOfItems2_Rq 1;
BA_ "U_P702_MY2024_Tx" SG_ 505 Mc_NbrOfItems2_Rq 1;
BA_ "U_V713N_MY2022_Rx" SG_ 505 Mc_ItemNameLength2_Rq 1;
BA_ "U_V713AV_MY2022_Rx" SG_ 505 Mc_ItemNameLength2_Rq 1;
BA_ "U_P708_MY2023_Rx" SG_ 505 Mc_ItemNameLength2_Rq 1;
BA_ "U_V710_MY2023_Rx" SG_ 505 Mc_ItemNameLength2_Rq 1;
BA_ "U_P702_MY2024_Tx" SG_ 505 Mc_ItemNameLength2_Rq 1;
BA_ "U_V713N_MY2022_Rx" SG_ 505 Mc_CutItem2_Rq 1;
BA_ "U_V713AV_MY2022_Rx" SG_ 505 Mc_CutItem2_Rq 1;
BA_ "U_P708_MY2023_Rx" SG_ 505 Mc_CutItem2_Rq 1;
BA_ "U_V710_MY2023_Rx" SG_ 505 Mc_CutItem2_Rq 1;
BA_ "U_P702_MY2024_Tx" SG_ 505 Mc_CutItem2_Rq 1;
BA_ "U_V713N_MY2022_Rx" SG_ 505 Mc_FolderNumber2_Rq 1;
BA_ "U_V713AV_MY2022_Rx" SG_ 505 Mc_FolderNumber2_Rq 1;
BA_ "U_P708_MY2023_Rx" SG_ 505 Mc_FolderNumber2_Rq 1;
BA_ "U_V710_MY2023_Rx" SG_ 505 Mc_FolderNumber2_Rq 1;
BA_ "U_P702_MY2024_Tx" SG_ 505 Mc_FolderNumber2_Rq 1;
BA_ "U_V713N_MY2022_Rx" SG_ 505 Mc_FolderContent_Rq 1;
BA_ "U_V713AV_MY2022_Rx" SG_ 505 Mc_FolderContent_Rq 1;
BA_ "U_P708_MY2023_Rx" SG_ 505 Mc_FolderContent_Rq 1;
BA_ "U_V710_MY2023_Rx" SG_ 505 Mc_FolderContent_Rq 1;
BA_ "U_P702_MY2024_Tx" SG_ 505 Mc_FolderContent_Rq 1;
BA_ "GenSigSendType" SG_ 403 McLangSel2_Rq 3;
BA_ "U_P708_MY2023_Rx" SG_ 403 McLangSel2_Rq 1;
BA_ "U_V713N_MY2022_Tx" SG_ 403 McLangSel2_Rq 1;
BA_ "U_V713AV_MY2022_Tx" SG_ 403 McLangSel2_Rq 1;
BA_ "U_P708_MY2023_Tx" SG_ 403 McLangSel2_Rq 1;
BA_ "U_V710_MY2023_Tx" SG_ 403 McLangSel2_Rq 1;
BA_ "GenSigSendType" SG_ 403 DealerCall_B_Rq 3;
BA_ "U_P708_MY2023_Rx" SG_ 403 DealerCall_B_Rq 1;
BA_ "U_V713N_MY2022_Tx" SG_ 403 DealerCall_B_Rq 1;
BA_ "U_V713AV_MY2022_Tx" SG_ 403 DealerCall_B_Rq 1;
BA_ "U_P708_MY2023_Tx" SG_ 403 DealerCall_B_Rq 1;
BA_ "GenSigSendType" SG_ 403 Mc_RepeatGuidance_Rq 3;
BA_ "U_P708_MY2023_Rx" SG_ 403 Mc_RepeatGuidance_Rq 1;
BA_ "U_V713N_MY2022_Tx" SG_ 403 Mc_RepeatGuidance_Rq 1;
BA_ "U_V713AV_MY2022_Tx" SG_ 403 Mc_RepeatGuidance_Rq 1;
BA_ "U_V710_MY2023_Tx" SG_ 403 Mc_RepeatGuidance_Rq 1;
BA_ "GenSigSendType" SG_ 403 Mc_CancelRoute_Rq 3;
BA_ "U_P708_MY2023_Rx" SG_ 403 Mc_CancelRoute_Rq 1;
BA_ "U_V713N_MY2022_Tx" SG_ 403 Mc_CancelRoute_Rq 1;
BA_ "U_V713AV_MY2022_Tx" SG_ 403 Mc_CancelRoute_Rq 1;
BA_ "U_V710_MY2023_Tx" SG_ 403 Mc_CancelRoute_Rq 1;
BA_ "GenSigSendType" SG_ 403 Mc_CancelCurrWaypt_Rq 3;
BA_ "U_P708_MY2023_Rx" SG_ 403 Mc_CancelCurrWaypt_Rq 1;
BA_ "U_V713N_MY2022_Tx" SG_ 403 Mc_CancelCurrWaypt_Rq 1;
BA_ "U_V713AV_MY2022_Tx" SG_ 403 Mc_CancelCurrWaypt_Rq 1;
BA_ "U_P708_MY2023_Tx" SG_ 403 Mc_CancelCurrWaypt_Rq 1;
BA_ "U_V710_MY2023_Tx" SG_ 403 Mc_CancelCurrWaypt_Rq 1;
BA_ "GenSigSendType" SG_ 403 Mc_TextMessage_Rq 3;
BA_ "U_P708_MY2023_Rx" SG_ 403 Mc_TextMessage_Rq 1;
BA_ "U_V713N_MY2022_Tx" SG_ 403 Mc_TextMessage_Rq 1;
BA_ "U_V713AV_MY2022_Tx" SG_ 403 Mc_TextMessage_Rq 1;
BA_ "U_V710_MY2023_Tx" SG_ 403 Mc_TextMessage_Rq 1;
BA_ "GenSigSendType" SG_ 403 Mc_BTInCallOptions_Rq 3;
BA_ "U_P708_MY2023_Rx" SG_ 403 Mc_BTInCallOptions_Rq 1;
BA_ "U_V713N_MY2022_Tx" SG_ 403 Mc_BTInCallOptions_Rq 1;
BA_ "U_V713AV_MY2022_Tx" SG_ 403 Mc_BTInCallOptions_Rq 1;
BA_ "U_P708_MY2023_Tx" SG_ 403 Mc_BTInCallOptions_Rq 1;
BA_ "U_V710_MY2023_Tx" SG_ 403 Mc_BTInCallOptions_Rq 1;
BA_ "GenSigSendType" SG_ 403 Mc_PhMicrophoneMute_Rq 3;
BA_ "U_P708_MY2023_Rx" SG_ 403 Mc_PhMicrophoneMute_Rq 1;
BA_ "U_V713N_MY2022_Tx" SG_ 403 Mc_PhMicrophoneMute_Rq 1;
BA_ "U_V713AV_MY2022_Tx" SG_ 403 Mc_PhMicrophoneMute_Rq 1;
BA_ "U_P708_MY2023_Tx" SG_ 403 Mc_PhMicrophoneMute_Rq 1;
BA_ "U_V710_MY2023_Tx" SG_ 403 Mc_PhMicrophoneMute_Rq 1;
BA_ "GenSigSendType" SG_ 403 Mc_LangSel_Rq 3;
BA_ "U_P708_MY2023_Rx" SG_ 403 Mc_LangSel_Rq 1;
BA_ "U_V713N_MY2022_Tx" SG_ 403 Mc_LangSel_Rq 1;
BA_ "U_V713AV_MY2022_Tx" SG_ 403 Mc_LangSel_Rq 1;
BA_ "U_P708_MY2023_Tx" SG_ 403 Mc_LangSel_Rq 1;
BA_ "U_V710_MY2023_Tx" SG_ 403 Mc_LangSel_Rq 1;
BA_ "WakeupSignal" SG_ 401 Bezel_Beeps_Rq 1;
BA_ "GenSigSendType" SG_ 401 Bezel_Beeps_Rq 3;
BA_ "U_V710_MY2023_Tx" SG_ 401 Bezel_Beeps_Rq 1;
BA_ "U_P708_MY2023_Tx" SG_ 401 Bezel_Beeps_Rq 1;
BA_ "U_P702_MY2024_Tx" SG_ 401 Bezel_Beeps_Rq 1;
BA_ "GenSigStartValue" SG_ 401 Disp_VehUntTripCoUsrSel 3;
BA_ "GenSigSendType" SG_ 401 Disp_VehUntTripCoUsrSel 3;
BA_ "U_V713N_MY2022_Rx" SG_ 401 Disp_VehUntTripCoUsrSel 1;
BA_ "U_V713AV_MY2022_Rx" SG_ 401 Disp_VehUntTripCoUsrSel 1;
BA_ "U_P708_MY2023_Rx" SG_ 401 Disp_VehUntTripCoUsrSel 1;
BA_ "U_V710_MY2023_Rx" SG_ 401 Disp_VehUntTripCoUsrSel 1;
BA_ "U_V710_MY2023_Tx" SG_ 401 Disp_VehUntTripCoUsrSel 1;
BA_ "U_P708_MY2023_Tx" SG_ 401 Disp_VehUntTripCoUsrSel 1;
BA_ "U_P702_MY2024_Tx" SG_ 401 Disp_VehUntTripCoUsrSel 1;
BA_ "GenSigStartValue" SG_ 401 Disp_VehUnitTempUsrSel 3;
BA_ "GenSigSendType" SG_ 401 Disp_VehUnitTempUsrSel 3;
BA_ "U_V713N_MY2022_Rx" SG_ 401 Disp_VehUnitTempUsrSel 1;
BA_ "U_V713AV_MY2022_Rx" SG_ 401 Disp_VehUnitTempUsrSel 1;
BA_ "U_P708_MY2023_Rx" SG_ 401 Disp_VehUnitTempUsrSel 1;
BA_ "U_V710_MY2023_Rx" SG_ 401 Disp_VehUnitTempUsrSel 1;
BA_ "U_V710_MY2023_Tx" SG_ 401 Disp_VehUnitTempUsrSel 1;
BA_ "U_P708_MY2023_Tx" SG_ 401 Disp_VehUnitTempUsrSel 1;
BA_ "GenSigSendType" SG_ 401 Disp_LangSel_Rq 3;
BA_ "U_V713N_MY2022_Rx" SG_ 401 Disp_LangSel_Rq 1;
BA_ "U_V713AV_MY2022_Rx" SG_ 401 Disp_LangSel_Rq 1;
BA_ "U_P708_MY2023_Rx" SG_ 401 Disp_LangSel_Rq 1;
BA_ "U_V710_MY2023_Rx" SG_ 401 Disp_LangSel_Rq 1;
BA_ "U_V710_MY2023_Tx" SG_ 401 Disp_LangSel_Rq 1;
BA_ "U_P708_MY2023_Tx" SG_ 401 Disp_LangSel_Rq 1;
BA_ "GenSigSendType" SG_ 401 Disp_LangSel2_Rq 3;
BA_ "U_V713N_MY2022_Rx" SG_ 401 Disp_LangSel2_Rq 1;
BA_ "U_V713AV_MY2022_Rx" SG_ 401 Disp_LangSel2_Rq 1;
BA_ "U_P708_MY2023_Rx" SG_ 401 Disp_LangSel2_Rq 1;
BA_ "U_V710_MY2023_Rx" SG_ 401 Disp_LangSel2_Rq 1;
BA_ "U_V710_MY2023_Tx" SG_ 401 Disp_LangSel2_Rq 1;
BA_ "U_P708_MY2023_Tx" SG_ 401 Disp_LangSel2_Rq 1;
BA_ "U_V713N_MY2022_Rx" SG_ 1143 EffAvgChrg_Pc_Dsply 1;
BA_ "U_V713AV_MY2022_Rx" SG_ 1143 EffAvgChrg_Pc_Dsply 1;
BA_ "U_P708_MY2023_Rx" SG_ 1143 EffAvgChrg_Pc_Dsply 1;
BA_ "U_V710_MY2023_Rx" SG_ 1143 EffAvgChrg_Pc_Dsply 1;
BA_ "U_P702_MY2024_Rx" SG_ 1143 EffAvgChrg_Pc_Dsply 1;
BA_ "U_V710_MY2023_Rx" SG_ 1143 ConsTipUnitPt_D_Dsply 1;
BA_ "U_P708_MY2023_Rx" SG_ 1143 ConsTipUnitPt_D_Dsply 1;
BA_ "U_P702_MY2024_Rx" SG_ 1143 ConsTipUnitPt_D_Dsply 1;
BA_ "GenSigStartValue" SG_ 1143 ConsTipTot_Pc_Dsply 1022;
BA_ "U_P702_MY2024_Rx" SG_ 1143 ConsTipTot_Pc_Dsply 1;
BA_ "U_V710_MY2023_Rx" SG_ 1143 ChrgCompltMsgTxt_D_Rq 1;
BA_ "U_P708_MY2023_Rx" SG_ 1143 ChrgCompltMsgTxt_D_Rq 1;
BA_ "U_P702_MY2024_Rx" SG_ 1143 ChrgCompltMsgTxt_D_Rq 1;
BA_ "U_V710_MY2023_Rx" SG_ 1142 ConsTipV_No_Dsply 1;
BA_ "U_P708_MY2023_Rx" SG_ 1142 ConsTipV_No_Dsply 1;
BA_ "U_P702_MY2024_Rx" SG_ 1142 ConsTipV_No_Dsply 1;
BA_ "U_V710_MY2023_Rx" SG_ 1142 ConsTipMsg3_D_Dsply 1;
BA_ "U_P708_MY2023_Rx" SG_ 1142 ConsTipMsg3_D_Dsply 1;
BA_ "U_P702_MY2024_Rx" SG_ 1142 ConsTipMsg3_D_Dsply 1;
BA_ "U_V710_MY2023_Rx" SG_ 1142 ConsTipMsg2_D_Dsply 1;
BA_ "U_P708_MY2023_Rx" SG_ 1142 ConsTipMsg2_D_Dsply 1;
BA_ "U_P702_MY2024_Rx" SG_ 1142 ConsTipMsg2_D_Dsply 1;
BA_ "U_V710_MY2023_Rx" SG_ 1142 ConsTipMsg1_D_Dsply 1;
BA_ "U_P708_MY2023_Rx" SG_ 1142 ConsTipMsg1_D_Dsply 1;
BA_ "U_P702_MY2024_Rx" SG_ 1142 ConsTipMsg1_D_Dsply 1;
BA_ "U_V710_MY2023_Rx" SG_ 1142 ConsTipDecel_No_Dsply 1;
BA_ "U_P708_MY2023_Rx" SG_ 1142 ConsTipDecel_No_Dsply 1;
BA_ "U_P702_MY2024_Rx" SG_ 1142 ConsTipDecel_No_Dsply 1;
BA_ "U_V710_MY2023_Rx" SG_ 1142 ConsTipA_No_Dsply 1;
BA_ "U_P708_MY2023_Rx" SG_ 1142 ConsTipA_No_Dsply 1;
BA_ "U_P702_MY2024_Rx" SG_ 1142 ConsTipA_No_Dsply 1;
BA_ "U_V710_MY2023_Rx" SG_ 973 PersCtaSplitView_D_Stat 1;
BA_ "U_P708_MY2023_Rx" SG_ 973 PersCtaSplitView_D_Stat 1;
BA_ "U_P702_MY2024_Rx" SG_ 973 PersCtaSplitView_D_Stat 1;
BA_ "U_V713N_MY2022_Rx" SG_ 973 LaSysOffStat_D_Dsply 1;
BA_ "U_V713AV_MY2022_Rx" SG_ 973 LaSysOffStat_D_Dsply 1;
BA_ "U_P708_MY2023_Rx" SG_ 973 LaSysOffStat_D_Dsply 1;
BA_ "U_V710_MY2023_Rx" SG_ 973 LaSysOffStat_D_Dsply 1;
BA_ "U_P702_MY2024_Rx" SG_ 973 LaSysOffStat_D_Dsply 1;
BA_ "GenSigStartValue" SG_ 973 TsrVl1RstrcMsgTxt2_D_Rq 1;
BA_ "U_V713N_MY2022_Rx" SG_ 973 TsrVl1RstrcMsgTxt2_D_Rq 1;
BA_ "U_V713AV_MY2022_Rx" SG_ 973 TsrVl1RstrcMsgTxt2_D_Rq 1;
BA_ "U_P708_MY2023_Rx" SG_ 973 TsrVl1RstrcMsgTxt2_D_Rq 1;
BA_ "U_V710_MY2023_Rx" SG_ 973 TsrVl1RstrcMsgTxt2_D_Rq 1;
BA_ "U_P702_MY2024_Rx" SG_ 973 TsrVl1RstrcMsgTxt2_D_Rq 1;
BA_ "GenSigStartValue" SG_ 973 TsrVl2RstrcMsgTxt2_D_Rq 1;
BA_ "U_V713N_MY2022_Rx" SG_ 973 TsrVl2RstrcMsgTxt2_D_Rq 1;
BA_ "U_V713AV_MY2022_Rx" SG_ 973 TsrVl2RstrcMsgTxt2_D_Rq 1;
BA_ "U_P708_MY2023_Rx" SG_ 973 TsrVl2RstrcMsgTxt2_D_Rq 1;
BA_ "U_V710_MY2023_Rx" SG_ 973 TsrVl2RstrcMsgTxt2_D_Rq 1;
BA_ "U_P702_MY2024_Rx" SG_ 973 TsrVl2RstrcMsgTxt2_D_Rq 1;
BA_ "U_V713N_MY2022_Rx" SG_ 973 TsrVl2PrmntMsgTxt_D_Rq 1;
BA_ "U_V713AV_MY2022_Rx" SG_ 973 TsrVl2PrmntMsgTxt_D_Rq 1;
BA_ "U_P708_MY2023_Rx" SG_ 973 TsrVl2PrmntMsgTxt_D_Rq 1;
BA_ "U_V710_MY2023_Rx" SG_ 973 TsrVl2PrmntMsgTxt_D_Rq 1;
BA_ "U_P702_MY2024_Rx" SG_ 973 TsrVl2PrmntMsgTxt_D_Rq 1;
BA_ "U_V713N_MY2022_Rx" SG_ 973 TsrVl1PrmntMsgTxt_D_Rq 1;
BA_ "U_V713AV_MY2022_Rx" SG_ 973 TsrVl1PrmntMsgTxt_D_Rq 1;
BA_ "U_P708_MY2023_Rx" SG_ 973 TsrVl1PrmntMsgTxt_D_Rq 1;
BA_ "U_V710_MY2023_Rx" SG_ 973 TsrVl1PrmntMsgTxt_D_Rq 1;
BA_ "U_P702_MY2024_Rx" SG_ 973 TsrVl1PrmntMsgTxt_D_Rq 1;
BA_ "U_V713N_MY2022_Rx" SG_ 973 TsrOvtkMsgTxt2_D_Rq 1;
BA_ "U_V713AV_MY2022_Rx" SG_ 973 TsrOvtkMsgTxt2_D_Rq 1;
BA_ "U_P708_MY2023_Rx" SG_ 973 TsrOvtkMsgTxt2_D_Rq 1;
BA_ "U_V710_MY2023_Rx" SG_ 973 TsrOvtkMsgTxt2_D_Rq 1;
BA_ "U_P702_MY2024_Rx" SG_ 973 TsrOvtkMsgTxt2_D_Rq 1;
BA_ "U_V713N_MY2022_Rx" SG_ 973 WwaWarn_B_Rq 1;
BA_ "U_V713AV_MY2022_Rx" SG_ 973 WwaWarn_B_Rq 1;
BA_ "U_V710_MY2023_Rx" SG_ 973 WwaWarn_B_Rq 1;
BA_ "U_P708_MY2023_Rx" SG_ 973 WwaWarn_B_Rq 1;
BA_ "U_P702_MY2024_Rx" SG_ 973 WwaWarn_B_Rq 1;
BA_ "U_P702_MY2024_Rx" SG_ 973 RoadSignRgltry_D_Dsply 1;
BA_ "GenSigStartValue" SG_ 973 TsrVlUnitMsgTxt_D_Rq 2;
BA_ "U_V713N_MY2022_Rx" SG_ 973 TsrVlUnitMsgTxt_D_Rq 1;
BA_ "U_V713AV_MY2022_Rx" SG_ 973 TsrVlUnitMsgTxt_D_Rq 1;
BA_ "U_P708_MY2023_Rx" SG_ 973 TsrVlUnitMsgTxt_D_Rq 1;
BA_ "U_V710_MY2023_Rx" SG_ 973 TsrVlUnitMsgTxt_D_Rq 1;
BA_ "U_P702_MY2024_Rx" SG_ 973 TsrVlUnitMsgTxt_D_Rq 1;
BA_ "GenSigStartValue" SG_ 973 TsrVLim2MsgTxt_D_Rq 255;
BA_ "U_V713N_MY2022_Rx" SG_ 973 TsrVLim2MsgTxt_D_Rq 1;
BA_ "U_V713AV_MY2022_Rx" SG_ 973 TsrVLim2MsgTxt_D_Rq 1;
BA_ "U_P708_MY2023_Rx" SG_ 973 TsrVLim2MsgTxt_D_Rq 1;
BA_ "U_V710_MY2023_Rx" SG_ 973 TsrVLim2MsgTxt_D_Rq 1;
BA_ "U_P702_MY2024_Rx" SG_ 973 TsrVLim2MsgTxt_D_Rq 1;
BA_ "GenSigStartValue" SG_ 973 TsrVLim1MsgTxt_D_Rq 255;
BA_ "U_V713N_MY2022_Rx" SG_ 973 TsrVLim1MsgTxt_D_Rq 1;
BA_ "U_V713AV_MY2022_Rx" SG_ 973 TsrVLim1MsgTxt_D_Rq 1;
BA_ "U_P708_MY2023_Rx" SG_ 973 TsrVLim1MsgTxt_D_Rq 1;
BA_ "U_V710_MY2023_Rx" SG_ 973 TsrVLim1MsgTxt_D_Rq 1;
BA_ "U_P702_MY2024_Rx" SG_ 973 TsrVLim1MsgTxt_D_Rq 1;
BA_ "U_V713N_MY2022_Rx" SG_ 973 TsrVl2StatMsgTxt_D_Rq 1;
BA_ "U_V713AV_MY2022_Rx" SG_ 973 TsrVl2StatMsgTxt_D_Rq 1;
BA_ "U_P708_MY2023_Rx" SG_ 973 TsrVl2StatMsgTxt_D_Rq 1;
BA_ "U_V710_MY2023_Rx" SG_ 973 TsrVl2StatMsgTxt_D_Rq 1;
BA_ "U_P702_MY2024_Rx" SG_ 973 TsrVl2StatMsgTxt_D_Rq 1;
BA_ "U_V713N_MY2022_Rx" SG_ 973 TsrVl2RstrcMsgTxt_D_Rq 1;
BA_ "U_V713AV_MY2022_Rx" SG_ 973 TsrVl2RstrcMsgTxt_D_Rq 1;
BA_ "U_P708_MY2023_Rx" SG_ 973 TsrVl2RstrcMsgTxt_D_Rq 1;
BA_ "U_V710_MY2023_Rx" SG_ 973 TsrVl2RstrcMsgTxt_D_Rq 1;
BA_ "U_P702_MY2024_Rx" SG_ 973 TsrVl2RstrcMsgTxt_D_Rq 1;
BA_ "U_V713N_MY2022_Rx" SG_ 973 TsrVl1StatMsgTxt_D_Rq 1;
BA_ "U_V713AV_MY2022_Rx" SG_ 973 TsrVl1StatMsgTxt_D_Rq 1;
BA_ "U_P708_MY2023_Rx" SG_ 973 TsrVl1StatMsgTxt_D_Rq 1;
BA_ "U_V710_MY2023_Rx" SG_ 973 TsrVl1StatMsgTxt_D_Rq 1;
BA_ "U_P702_MY2024_Rx" SG_ 973 TsrVl1StatMsgTxt_D_Rq 1;
BA_ "U_V713N_MY2022_Rx" SG_ 973 TsrVl1RstrcMsgTxt_D_Rq 1;
BA_ "U_V713AV_MY2022_Rx" SG_ 973 TsrVl1RstrcMsgTxt_D_Rq 1;
BA_ "U_P708_MY2023_Rx" SG_ 973 TsrVl1RstrcMsgTxt_D_Rq 1;
BA_ "U_V710_MY2023_Rx" SG_ 973 TsrVl1RstrcMsgTxt_D_Rq 1;
BA_ "U_P702_MY2024_Rx" SG_ 973 TsrVl1RstrcMsgTxt_D_Rq 1;
BA_ "U_V713N_MY2022_Rx" SG_ 973 TsrStatMsgTxt_D_Rq 1;
BA_ "U_V713AV_MY2022_Rx" SG_ 973 TsrStatMsgTxt_D_Rq 1;
BA_ "U_P708_MY2023_Rx" SG_ 973 TsrStatMsgTxt_D_Rq 1;
BA_ "U_V710_MY2023_Rx" SG_ 973 TsrStatMsgTxt_D_Rq 1;
BA_ "U_P702_MY2024_Rx" SG_ 973 TsrStatMsgTxt_D_Rq 1;
BA_ "U_V713N_MY2022_Rx" SG_ 973 TsrOvtkStatMsgTxt_D_Rq 1;
BA_ "U_V713AV_MY2022_Rx" SG_ 973 TsrOvtkStatMsgTxt_D_Rq 1;
BA_ "U_P708_MY2023_Rx" SG_ 973 TsrOvtkStatMsgTxt_D_Rq 1;
BA_ "U_V710_MY2023_Rx" SG_ 973 TsrOvtkStatMsgTxt_D_Rq 1;
BA_ "U_P702_MY2024_Rx" SG_ 973 TsrOvtkStatMsgTxt_D_Rq 1;
BA_ "GenSigStartValue" SG_ 973 TsrOvtkMsgTxt_D_Rq 1;
BA_ "U_V713N_MY2022_Rx" SG_ 973 TsrOvtkMsgTxt_D_Rq 1;
BA_ "U_V713AV_MY2022_Rx" SG_ 973 TsrOvtkMsgTxt_D_Rq 1;
BA_ "U_P708_MY2023_Rx" SG_ 973 TsrOvtkMsgTxt_D_Rq 1;
BA_ "U_V710_MY2023_Rx" SG_ 973 TsrOvtkMsgTxt_D_Rq 1;
BA_ "U_P702_MY2024_Rx" SG_ 973 TsrOvtkMsgTxt_D_Rq 1;
BA_ "GenSigStartValue" SG_ 973 TsrOswWarnMsgTxt_D_Rq 1;
BA_ "U_V713N_MY2022_Rx" SG_ 973 TsrOswWarnMsgTxt_D_Rq 1;
BA_ "U_V713AV_MY2022_Rx" SG_ 973 TsrOswWarnMsgTxt_D_Rq 1;
BA_ "U_P708_MY2023_Rx" SG_ 973 TsrOswWarnMsgTxt_D_Rq 1;
BA_ "U_V710_MY2023_Rx" SG_ 973 TsrOswWarnMsgTxt_D_Rq 1;
BA_ "U_P702_MY2024_Rx" SG_ 973 TsrOswWarnMsgTxt_D_Rq 1;
BA_ "GenSigStartValue" SG_ 973 TsrMsgTxt_D_Rq 1;
BA_ "U_V713N_MY2022_Rx" SG_ 973 TsrMsgTxt_D_Rq 1;
BA_ "U_V713AV_MY2022_Rx" SG_ 973 TsrMsgTxt_D_Rq 1;
BA_ "U_P708_MY2023_Rx" SG_ 973 TsrMsgTxt_D_Rq 1;
BA_ "U_V710_MY2023_Rx" SG_ 973 TsrMsgTxt_D_Rq 1;
BA_ "U_P702_MY2024_Rx" SG_ 973 TsrMsgTxt_D_Rq 1;
BA_ "GenSigSendType" SG_ 405 LBC1_StartItemInd 3;
BA_ "U_V713N_MY2022_Rx" SG_ 405 LBC1_StartItemInd 1;
BA_ "U_V713AV_MY2022_Rx" SG_ 405 LBC1_StartItemInd 1;
BA_ "U_P708_MY2023_Rx" SG_ 405 LBC1_StartItemInd 1;
BA_ "U_V710_MY2023_Rx" SG_ 405 LBC1_StartItemInd 1;
BA_ "U_V713N_MY2022_Tx" SG_ 405 LBC1_StartItemInd 1;
BA_ "U_V713AV_MY2022_Tx" SG_ 405 LBC1_StartItemInd 1;
BA_ "U_P708_MY2023_Tx" SG_ 405 LBC1_StartItemInd 1;
BA_ "U_V710_MY2023_Tx" SG_ 405 LBC1_StartItemInd 1;
BA_ "U_P702_MY2024_Tx" SG_ 405 LBC1_StartItemInd 1;
BA_ "GenSigSendType" SG_ 405 LBC1_SetListServ 3;
BA_ "U_V713N_MY2022_Rx" SG_ 405 LBC1_SetListServ 1;
BA_ "U_V713AV_MY2022_Rx" SG_ 405 LBC1_SetListServ 1;
BA_ "U_P708_MY2023_Rx" SG_ 405 LBC1_SetListServ 1;
BA_ "U_V710_MY2023_Rx" SG_ 405 LBC1_SetListServ 1;
BA_ "U_V713N_MY2022_Tx" SG_ 405 LBC1_SetListServ 1;
BA_ "U_V713AV_MY2022_Tx" SG_ 405 LBC1_SetListServ 1;
BA_ "U_P708_MY2023_Tx" SG_ 405 LBC1_SetListServ 1;
BA_ "U_V710_MY2023_Tx" SG_ 405 LBC1_SetListServ 1;
BA_ "U_P702_MY2024_Tx" SG_ 405 LBC1_SetListServ 1;
BA_ "GenSigSendType" SG_ 405 LBC1_Opcode 3;
BA_ "U_V713N_MY2022_Rx" SG_ 405 LBC1_Opcode 1;
BA_ "U_V713AV_MY2022_Rx" SG_ 405 LBC1_Opcode 1;
BA_ "U_P708_MY2023_Rx" SG_ 405 LBC1_Opcode 1;
BA_ "U_V710_MY2023_Rx" SG_ 405 LBC1_Opcode 1;
BA_ "U_V713N_MY2022_Tx" SG_ 405 LBC1_Opcode 1;
BA_ "U_V713AV_MY2022_Tx" SG_ 405 LBC1_Opcode 1;
BA_ "U_P708_MY2023_Tx" SG_ 405 LBC1_Opcode 1;
BA_ "U_V710_MY2023_Tx" SG_ 405 LBC1_Opcode 1;
BA_ "U_P702_MY2024_Tx" SG_ 405 LBC1_Opcode 1;
BA_ "GenSigSendType" SG_ 405 LBC1_NbrOfItems 3;
BA_ "U_V713N_MY2022_Rx" SG_ 405 LBC1_NbrOfItems 1;
BA_ "U_V713AV_MY2022_Rx" SG_ 405 LBC1_NbrOfItems 1;
BA_ "U_P708_MY2023_Rx" SG_ 405 LBC1_NbrOfItems 1;
BA_ "U_V710_MY2023_Rx" SG_ 405 LBC1_NbrOfItems 1;
BA_ "U_V713N_MY2022_Tx" SG_ 405 LBC1_NbrOfItems 1;
BA_ "U_V713AV_MY2022_Tx" SG_ 405 LBC1_NbrOfItems 1;
BA_ "U_P708_MY2023_Tx" SG_ 405 LBC1_NbrOfItems 1;
BA_ "U_V710_MY2023_Tx" SG_ 405 LBC1_NbrOfItems 1;
BA_ "U_P702_MY2024_Tx" SG_ 405 LBC1_NbrOfItems 1;
BA_ "GenSigSendType" SG_ 405 LBC1_ItemIndex 3;
BA_ "U_V713N_MY2022_Rx" SG_ 405 LBC1_ItemIndex 1;
BA_ "U_V713AV_MY2022_Rx" SG_ 405 LBC1_ItemIndex 1;
BA_ "U_P708_MY2023_Rx" SG_ 405 LBC1_ItemIndex 1;
BA_ "U_V710_MY2023_Rx" SG_ 405 LBC1_ItemIndex 1;
BA_ "U_V713N_MY2022_Tx" SG_ 405 LBC1_ItemIndex 1;
BA_ "U_V713AV_MY2022_Tx" SG_ 405 LBC1_ItemIndex 1;
BA_ "U_P708_MY2023_Tx" SG_ 405 LBC1_ItemIndex 1;
BA_ "U_V710_MY2023_Tx" SG_ 405 LBC1_ItemIndex 1;
BA_ "U_P702_MY2024_Tx" SG_ 405 LBC1_ItemIndex 1;
BA_ "GenSigSendType" SG_ 405 LBC1_ActiveListID 3;
BA_ "U_V713N_MY2022_Rx" SG_ 405 LBC1_ActiveListID 1;
BA_ "U_V713AV_MY2022_Rx" SG_ 405 LBC1_ActiveListID 1;
BA_ "U_P708_MY2023_Rx" SG_ 405 LBC1_ActiveListID 1;
BA_ "U_V710_MY2023_Rx" SG_ 405 LBC1_ActiveListID 1;
BA_ "U_V713N_MY2022_Tx" SG_ 405 LBC1_ActiveListID 1;
BA_ "U_V713AV_MY2022_Tx" SG_ 405 LBC1_ActiveListID 1;
BA_ "U_P708_MY2023_Tx" SG_ 405 LBC1_ActiveListID 1;
BA_ "U_V710_MY2023_Tx" SG_ 405 LBC1_ActiveListID 1;
BA_ "U_P702_MY2024_Tx" SG_ 405 LBC1_ActiveListID 1;
BA_ "GenSigSendType" SG_ 756 AdjustableChimeVol2_Rq 3;
BA_ "U_V713N_MY2022_Rx" SG_ 756 AdjustableChimeVol2_Rq 1;
BA_ "U_V713AV_MY2022_Rx" SG_ 756 AdjustableChimeVol2_Rq 1;
BA_ "U_P708_MY2023_Rx" SG_ 756 AdjustableChimeVol2_Rq 1;
BA_ "U_V710_MY2023_Rx" SG_ 756 AdjustableChimeVol2_Rq 1;
BA_ "ECGUsedRxSignal" SG_ 756 AdjustableChimeVol2_Rq 1;
BA_ "U_CDX74X_MY2024_Rx" SG_ 756 AdjustableChimeVol2_Rq 1;
BA_ "U_V713N_MY2022_Tx" SG_ 756 AdjustableChimeVol2_Rq 1;
BA_ "U_V713AV_MY2022_Tx" SG_ 756 AdjustableChimeVol2_Rq 1;
BA_ "U_P708_MY2023_Tx" SG_ 756 AdjustableChimeVol2_Rq 1;
BA_ "U_V710_MY2023_Tx" SG_ 756 AdjustableChimeVol2_Rq 1;
BA_ "U_P702_MY2024_Tx" SG_ 756 AdjustableChimeVol2_Rq 1;
BA_ "U_V713N_MY2022_Rx" SG_ 756 Off_Time_Btwn_Chime2 1;
BA_ "U_V713AV_MY2022_Rx" SG_ 756 Off_Time_Btwn_Chime2 1;
BA_ "U_P708_MY2023_Rx" SG_ 756 Off_Time_Btwn_Chime2 1;
BA_ "U_V710_MY2023_Rx" SG_ 756 Off_Time_Btwn_Chime2 1;
BA_ "U_V713N_MY2022_Tx" SG_ 756 Off_Time_Btwn_Chime2 1;
BA_ "U_V713AV_MY2022_Tx" SG_ 756 Off_Time_Btwn_Chime2 1;
BA_ "U_P708_MY2023_Tx" SG_ 756 Off_Time_Btwn_Chime2 1;
BA_ "U_V710_MY2023_Tx" SG_ 756 Off_Time_Btwn_Chime2 1;
BA_ "U_P702_MY2024_Tx" SG_ 756 Off_Time_Btwn_Chime2 1;
BA_ "U_V713N_MY2022_Rx" SG_ 756 Chime_Vol_Level2 1;
BA_ "U_V713AV_MY2022_Rx" SG_ 756 Chime_Vol_Level2 1;
BA_ "U_P708_MY2023_Rx" SG_ 756 Chime_Vol_Level2 1;
BA_ "U_V710_MY2023_Rx" SG_ 756 Chime_Vol_Level2 1;
BA_ "U_CDX74X_MY2024_Rx" SG_ 756 Chime_Vol_Level2 1;
BA_ "U_V713N_MY2022_Tx" SG_ 756 Chime_Vol_Level2 1;
BA_ "U_V713AV_MY2022_Tx" SG_ 756 Chime_Vol_Level2 1;
BA_ "U_P708_MY2023_Tx" SG_ 756 Chime_Vol_Level2 1;
BA_ "U_V710_MY2023_Tx" SG_ 756 Chime_Vol_Level2 1;
BA_ "U_P702_MY2024_Tx" SG_ 756 Chime_Vol_Level2 1;
BA_ "GenSigSendType" SG_ 756 Chime_Time_Criticality2 3;
BA_ "U_V713N_MY2022_Rx" SG_ 756 Chime_Time_Criticality2 1;
BA_ "U_V713AV_MY2022_Rx" SG_ 756 Chime_Time_Criticality2 1;
BA_ "U_P708_MY2023_Rx" SG_ 756 Chime_Time_Criticality2 1;
BA_ "U_V710_MY2023_Rx" SG_ 756 Chime_Time_Criticality2 1;
BA_ "U_CDX74X_MY2024_Rx" SG_ 756 Chime_Time_Criticality2 1;
BA_ "ECGUsedRxSignal" SG_ 756 Chime_Time_Criticality2 1;
BA_ "U_V713N_MY2022_Tx" SG_ 756 Chime_Time_Criticality2 1;
BA_ "U_V713AV_MY2022_Tx" SG_ 756 Chime_Time_Criticality2 1;
BA_ "U_P708_MY2023_Tx" SG_ 756 Chime_Time_Criticality2 1;
BA_ "U_V710_MY2023_Tx" SG_ 756 Chime_Time_Criticality2 1;
BA_ "U_P702_MY2024_Tx" SG_ 756 Chime_Time_Criticality2 1;
BA_ "GenSigSendType" SG_ 756 Chime_Occurence2 3;
BA_ "U_V713N_MY2022_Rx" SG_ 756 Chime_Occurence2 1;
BA_ "U_V713AV_MY2022_Rx" SG_ 756 Chime_Occurence2 1;
BA_ "U_P708_MY2023_Rx" SG_ 756 Chime_Occurence2 1;
BA_ "U_V710_MY2023_Rx" SG_ 756 Chime_Occurence2 1;
BA_ "U_CDX74X_MY2024_Rx" SG_ 756 Chime_Occurence2 1;
BA_ "U_V713N_MY2022_Tx" SG_ 756 Chime_Occurence2 1;
BA_ "U_V713AV_MY2022_Tx" SG_ 756 Chime_Occurence2 1;
BA_ "U_P708_MY2023_Tx" SG_ 756 Chime_Occurence2 1;
BA_ "U_V710_MY2023_Tx" SG_ 756 Chime_Occurence2 1;
BA_ "U_P702_MY2024_Tx" SG_ 756 Chime_Occurence2 1;
BA_ "GenSigSendType" SG_ 756 Chime_Directionality2 3;
BA_ "U_V713N_MY2022_Rx" SG_ 756 Chime_Directionality2 1;
BA_ "U_V713AV_MY2022_Rx" SG_ 756 Chime_Directionality2 1;
BA_ "U_P708_MY2023_Rx" SG_ 756 Chime_Directionality2 1;
BA_ "U_V710_MY2023_Rx" SG_ 756 Chime_Directionality2 1;
BA_ "U_CDX74X_MY2024_Rx" SG_ 756 Chime_Directionality2 1;
BA_ "ECGUsedRxSignal" SG_ 756 Chime_Directionality2 1;
BA_ "U_V713N_MY2022_Tx" SG_ 756 Chime_Directionality2 1;
BA_ "U_V713AV_MY2022_Tx" SG_ 756 Chime_Directionality2 1;
BA_ "U_P708_MY2023_Tx" SG_ 756 Chime_Directionality2 1;
BA_ "U_V710_MY2023_Tx" SG_ 756 Chime_Directionality2 1;
BA_ "U_P702_MY2024_Tx" SG_ 756 Chime_Directionality2 1;
BA_ "U_V713N_MY2022_Rx" SG_ 756 Chime2 1;
BA_ "U_V713AV_MY2022_Rx" SG_ 756 Chime2 1;
BA_ "U_P708_MY2023_Rx" SG_ 756 Chime2 1;
BA_ "U_V710_MY2023_Rx" SG_ 756 Chime2 1;
BA_ "U_CDX74X_MY2024_Rx" SG_ 756 Chime2 1;
BA_ "U_V713N_MY2022_Tx" SG_ 756 Chime2 1;
BA_ "U_V713AV_MY2022_Tx" SG_ 756 Chime2 1;
BA_ "U_P708_MY2023_Tx" SG_ 756 Chime2 1;
BA_ "U_V710_MY2023_Tx" SG_ 756 Chime2 1;
BA_ "U_P702_MY2024_Tx" SG_ 756 Chime2 1;
BA_ "GenSigSendType" SG_ 756 Chime2Id_No_Rq 3;
BA_ "U_V713N_MY2022_Rx" SG_ 756 Chime2Id_No_Rq 1;
BA_ "U_V713AV_MY2022_Rx" SG_ 756 Chime2Id_No_Rq 1;
BA_ "U_P708_MY2023_Rx" SG_ 756 Chime2Id_No_Rq 1;
BA_ "U_V710_MY2023_Rx" SG_ 756 Chime2Id_No_Rq 1;
BA_ "U_V713N_MY2022_Tx" SG_ 756 Chime2Id_No_Rq 1;
BA_ "U_V713AV_MY2022_Tx" SG_ 756 Chime2Id_No_Rq 1;
BA_ "U_P708_MY2023_Tx" SG_ 756 Chime2Id_No_Rq 1;
BA_ "U_V710_MY2023_Tx" SG_ 756 Chime2Id_No_Rq 1;
BA_ "U_P702_MY2024_Tx" SG_ 756 Chime2Id_No_Rq 1;
BA_ "GenSigSendType" SG_ 544 ChimeId_No_Rq 3;
BA_ "U_V713N_MY2022_Rx" SG_ 544 ChimeId_No_Rq 1;
BA_ "U_V713AV_MY2022_Rx" SG_ 544 ChimeId_No_Rq 1;
BA_ "U_P708_MY2023_Rx" SG_ 544 ChimeId_No_Rq 1;
BA_ "U_V710_MY2023_Rx" SG_ 544 ChimeId_No_Rq 1;
BA_ "U_V713N_MY2022_Tx" SG_ 544 ChimeId_No_Rq 1;
BA_ "U_V713AV_MY2022_Tx" SG_ 544 ChimeId_No_Rq 1;
BA_ "U_V710_MY2023_Tx" SG_ 544 ChimeId_No_Rq 1;
BA_ "U_P708_MY2023_Tx" SG_ 544 ChimeId_No_Rq 1;
BA_ "U_P702_MY2024_Tx" SG_ 544 ChimeId_No_Rq 1;
BA_ "GenSigSendType" SG_ 544 AdjustableChimeVol_Rq 3;
BA_ "U_V713N_MY2022_Rx" SG_ 544 AdjustableChimeVol_Rq 1;
BA_ "U_V713AV_MY2022_Rx" SG_ 544 AdjustableChimeVol_Rq 1;
BA_ "U_P708_MY2023_Rx" SG_ 544 AdjustableChimeVol_Rq 1;
BA_ "U_V710_MY2023_Rx" SG_ 544 AdjustableChimeVol_Rq 1;
BA_ "ECGUsedRxSignal" SG_ 544 AdjustableChimeVol_Rq 1;
BA_ "U_CDX74X_MY2024_Rx" SG_ 544 AdjustableChimeVol_Rq 1;
BA_ "U_V713N_MY2022_Tx" SG_ 544 AdjustableChimeVol_Rq 1;
BA_ "U_V713AV_MY2022_Tx" SG_ 544 AdjustableChimeVol_Rq 1;
BA_ "U_P708_MY2023_Tx" SG_ 544 AdjustableChimeVol_Rq 1;
BA_ "U_V710_MY2023_Tx" SG_ 544 AdjustableChimeVol_Rq 1;
BA_ "U_P702_MY2024_Tx" SG_ 544 AdjustableChimeVol_Rq 1;
BA_ "GenSigSendType" SG_ 544 Chime_Occurence 3;
BA_ "U_V713N_MY2022_Rx" SG_ 544 Chime_Occurence 1;
BA_ "U_V713AV_MY2022_Rx" SG_ 544 Chime_Occurence 1;
BA_ "U_P708_MY2023_Rx" SG_ 544 Chime_Occurence 1;
BA_ "U_V710_MY2023_Rx" SG_ 544 Chime_Occurence 1;
BA_ "U_CDX74X_MY2024_Rx" SG_ 544 Chime_Occurence 1;
BA_ "ECGUsedRxSignal" SG_ 544 Chime_Occurence 1;
BA_ "U_V713N_MY2022_Tx" SG_ 544 Chime_Occurence 1;
BA_ "U_V713AV_MY2022_Tx" SG_ 544 Chime_Occurence 1;
BA_ "U_P708_MY2023_Tx" SG_ 544 Chime_Occurence 1;
BA_ "U_V710_MY2023_Tx" SG_ 544 Chime_Occurence 1;
BA_ "U_P702_MY2024_Tx" SG_ 544 Chime_Occurence 1;
BA_ "U_V713N_MY2022_Rx" SG_ 544 Off_Time_Btwn_Chime 1;
BA_ "U_V713AV_MY2022_Rx" SG_ 544 Off_Time_Btwn_Chime 1;
BA_ "U_P708_MY2023_Rx" SG_ 544 Off_Time_Btwn_Chime 1;
BA_ "U_V710_MY2023_Rx" SG_ 544 Off_Time_Btwn_Chime 1;
BA_ "U_CDX74X_MY2024_Rx" SG_ 544 Off_Time_Btwn_Chime 1;
BA_ "ECGUsedRxSignal" SG_ 544 Off_Time_Btwn_Chime 1;
BA_ "U_V713N_MY2022_Tx" SG_ 544 Off_Time_Btwn_Chime 1;
BA_ "U_V713AV_MY2022_Tx" SG_ 544 Off_Time_Btwn_Chime 1;
BA_ "U_P708_MY2023_Tx" SG_ 544 Off_Time_Btwn_Chime 1;
BA_ "U_V710_MY2023_Tx" SG_ 544 Off_Time_Btwn_Chime 1;
BA_ "U_P702_MY2024_Tx" SG_ 544 Off_Time_Btwn_Chime 1;
BA_ "GenSigSendType" SG_ 544 Chime_Time_Criticality 3;
BA_ "U_V713N_MY2022_Rx" SG_ 544 Chime_Time_Criticality 1;
BA_ "U_V713AV_MY2022_Rx" SG_ 544 Chime_Time_Criticality 1;
BA_ "U_P708_MY2023_Rx" SG_ 544 Chime_Time_Criticality 1;
BA_ "U_V710_MY2023_Rx" SG_ 544 Chime_Time_Criticality 1;
BA_ "U_CDX74X_MY2024_Rx" SG_ 544 Chime_Time_Criticality 1;
BA_ "ECGUsedRxSignal" SG_ 544 Chime_Time_Criticality 1;
BA_ "U_V713N_MY2022_Tx" SG_ 544 Chime_Time_Criticality 1;
BA_ "U_V713AV_MY2022_Tx" SG_ 544 Chime_Time_Criticality 1;
BA_ "U_P708_MY2023_Tx" SG_ 544 Chime_Time_Criticality 1;
BA_ "U_V710_MY2023_Tx" SG_ 544 Chime_Time_Criticality 1;
BA_ "U_P702_MY2024_Tx" SG_ 544 Chime_Time_Criticality 1;
BA_ "GenSigSendType" SG_ 544 Chime_Directionality 3;
BA_ "U_V713N_MY2022_Rx" SG_ 544 Chime_Directionality 1;
BA_ "U_V713AV_MY2022_Rx" SG_ 544 Chime_Directionality 1;
BA_ "U_P708_MY2023_Rx" SG_ 544 Chime_Directionality 1;
BA_ "U_V710_MY2023_Rx" SG_ 544 Chime_Directionality 1;
BA_ "U_CDX74X_MY2024_Rx" SG_ 544 Chime_Directionality 1;
BA_ "ECGUsedRxSignal" SG_ 544 Chime_Directionality 1;
BA_ "U_V713N_MY2022_Tx" SG_ 544 Chime_Directionality 1;
BA_ "U_V713AV_MY2022_Tx" SG_ 544 Chime_Directionality 1;
BA_ "U_P708_MY2023_Tx" SG_ 544 Chime_Directionality 1;
BA_ "U_V710_MY2023_Tx" SG_ 544 Chime_Directionality 1;
BA_ "U_P702_MY2024_Tx" SG_ 544 Chime_Directionality 1;
BA_ "U_V713N_MY2022_Rx" SG_ 544 Chime_Vol_Level 1;
BA_ "U_V713AV_MY2022_Rx" SG_ 544 Chime_Vol_Level 1;
BA_ "U_P708_MY2023_Rx" SG_ 544 Chime_Vol_Level 1;
BA_ "U_V710_MY2023_Rx" SG_ 544 Chime_Vol_Level 1;
BA_ "U_CDX74X_MY2024_Rx" SG_ 544 Chime_Vol_Level 1;
BA_ "U_V713N_MY2022_Tx" SG_ 544 Chime_Vol_Level 1;
BA_ "U_V713AV_MY2022_Tx" SG_ 544 Chime_Vol_Level 1;
BA_ "U_P708_MY2023_Tx" SG_ 544 Chime_Vol_Level 1;
BA_ "U_V710_MY2023_Tx" SG_ 544 Chime_Vol_Level 1;
BA_ "U_P702_MY2024_Tx" SG_ 544 Chime_Vol_Level 1;
BA_ "WakeupSignal" SG_ 544 Chime 1;
BA_ "U_V713N_MY2022_Rx" SG_ 544 Chime 1;
BA_ "U_V713AV_MY2022_Rx" SG_ 544 Chime 1;
BA_ "U_P708_MY2023_Rx" SG_ 544 Chime 1;
BA_ "U_V710_MY2023_Rx" SG_ 544 Chime 1;
BA_ "U_CDX74X_MY2024_Rx" SG_ 544 Chime 1;
BA_ "U_V713N_MY2022_Tx" SG_ 544 Chime 1;
BA_ "U_V713AV_MY2022_Tx" SG_ 544 Chime 1;
BA_ "U_P708_MY2023_Tx" SG_ 544 Chime 1;
BA_ "U_V710_MY2023_Tx" SG_ 544 Chime 1;
BA_ "U_P702_MY2024_Tx" SG_ 544 Chime 1;
BA_ "GenSigSendType" SG_ 291 LangUpdate_Rsp 3;
BA_ "U_P708_MY2023_Rx" SG_ 291 LangUpdate_Rsp 1;
BA_ "U_V713N_MY2022_Tx" SG_ 291 LangUpdate_Rsp 1;
BA_ "U_V713AV_MY2022_Tx" SG_ 291 LangUpdate_Rsp 1;
BA_ "U_P708_MY2023_Tx" SG_ 291 LangUpdate_Rsp 1;
BA_ "U_V710_MY2023_Tx" SG_ 291 LangUpdate_Rsp 1;
BA_ "U_V713N_MY2022_Rx" SG_ 400 Mc_SetCurrntStatFreq_Rq 1;
BA_ "U_V713AV_MY2022_Rx" SG_ 400 Mc_SetCurrntStatFreq_Rq 1;
BA_ "U_P708_MY2023_Rx" SG_ 400 Mc_SetCurrntStatFreq_Rq 1;
BA_ "U_V713N_MY2022_Tx" SG_ 400 Mc_SetCurrntStatFreq_Rq 1;
BA_ "U_P702_MY2024_Tx" SG_ 400 Mc_SetCurrntStatFreq_Rq 1;
BA_ "U_V713N_MY2022_Rx" SG_ 400 Mc_SetCurrStatMCCh_Rq 1;
BA_ "U_V713AV_MY2022_Rx" SG_ 400 Mc_SetCurrStatMCCh_Rq 1;
BA_ "U_P708_MY2023_Rx" SG_ 400 Mc_SetCurrStatMCCh_Rq 1;
BA_ "U_V713N_MY2022_Tx" SG_ 400 Mc_SetCurrStatMCCh_Rq 1;
BA_ "U_P702_MY2024_Tx" SG_ 400 Mc_SetCurrStatMCCh_Rq 1;
BA_ "GenSigSendType" SG_ 400 Mc_SetCurrentStatOp_Rq 3;
BA_ "U_V713N_MY2022_Rx" SG_ 400 Mc_SetCurrentStatOp_Rq 1;
BA_ "U_V713AV_MY2022_Rx" SG_ 400 Mc_SetCurrentStatOp_Rq 1;
BA_ "U_P708_MY2023_Rx" SG_ 400 Mc_SetCurrentStatOp_Rq 1;
BA_ "U_V710_MY2023_Rx" SG_ 400 Mc_SetCurrentStatOp_Rq 1;
BA_ "U_V713N_MY2022_Tx" SG_ 400 Mc_SetCurrentStatOp_Rq 1;
BA_ "U_P702_MY2024_Tx" SG_ 400 Mc_SetCurrentStatOp_Rq 1;
BA_ "U_V713N_MY2022_Rx" SG_ 400 Mc_PerTUStartIndex2_Rq 1;
BA_ "U_V713AV_MY2022_Rx" SG_ 400 Mc_PerTUStartIndex2_Rq 1;
BA_ "U_P708_MY2023_Rx" SG_ 400 Mc_PerTUStartIndex2_Rq 1;
BA_ "U_V710_MY2023_Rx" SG_ 400 Mc_PerTUStartIndex2_Rq 1;
BA_ "U_V713N_MY2022_Tx" SG_ 400 Mc_PerTUStartIndex2_Rq 1;
BA_ "U_P702_MY2024_Tx" SG_ 400 Mc_PerTUStartIndex2_Rq 1;
BA_ "GenSigSendType" SG_ 400 Mc_PerTUPresetArea_Rq 3;
BA_ "U_V713N_MY2022_Rx" SG_ 400 Mc_PerTUPresetArea_Rq 1;
BA_ "U_V713AV_MY2022_Rx" SG_ 400 Mc_PerTUPresetArea_Rq 1;
BA_ "U_P708_MY2023_Rx" SG_ 400 Mc_PerTUPresetArea_Rq 1;
BA_ "U_V710_MY2023_Rx" SG_ 400 Mc_PerTUPresetArea_Rq 1;
BA_ "U_V713N_MY2022_Tx" SG_ 400 Mc_PerTUPresetArea_Rq 1;
BA_ "U_P702_MY2024_Tx" SG_ 400 Mc_PerTUPresetArea_Rq 1;
BA_ "U_V713N_MY2022_Rx" SG_ 400 Mc_PerTUNbrOfPresets_Rq 1;
BA_ "U_V713AV_MY2022_Rx" SG_ 400 Mc_PerTUNbrOfPresets_Rq 1;
BA_ "U_P708_MY2023_Rx" SG_ 400 Mc_PerTUNbrOfPresets_Rq 1;
BA_ "U_V710_MY2023_Rx" SG_ 400 Mc_PerTUNbrOfPresets_Rq 1;
BA_ "U_V713N_MY2022_Tx" SG_ 400 Mc_PerTUNbrOfPresets_Rq 1;
BA_ "U_P702_MY2024_Tx" SG_ 400 Mc_PerTUNbrOfPresets_Rq 1;
BA_ "GenSigSendType" SG_ 647 HEC_BTIncomingCall_Rq 3;
BA_ "U_P708_MY2023_Rx" SG_ 647 HEC_BTIncomingCall_Rq 1;
BA_ "U_V713N_MY2022_Tx" SG_ 647 HEC_BTIncomingCall_Rq 1;
BA_ "U_V713AV_MY2022_Tx" SG_ 647 HEC_BTIncomingCall_Rq 1;
BA_ "U_P708_MY2023_Tx" SG_ 647 HEC_BTIncomingCall_Rq 1;
BA_ "GenSigSendType" SG_ 647 HEC_BTEndTelService_Rq 3;
BA_ "U_P708_MY2023_Rx" SG_ 647 HEC_BTEndTelService_Rq 1;
BA_ "U_V713N_MY2022_Tx" SG_ 647 HEC_BTEndTelService_Rq 1;
BA_ "U_V713AV_MY2022_Tx" SG_ 647 HEC_BTEndTelService_Rq 1;
BA_ "U_P708_MY2023_Tx" SG_ 647 HEC_BTEndTelService_Rq 1;
BA_ "U_V713N_MY2022_Rx" SG_ 359 TrnAin_Tq_Actl 1;
BA_ "U_V713AV_MY2022_Rx" SG_ 359 TrnAin_Tq_Actl 1;
BA_ "U_P708_MY2023_Rx" SG_ 359 TrnAin_Tq_Actl 1;
BA_ "U_V710_MY2023_Rx" SG_ 359 TrnAin_Tq_Actl 1;
BA_ "U_P702_MY2024_Rx" SG_ 359 TrnAin_Tq_Actl 1;
BA_ "U_V713N_MY2022_Rx" SG_ 359 PrplWhlTot2_Tq_Actl 1;
BA_ "U_V713AV_MY2022_Rx" SG_ 359 PrplWhlTot2_Tq_Actl 1;
BA_ "U_P708_MY2023_Rx" SG_ 359 PrplWhlTot2_Tq_Actl 1;
BA_ "U_V710_MY2023_Rx" SG_ 359 PrplWhlTot2_Tq_Actl 1;
BA_ "U_P702_MY2024_Rx" SG_ 359 PrplWhlTot2_Tq_Actl 1;
BA_ "U_V713N_MY2022_Rx" SG_ 359 PwPckTq_D_Stat 1;
BA_ "U_V713AV_MY2022_Rx" SG_ 359 PwPckTq_D_Stat 1;
BA_ "U_P708_MY2023_Rx" SG_ 359 PwPckTq_D_Stat 1;
BA_ "U_V710_MY2023_Rx" SG_ 359 PwPckTq_D_Stat 1;
BA_ "U_CDX74X_MY2024_Rx" SG_ 359 PwPckTq_D_Stat 1;
BA_ "U_P702_MY2024_Rx" SG_ 359 PwPckTq_D_Stat 1;
BA_ "U_CDX707_MY2023_Rx" SG_ 359 PwPckTq_D_Stat 1;
BA_ "U_V713N_MY2022_Rx" SG_ 359 Eng_D_Stat 1;
BA_ "U_V713AV_MY2022_Rx" SG_ 359 Eng_D_Stat 1;
BA_ "U_P708_MY2023_Rx" SG_ 359 Eng_D_Stat 1;
BA_ "U_V710_MY2023_Rx" SG_ 359 Eng_D_Stat 1;
BA_ "U_CDX74X_MY2024_Rx" SG_ 359 Eng_D_Stat 1;
BA_ "U_P702_MY2024_Rx" SG_ 359 Eng_D_Stat 1;
BA_ "U_CDX707_MY2023_Rx" SG_ 359 Eng_D_Stat 1;
BA_ "GenSigStartValue" SG_ 359 PlgActvArb_B_Actl 1;
BA_ "U_P708_MY2023_Rx" SG_ 359 PlgActvArb_B_Actl 1;
BA_ "U_P702_MY2024_Rx" SG_ 359 PlgActvArb_B_Actl 1;
BA_ "U_V713N_MY2022_Rx" SG_ 359 ElPw_D_Stat 1;
BA_ "U_V713AV_MY2022_Rx" SG_ 359 ElPw_D_Stat 1;
BA_ "U_P708_MY2023_Rx" SG_ 359 ElPw_D_Stat 1;
BA_ "U_V710_MY2023_Rx" SG_ 359 ElPw_D_Stat 1;
BA_ "U_CDX74X_MY2024_Rx" SG_ 359 ElPw_D_Stat 1;
BA_ "U_CDX707_MY2023_Rx" SG_ 359 ElPw_D_Stat 1;
BA_ "U_P702_MY2024_Rx" SG_ 359 ElPw_D_Stat 1;
BA_ "MetaData" SG_ 359 TrnAinTq_D_Qf 1;
BA_ "U_V713N_MY2022_Rx" SG_ 359 TrnAinTq_D_Qf 1;
BA_ "U_V713AV_MY2022_Rx" SG_ 359 TrnAinTq_D_Qf 1;
BA_ "U_P708_MY2023_Rx" SG_ 359 TrnAinTq_D_Qf 1;
BA_ "U_V710_MY2023_Rx" SG_ 359 TrnAinTq_D_Qf 1;
BA_ "GenSigStartValue" SG_ 990 PersIndexDdm_D_Actl 4;
BA_ "U_V713N_MY2022_Rx" SG_ 990 PersIndexDdm_D_Actl 1;
BA_ "U_V713AV_MY2022_Rx" SG_ 990 PersIndexDdm_D_Actl 1;
BA_ "U_P708_MY2023_Rx" SG_ 990 PersIndexDdm_D_Actl 1;
BA_ "U_V710_MY2023_Rx" SG_ 990 PersIndexDdm_D_Actl 1;
BA_ "U_P702_MY2024_Rx" SG_ 990 PersIndexDdm_D_Actl 1;
BA_ "U_V713N_MY2022_Rx" SG_ 990 FeatNoDdm_No_Actl 1;
BA_ "U_V713AV_MY2022_Rx" SG_ 990 FeatNoDdm_No_Actl 1;
BA_ "U_P708_MY2023_Rx" SG_ 990 FeatNoDdm_No_Actl 1;
BA_ "U_V710_MY2023_Rx" SG_ 990 FeatNoDdm_No_Actl 1;
BA_ "U_P702_MY2024_Rx" SG_ 990 FeatNoDdm_No_Actl 1;
BA_ "U_V713N_MY2022_Rx" SG_ 990 FeatConfigDdmActl 1;
BA_ "U_V713AV_MY2022_Rx" SG_ 990 FeatConfigDdmActl 1;
BA_ "U_P708_MY2023_Rx" SG_ 990 FeatConfigDdmActl 1;
BA_ "U_V710_MY2023_Rx" SG_ 990 FeatConfigDdmActl 1;
BA_ "U_P702_MY2024_Rx" SG_ 990 FeatConfigDdmActl 1;
BA_ "U_V713N_MY2022_Rx" SG_ 989 FeatNoHcm_No_Actl 1;
BA_ "U_V713AV_MY2022_Rx" SG_ 989 FeatNoHcm_No_Actl 1;
BA_ "U_P708_MY2023_Rx" SG_ 989 FeatNoHcm_No_Actl 1;
BA_ "U_V710_MY2023_Rx" SG_ 989 FeatNoHcm_No_Actl 1;
BA_ "U_P702_MY2024_Rx" SG_ 989 FeatNoHcm_No_Actl 1;
BA_ "U_V713N_MY2022_Rx" SG_ 989 FeatConfigHcmActl 1;
BA_ "U_V713AV_MY2022_Rx" SG_ 989 FeatConfigHcmActl 1;
BA_ "U_P708_MY2023_Rx" SG_ 989 FeatConfigHcmActl 1;
BA_ "U_V710_MY2023_Rx" SG_ 989 FeatConfigHcmActl 1;
BA_ "U_P702_MY2024_Rx" SG_ 989 FeatConfigHcmActl 1;
BA_ "GenSigStartValue" SG_ 1091 WakeAlarm2_T_Rq 32767;
BA_ "GenSigSendType" SG_ 1091 WakeAlarm2_T_Rq 3;
BA_ "U_P708_MY2023_Tx" SG_ 1091 WakeAlarm2_T_Rq 1;
BA_ "U_CDX707_MY2023_Tx" SG_ 1091 WakeAlarm2_T_Rq 1;
BA_ "U_CDX74X_MY2024_Tx" SG_ 1091 WakeAlarm2_T_Rq 1;
BA_ "U_V710_MY2023_Tx" SG_ 1091 WakeAlarm2_T_Rq 1;
BA_ "U_P702_MY2024_Tx" SG_ 1091 WakeAlarm2_T_Rq 1;
BA_ "GenSigSendType" SG_ 1091 WakeAlarm2_B_Typ 3;
BA_ "U_P708_MY2023_Tx" SG_ 1091 WakeAlarm2_B_Typ 1;
BA_ "U_CDX707_MY2023_Tx" SG_ 1091 WakeAlarm2_B_Typ 1;
BA_ "U_CDX74X_MY2024_Tx" SG_ 1091 WakeAlarm2_B_Typ 1;
BA_ "U_V710_MY2023_Tx" SG_ 1091 WakeAlarm2_B_Typ 1;
BA_ "U_P702_MY2024_Tx" SG_ 1091 WakeAlarm2_B_Typ 1;
BA_ "U_V710_MY2023_Rx" SG_ 1091 CamraRearOn_D2_Stat2 1;
BA_ "U_P708_MY2023_Rx" SG_ 1091 CamraRearOn_D2_Stat2 1;
BA_ "U_P702_MY2024_Rx" SG_ 1091 CamraRearOn_D2_Stat2 1;
BA_ "U_V710_MY2023_Tx" SG_ 1091 CamraRearOn_D2_Stat2 1;
BA_ "U_V713AV_MY2022_Rx" SG_ 1091 PoliceAux4Lamp_B_Rq2 1;
BA_ "U_P708_MY2023_Rx" SG_ 1091 PoliceAux4Lamp_B_Rq2 1;
BA_ "U_V710_MY2023_Rx" SG_ 1091 PoliceAux4Lamp_B_Rq2 1;
BA_ "U_V713N_MY2022_Rx" SG_ 1091 PoliceAux4Lamp_B_Rq2 1;
BA_ "U_P702_MY2024_Rx" SG_ 1091 PoliceAux4Lamp_B_Rq2 1;
BA_ "U_V713AV_MY2022_Rx" SG_ 1091 PoliceAux3Lamp_B_Rq2 1;
BA_ "U_P708_MY2023_Rx" SG_ 1091 PoliceAux3Lamp_B_Rq2 1;
BA_ "U_V710_MY2023_Rx" SG_ 1091 PoliceAux3Lamp_B_Rq2 1;
BA_ "U_V713N_MY2022_Rx" SG_ 1091 PoliceAux3Lamp_B_Rq2 1;
BA_ "U_P702_MY2024_Rx" SG_ 1091 PoliceAux3Lamp_B_Rq2 1;
BA_ "U_V713AV_MY2022_Rx" SG_ 1091 PoliceAux2Lamp_B_Rq2 1;
BA_ "U_P708_MY2023_Rx" SG_ 1091 PoliceAux2Lamp_B_Rq2 1;
BA_ "U_V710_MY2023_Rx" SG_ 1091 PoliceAux2Lamp_B_Rq2 1;
BA_ "U_V713N_MY2022_Rx" SG_ 1091 PoliceAux2Lamp_B_Rq2 1;
BA_ "U_P702_MY2024_Rx" SG_ 1091 PoliceAux2Lamp_B_Rq2 1;
BA_ "U_V713AV_MY2022_Rx" SG_ 1091 PoliceAux1Lamp_B_Rq2 1;
BA_ "U_P708_MY2023_Rx" SG_ 1091 PoliceAux1Lamp_B_Rq2 1;
BA_ "U_V710_MY2023_Rx" SG_ 1091 PoliceAux1Lamp_B_Rq2 1;
BA_ "U_V713N_MY2022_Rx" SG_ 1091 PoliceAux1Lamp_B_Rq2 1;
BA_ "U_P702_MY2024_Rx" SG_ 1091 PoliceAux1Lamp_B_Rq2 1;
BA_ "U_V713N_MY2022_Rx" SG_ 1091 TowBarMsgTxt_D_Rq 1;
BA_ "U_V713AV_MY2022_Rx" SG_ 1091 TowBarMsgTxt_D_Rq 1;
BA_ "U_V710_MY2023_Rx" SG_ 1091 TowBarMsgTxt_D_Rq 1;
BA_ "U_P708_MY2023_Rx" SG_ 1091 TowBarMsgTxt_D_Rq 1;
BA_ "U_P702_MY2024_Rx" SG_ 1091 TowBarMsgTxt_D_Rq 1;
BA_ "U_CDX74X_MY2024_Tx" SG_ 1091 TowBarMsgTxt_D_Rq 1;
BA_ "U_V710_MY2023_Tx" SG_ 1091 TowBarMsgTxt_D_Rq 1;
BA_ "U_V713N_MY2022_Rx" SG_ 1091 ParkLampTrlrOut_B_Stat 1;
BA_ "U_V713AV_MY2022_Rx" SG_ 1091 ParkLampTrlrOut_B_Stat 1;
BA_ "U_P708_MY2023_Rx" SG_ 1091 ParkLampTrlrOut_B_Stat 1;
BA_ "U_V710_MY2023_Rx" SG_ 1091 ParkLampTrlrOut_B_Stat 1;
BA_ "U_P702_MY2024_Rx" SG_ 1091 ParkLampTrlrOut_B_Stat 1;
BA_ "U_CDX707_MY2023_Tx" SG_ 1091 ParkLampTrlrOut_B_Stat 1;
BA_ "U_CDX74X_MY2024_Tx" SG_ 1091 ParkLampTrlrOut_B_Stat 1;
BA_ "U_V710_MY2023_Tx" SG_ 1091 ParkLampTrlrOut_B_Stat 1;
BA_ "U_V713N_MY2022_Rx" SG_ 1091 StopLampTrlrOut_B_Stat 1;
BA_ "U_V713AV_MY2022_Rx" SG_ 1091 StopLampTrlrOut_B_Stat 1;
BA_ "U_P708_MY2023_Rx" SG_ 1091 StopLampTrlrOut_B_Stat 1;
BA_ "U_V710_MY2023_Rx" SG_ 1091 StopLampTrlrOut_B_Stat 1;
BA_ "U_P702_MY2024_Rx" SG_ 1091 StopLampTrlrOut_B_Stat 1;
BA_ "U_CDX74X_MY2024_Tx" SG_ 1091 StopLampTrlrOut_B_Stat 1;
BA_ "U_V710_MY2023_Tx" SG_ 1091 StopLampTrlrOut_B_Stat 1;
BA_ "U_V713N_MY2022_Rx" SG_ 1091 TrlrBattChrg_D_Stat 1;
BA_ "U_V713AV_MY2022_Rx" SG_ 1091 TrlrBattChrg_D_Stat 1;
BA_ "U_P708_MY2023_Rx" SG_ 1091 TrlrBattChrg_D_Stat 1;
BA_ "U_V710_MY2023_Rx" SG_ 1091 TrlrBattChrg_D_Stat 1;
BA_ "U_P702_MY2024_Rx" SG_ 1091 TrlrBattChrg_D_Stat 1;
BA_ "U_P708_MY2023_Tx" SG_ 1091 TrlrBattChrg_D_Stat 1;
BA_ "U_CDX74X_MY2024_Tx" SG_ 1091 TrlrBattChrg_D_Stat 1;
BA_ "U_V710_MY2023_Tx" SG_ 1091 TrlrBattChrg_D_Stat 1;
BA_ "U_P702_MY2024_Tx" SG_ 1091 TrlrBattChrg_D_Stat 1;
BA_ "U_V713N_MY2022_Rx" SG_ 1091 TrlrLampCtl_D_Stat 1;
BA_ "U_V713AV_MY2022_Rx" SG_ 1091 TrlrLampCtl_D_Stat 1;
BA_ "U_P708_MY2023_Rx" SG_ 1091 TrlrLampCtl_D_Stat 1;
BA_ "U_V710_MY2023_Rx" SG_ 1091 TrlrLampCtl_D_Stat 1;
BA_ "U_P702_MY2024_Rx" SG_ 1091 TrlrLampCtl_D_Stat 1;
BA_ "U_P708_MY2023_Tx" SG_ 1091 TrlrLampCtl_D_Stat 1;
BA_ "U_CDX707_MY2023_Tx" SG_ 1091 TrlrLampCtl_D_Stat 1;
BA_ "U_CDX74X_MY2024_Tx" SG_ 1091 TrlrLampCtl_D_Stat 1;
BA_ "U_V710_MY2023_Tx" SG_ 1091 TrlrLampCtl_D_Stat 1;
BA_ "U_P702_MY2024_Tx" SG_ 1091 TrlrLampCtl_D_Stat 1;
BA_ "GenSigSendType" SG_ 1091 TrlrAlarmSpprt_D_Stat 3;
BA_ "U_V710_MY2023_Rx" SG_ 1091 TrlrAlarmSpprt_D_Stat 1;
BA_ "U_P708_MY2023_Rx" SG_ 1091 TrlrAlarmSpprt_D_Stat 1;
BA_ "U_P702_MY2024_Rx" SG_ 1091 TrlrAlarmSpprt_D_Stat 1;
BA_ "U_P708_MY2023_Tx" SG_ 1091 TrlrAlarmSpprt_D_Stat 1;
BA_ "U_CDX707_MY2023_Tx" SG_ 1091 TrlrAlarmSpprt_D_Stat 1;
BA_ "U_CDX74X_MY2024_Tx" SG_ 1091 TrlrAlarmSpprt_D_Stat 1;
BA_ "U_V710_MY2023_Tx" SG_ 1091 TrlrAlarmSpprt_D_Stat 1;
BA_ "U_P702_MY2024_Tx" SG_ 1091 TrlrAlarmSpprt_D_Stat 1;
BA_ "U_V713N_MY2022_Rx" SG_ 1091 TurnLampTrlrRr_B_Stat 1;
BA_ "U_V713AV_MY2022_Rx" SG_ 1091 TurnLampTrlrRr_B_Stat 1;
BA_ "U_P708_MY2023_Rx" SG_ 1091 TurnLampTrlrRr_B_Stat 1;
BA_ "U_V710_MY2023_Rx" SG_ 1091 TurnLampTrlrRr_B_Stat 1;
BA_ "U_P702_MY2024_Rx" SG_ 1091 TurnLampTrlrRr_B_Stat 1;
BA_ "U_P708_MY2023_Tx" SG_ 1091 TurnLampTrlrRr_B_Stat 1;
BA_ "U_CDX707_MY2023_Tx" SG_ 1091 TurnLampTrlrRr_B_Stat 1;
BA_ "U_CDX74X_MY2024_Tx" SG_ 1091 TurnLampTrlrRr_B_Stat 1;
BA_ "U_V710_MY2023_Tx" SG_ 1091 TurnLampTrlrRr_B_Stat 1;
BA_ "U_P702_MY2024_Tx" SG_ 1091 TurnLampTrlrRr_B_Stat 1;
BA_ "U_V713N_MY2022_Rx" SG_ 1091 TurnLampTrlrRl_B_Stat 1;
BA_ "U_V713AV_MY2022_Rx" SG_ 1091 TurnLampTrlrRl_B_Stat 1;
BA_ "U_P708_MY2023_Rx" SG_ 1091 TurnLampTrlrRl_B_Stat 1;
BA_ "U_V710_MY2023_Rx" SG_ 1091 TurnLampTrlrRl_B_Stat 1;
BA_ "U_P702_MY2024_Rx" SG_ 1091 TurnLampTrlrRl_B_Stat 1;
BA_ "U_P708_MY2023_Tx" SG_ 1091 TurnLampTrlrRl_B_Stat 1;
BA_ "U_CDX707_MY2023_Tx" SG_ 1091 TurnLampTrlrRl_B_Stat 1;
BA_ "U_CDX74X_MY2024_Tx" SG_ 1091 TurnLampTrlrRl_B_Stat 1;
BA_ "U_V710_MY2023_Tx" SG_ 1091 TurnLampTrlrRl_B_Stat 1;
BA_ "U_P702_MY2024_Tx" SG_ 1091 TurnLampTrlrRl_B_Stat 1;
BA_ "U_V713N_MY2022_Rx" SG_ 1091 TrlrLampCnnct_B_Actl 1;
BA_ "U_V713AV_MY2022_Rx" SG_ 1091 TrlrLampCnnct_B_Actl 1;
BA_ "U_P708_MY2023_Rx" SG_ 1091 TrlrLampCnnct_B_Actl 1;
BA_ "U_V710_MY2023_Rx" SG_ 1091 TrlrLampCnnct_B_Actl 1;
BA_ "U_P702_MY2024_Rx" SG_ 1091 TrlrLampCnnct_B_Actl 1;
BA_ "U_P708_MY2023_Tx" SG_ 1091 TrlrLampCnnct_B_Actl 1;
BA_ "U_CDX707_MY2023_Tx" SG_ 1091 TrlrLampCnnct_B_Actl 1;
BA_ "U_CDX74X_MY2024_Tx" SG_ 1091 TrlrLampCnnct_B_Actl 1;
BA_ "U_V710_MY2023_Tx" SG_ 1091 TrlrLampCnnct_B_Actl 1;
BA_ "U_P702_MY2024_Tx" SG_ 1091 TrlrLampCnnct_B_Actl 1;
BA_ "GenSigStartValue" SG_ 1045 VehStab_D_Stat 14;
BA_ "GenSigStartValue" SG_ 1045 VehYawNonLin_W_Rq 4094;
BA_ "GenSigStartValue" SG_ 1045 VehYawLin_W_Rq 4094;
BA_ "MetaData" SG_ 1045 VehVActlBrk_No_Cs 1;
BA_ "U_P708_MY2023_Rx" SG_ 1045 VehVActlBrk_No_Cs 1;
BA_ "U_CDX74X_MY2024_Rx" SG_ 1045 VehVActlBrk_No_Cs 1;
BA_ "U_V710_MY2023_Rx" SG_ 1045 VehVActlBrk_No_Cs 1;
BA_ "U_P702_MY2024_Rx" SG_ 1045 VehVActlBrk_No_Cs 1;
BA_ "U_P708_MY2023_Rx" SG_ 1045 Veh_V_ActlBrk 1;
BA_ "U_CDX74X_MY2024_Rx" SG_ 1045 Veh_V_ActlBrk 1;
BA_ "U_V710_MY2023_Rx" SG_ 1045 Veh_V_ActlBrk 1;
BA_ "U_P702_MY2024_Rx" SG_ 1045 Veh_V_ActlBrk 1;
BA_ "MetaData" SG_ 1045 VehVActlBrk_No_Cnt 1;
BA_ "U_P708_MY2023_Rx" SG_ 1045 VehVActlBrk_No_Cnt 1;
BA_ "U_CDX74X_MY2024_Rx" SG_ 1045 VehVActlBrk_No_Cnt 1;
BA_ "U_V710_MY2023_Rx" SG_ 1045 VehVActlBrk_No_Cnt 1;
BA_ "U_P702_MY2024_Rx" SG_ 1045 VehVActlBrk_No_Cnt 1;
BA_ "MetaData" SG_ 1045 VehVActlBrk_D_Qf 1;
BA_ "U_P708_MY2023_Rx" SG_ 1045 VehVActlBrk_D_Qf 1;
BA_ "U_CDX74X_MY2024_Rx" SG_ 1045 VehVActlBrk_D_Qf 1;
BA_ "U_V710_MY2023_Rx" SG_ 1045 VehVActlBrk_D_Qf 1;
BA_ "U_P702_MY2024_Rx" SG_ 1045 VehVActlBrk_D_Qf 1;
BA_ "GenSigStartValue" SG_ 1439 WCM_GWOnBoardTester 255;
BA_ "U_V710_MY2023_Rx" SG_ 1439 WCM_GWOnBoardTester 1;
BA_ "U_P708_MY2023_Rx" SG_ 1439 WCM_GWOnBoardTester 1;
BA_ "U_P702_MY2024_Rx" SG_ 1439 WCM_GWOnBoardTester 1;
BA_ "U_V713N_MY2022_Tx" SG_ 1439 WCM_GWOnBoardTester 1;
BA_ "U_P708_MY2023_Tx" SG_ 1439 WCM_GWOnBoardTester 1;
BA_ "U_CDX74X_MY2024_Tx" SG_ 1439 WCM_GWOnBoardTester 1;
BA_ "U_V710_MY2023_Tx" SG_ 1439 WCM_GWOnBoardTester 1;
BA_ "U_P702_MY2024_Tx" SG_ 1439 WCM_GWOnBoardTester 1;
BA_ "GenSigStartValue" SG_ 1439 WCM_GWNMProxy 255;
BA_ "U_V710_MY2023_Rx" SG_ 1439 WCM_GWNMProxy 1;
BA_ "U_P708_MY2023_Rx" SG_ 1439 WCM_GWNMProxy 1;
BA_ "U_P702_MY2024_Rx" SG_ 1439 WCM_GWNMProxy 1;
BA_ "U_V713N_MY2022_Tx" SG_ 1439 WCM_GWNMProxy 1;
BA_ "U_P708_MY2023_Tx" SG_ 1439 WCM_GWNMProxy 1;
BA_ "U_CDX74X_MY2024_Tx" SG_ 1439 WCM_GWNMProxy 1;
BA_ "U_V710_MY2023_Tx" SG_ 1439 WCM_GWNMProxy 1;
BA_ "U_P702_MY2024_Tx" SG_ 1439 WCM_GWNMProxy 1;
BA_ "GenSigStartValue" SG_ 1439 WCM_AutoSarNMReserved4 255;
BA_ "U_V710_MY2023_Rx" SG_ 1439 WCM_AutoSarNMReserved4 1;
BA_ "U_P708_MY2023_Rx" SG_ 1439 WCM_AutoSarNMReserved4 1;
BA_ "U_P702_MY2024_Rx" SG_ 1439 WCM_AutoSarNMReserved4 1;
BA_ "U_V713N_MY2022_Tx" SG_ 1439 WCM_AutoSarNMReserved4 1;
BA_ "U_P708_MY2023_Tx" SG_ 1439 WCM_AutoSarNMReserved4 1;
BA_ "U_CDX74X_MY2024_Tx" SG_ 1439 WCM_AutoSarNMReserved4 1;
BA_ "U_V710_MY2023_Tx" SG_ 1439 WCM_AutoSarNMReserved4 1;
BA_ "U_P702_MY2024_Tx" SG_ 1439 WCM_AutoSarNMReserved4 1;
BA_ "GenSigStartValue" SG_ 1439 WCM_AutoSarNMReserved3 255;
BA_ "U_V710_MY2023_Rx" SG_ 1439 WCM_AutoSarNMReserved3 1;
BA_ "U_P708_MY2023_Rx" SG_ 1439 WCM_AutoSarNMReserved3 1;
BA_ "U_P702_MY2024_Rx" SG_ 1439 WCM_AutoSarNMReserved3 1;
BA_ "U_V713N_MY2022_Tx" SG_ 1439 WCM_AutoSarNMReserved3 1;
BA_ "U_P708_MY2023_Tx" SG_ 1439 WCM_AutoSarNMReserved3 1;
BA_ "U_CDX74X_MY2024_Tx" SG_ 1439 WCM_AutoSarNMReserved3 1;
BA_ "U_V710_MY2023_Tx" SG_ 1439 WCM_AutoSarNMReserved3 1;
BA_ "U_P702_MY2024_Tx" SG_ 1439 WCM_AutoSarNMReserved3 1;
BA_ "GenSigStartValue" SG_ 1439 WCM_AutoSarNMReserved2 255;
BA_ "U_V710_MY2023_Rx" SG_ 1439 WCM_AutoSarNMReserved2 1;
BA_ "U_P708_MY2023_Rx" SG_ 1439 WCM_AutoSarNMReserved2 1;
BA_ "U_P702_MY2024_Rx" SG_ 1439 WCM_AutoSarNMReserved2 1;
BA_ "U_V713N_MY2022_Tx" SG_ 1439 WCM_AutoSarNMReserved2 1;
BA_ "U_P708_MY2023_Tx" SG_ 1439 WCM_AutoSarNMReserved2 1;
BA_ "U_CDX74X_MY2024_Tx" SG_ 1439 WCM_AutoSarNMReserved2 1;
BA_ "U_V710_MY2023_Tx" SG_ 1439 WCM_AutoSarNMReserved2 1;
BA_ "U_P702_MY2024_Tx" SG_ 1439 WCM_AutoSarNMReserved2 1;
BA_ "GenSigStartValue" SG_ 1439 WCM_AutoSarNMReserved1 255;
BA_ "U_V710_MY2023_Rx" SG_ 1439 WCM_AutoSarNMReserved1 1;
BA_ "U_P708_MY2023_Rx" SG_ 1439 WCM_AutoSarNMReserved1 1;
BA_ "U_P702_MY2024_Rx" SG_ 1439 WCM_AutoSarNMReserved1 1;
BA_ "U_V713N_MY2022_Tx" SG_ 1439 WCM_AutoSarNMReserved1 1;
BA_ "U_P708_MY2023_Tx" SG_ 1439 WCM_AutoSarNMReserved1 1;
BA_ "U_CDX74X_MY2024_Tx" SG_ 1439 WCM_AutoSarNMReserved1 1;
BA_ "U_V710_MY2023_Tx" SG_ 1439 WCM_AutoSarNMReserved1 1;
BA_ "U_P702_MY2024_Tx" SG_ 1439 WCM_AutoSarNMReserved1 1;
BA_ "GenSigStartValue" SG_ 1439 WCM_AutoSarNMNodeId 159;
BA_ "U_P708_MY2023_Rx" SG_ 1439 WCM_AutoSarNMNodeId 1;
BA_ "U_P702_MY2024_Rx" SG_ 1439 WCM_AutoSarNMNodeId 1;
BA_ "U_V710_MY2023_Rx" SG_ 1439 WCM_AutoSarNMNodeId 1;
BA_ "U_V713N_MY2022_Tx" SG_ 1439 WCM_AutoSarNMNodeId 1;
BA_ "U_P708_MY2023_Tx" SG_ 1439 WCM_AutoSarNMNodeId 1;
BA_ "U_CDX74X_MY2024_Tx" SG_ 1439 WCM_AutoSarNMNodeId 1;
BA_ "U_V710_MY2023_Tx" SG_ 1439 WCM_AutoSarNMNodeId 1;
BA_ "U_P702_MY2024_Tx" SG_ 1439 WCM_AutoSarNMNodeId 1;
BA_ "U_P708_MY2023_Rx" SG_ 1439 WCM_AutoSarNMControl 1;
BA_ "U_P702_MY2024_Rx" SG_ 1439 WCM_AutoSarNMControl 1;
BA_ "U_V710_MY2023_Rx" SG_ 1439 WCM_AutoSarNMControl 1;
BA_ "U_V713N_MY2022_Tx" SG_ 1439 WCM_AutoSarNMControl 1;
BA_ "U_P708_MY2023_Tx" SG_ 1439 WCM_AutoSarNMControl 1;
BA_ "U_CDX74X_MY2024_Tx" SG_ 1439 WCM_AutoSarNMControl 1;
BA_ "U_V710_MY2023_Tx" SG_ 1439 WCM_AutoSarNMControl 1;
BA_ "U_P702_MY2024_Tx" SG_ 1439 WCM_AutoSarNMControl 1;
BA_ "GenSigStartValue" SG_ 261 ChrgStatDsply_D_Rq 1;
BA_ "GenSigSendType" SG_ 261 ChrgStatDsply_D_Rq 3;
BA_ "U_V713N_MY2022_Tx" SG_ 261 ChrgStatDsply_D_Rq 1;
BA_ "U_V713AV_MY2022_Tx" SG_ 261 ChrgStatDsply_D_Rq 1;
BA_ "U_P708_MY2023_Tx" SG_ 261 ChrgStatDsply_D_Rq 1;
BA_ "U_V710_MY2023_Tx" SG_ 261 ChrgStatDsply_D_Rq 1;
BA_ "U_P702_MY2024_Tx" SG_ 261 ChrgStatDsply_D_Rq 1;
BA_ "GenSigSendType" SG_ 261 OffPeakTimeSetMin_Rq 3;
BA_ "U_V713N_MY2022_Tx" SG_ 261 OffPeakTimeSetMin_Rq 1;
BA_ "U_V713AV_MY2022_Tx" SG_ 261 OffPeakTimeSetMin_Rq 1;
BA_ "U_P708_MY2023_Tx" SG_ 261 OffPeakTimeSetMin_Rq 1;
BA_ "U_V710_MY2023_Tx" SG_ 261 OffPeakTimeSetMin_Rq 1;
BA_ "U_P702_MY2024_Tx" SG_ 261 OffPeakTimeSetMin_Rq 1;
BA_ "GenSigSendType" SG_ 261 OffPeakTimeSetHR_Rq 3;
BA_ "U_V713N_MY2022_Tx" SG_ 261 OffPeakTimeSetHR_Rq 1;
BA_ "U_V713AV_MY2022_Tx" SG_ 261 OffPeakTimeSetHR_Rq 1;
BA_ "U_P708_MY2023_Tx" SG_ 261 OffPeakTimeSetHR_Rq 1;
BA_ "U_V710_MY2023_Tx" SG_ 261 OffPeakTimeSetHR_Rq 1;
BA_ "U_P702_MY2024_Tx" SG_ 261 OffPeakTimeSetHR_Rq 1;
BA_ "GenSigSendType" SG_ 261 NextUsageTimeToggle_Rq 3;
BA_ "U_V713N_MY2022_Tx" SG_ 261 NextUsageTimeToggle_Rq 1;
BA_ "U_V713AV_MY2022_Tx" SG_ 261 NextUsageTimeToggle_Rq 1;
BA_ "U_P708_MY2023_Tx" SG_ 261 NextUsageTimeToggle_Rq 1;
BA_ "U_V710_MY2023_Tx" SG_ 261 NextUsageTimeToggle_Rq 1;
BA_ "U_P702_MY2024_Tx" SG_ 261 NextUsageTimeToggle_Rq 1;
BA_ "GenSigSendType" SG_ 261 LongTermParking_Rq 3;
BA_ "U_V713N_MY2022_Tx" SG_ 261 LongTermParking_Rq 1;
BA_ "U_V713AV_MY2022_Tx" SG_ 261 LongTermParking_Rq 1;
BA_ "U_P708_MY2023_Tx" SG_ 261 LongTermParking_Rq 1;
BA_ "U_V710_MY2023_Tx" SG_ 261 LongTermParking_Rq 1;
BA_ "U_P702_MY2024_Tx" SG_ 261 LongTermParking_Rq 1;
BA_ "GenSigSendType" SG_ 261 CbnCmrtPrefLstNmItm_Rq 3;
BA_ "U_V713N_MY2022_Tx" SG_ 261 CbnCmrtPrefLstNmItm_Rq 1;
BA_ "U_V713AV_MY2022_Tx" SG_ 261 CbnCmrtPrefLstNmItm_Rq 1;
BA_ "U_P708_MY2023_Tx" SG_ 261 CbnCmrtPrefLstNmItm_Rq 1;
BA_ "U_V710_MY2023_Tx" SG_ 261 CbnCmrtPrefLstNmItm_Rq 1;
BA_ "U_P702_MY2024_Tx" SG_ 261 CbnCmrtPrefLstNmItm_Rq 1;
BA_ "GenSigSendType" SG_ 261 CbnCmrtPrefListIndx_Rq 3;
BA_ "U_V713N_MY2022_Tx" SG_ 261 CbnCmrtPrefListIndx_Rq 1;
BA_ "U_V713AV_MY2022_Tx" SG_ 261 CbnCmrtPrefListIndx_Rq 1;
BA_ "U_P708_MY2023_Tx" SG_ 261 CbnCmrtPrefListIndx_Rq 1;
BA_ "U_V710_MY2023_Tx" SG_ 261 CbnCmrtPrefListIndx_Rq 1;
BA_ "U_P702_MY2024_Tx" SG_ 261 CbnCmrtPrefListIndx_Rq 1;
BA_ "GenSigSendType" SG_ 261 ModemReset_D_Rq 3;
BA_ "ECGUsedRxSignal" SG_ 261 ModemReset_D_Rq 1;
BA_ "U_V713N_MY2022_Rx" SG_ 261 ModemReset_D_Rq 1;
BA_ "U_V713AV_MY2022_Rx" SG_ 261 ModemReset_D_Rq 1;
BA_ "U_P708_MY2023_Rx" SG_ 261 ModemReset_D_Rq 1;
BA_ "U_CDX74X_MY2024_Rx" SG_ 261 ModemReset_D_Rq 1;
BA_ "U_V710_MY2023_Rx" SG_ 261 ModemReset_D_Rq 1;
BA_ "U_V713N_MY2022_Tx" SG_ 261 ModemReset_D_Rq 1;
BA_ "U_V713AV_MY2022_Tx" SG_ 261 ModemReset_D_Rq 1;
BA_ "U_P708_MY2023_Tx" SG_ 261 ModemReset_D_Rq 1;
BA_ "U_V710_MY2023_Tx" SG_ 261 ModemReset_D_Rq 1;
BA_ "U_P702_MY2024_Tx" SG_ 261 ModemReset_D_Rq 1;
BA_ "GenSigSendType" SG_ 261 StopStrtDrvMde_B_RqBtn3 3;
BA_ "U_V713N_MY2022_Tx" SG_ 261 StopStrtDrvMde_B_RqBtn3 1;
BA_ "U_V713AV_MY2022_Tx" SG_ 261 StopStrtDrvMde_B_RqBtn3 1;
BA_ "U_P708_MY2023_Tx" SG_ 261 StopStrtDrvMde_B_RqBtn3 1;
BA_ "U_V710_MY2023_Tx" SG_ 261 StopStrtDrvMde_B_RqBtn3 1;
BA_ "U_P702_MY2024_Tx" SG_ 261 StopStrtDrvMde_B_RqBtn3 1;
BA_ "GenSigSendType" SG_ 261 AudioToneTouchY_D_Rq 3;
BA_ "U_V713N_MY2022_Tx" SG_ 261 AudioToneTouchY_D_Rq 1;
BA_ "U_V713AV_MY2022_Tx" SG_ 261 AudioToneTouchY_D_Rq 1;
BA_ "U_P708_MY2023_Tx" SG_ 261 AudioToneTouchY_D_Rq 1;
BA_ "U_V710_MY2023_Tx" SG_ 261 AudioToneTouchY_D_Rq 1;
BA_ "U_P702_MY2024_Tx" SG_ 261 AudioToneTouchY_D_Rq 1;
BA_ "GenSigSendType" SG_ 261 AudioToneTouchX_D_Rq 3;
BA_ "U_V713N_MY2022_Tx" SG_ 261 AudioToneTouchX_D_Rq 1;
BA_ "U_V713AV_MY2022_Tx" SG_ 261 AudioToneTouchX_D_Rq 1;
BA_ "U_P708_MY2023_Tx" SG_ 261 AudioToneTouchX_D_Rq 1;
BA_ "U_V710_MY2023_Tx" SG_ 261 AudioToneTouchX_D_Rq 1;
BA_ "U_P702_MY2024_Tx" SG_ 261 AudioToneTouchX_D_Rq 1;
BA_ "GenSigSendType" SG_ 261 TCU_ESN_D_Rq 3;
BA_ "U_V713N_MY2022_Tx" SG_ 261 TCU_ESN_D_Rq 1;
BA_ "U_V713AV_MY2022_Tx" SG_ 261 TCU_ESN_D_Rq 1;
BA_ "U_P708_MY2023_Tx" SG_ 261 TCU_ESN_D_Rq 1;
BA_ "U_V710_MY2023_Tx" SG_ 261 TCU_ESN_D_Rq 1;
BA_ "U_P702_MY2024_Tx" SG_ 261 TCU_ESN_D_Rq 1;
BA_ "GenSigSendType" SG_ 261 FactoryReset_Rq 3;
BA_ "ECGUsedRxSignal" SG_ 261 FactoryReset_Rq 1;
BA_ "U_V713N_MY2022_Rx" SG_ 261 FactoryReset_Rq 1;
BA_ "U_V713AV_MY2022_Rx" SG_ 261 FactoryReset_Rq 1;
BA_ "U_P708_MY2023_Rx" SG_ 261 FactoryReset_Rq 1;
BA_ "U_CDX74X_MY2024_Rx" SG_ 261 FactoryReset_Rq 1;
BA_ "U_V710_MY2023_Rx" SG_ 261 FactoryReset_Rq 1;
BA_ "U_V713N_MY2022_Tx" SG_ 261 FactoryReset_Rq 1;
BA_ "U_V713AV_MY2022_Tx" SG_ 261 FactoryReset_Rq 1;
BA_ "U_P708_MY2023_Tx" SG_ 261 FactoryReset_Rq 1;
BA_ "U_V710_MY2023_Tx" SG_ 261 FactoryReset_Rq 1;
BA_ "U_P702_MY2024_Tx" SG_ 261 FactoryReset_Rq 1;
BA_ "GenSigSendType" SG_ 261 OffPeakTimeSetType_Rq 3;
BA_ "U_V713N_MY2022_Tx" SG_ 261 OffPeakTimeSetType_Rq 1;
BA_ "U_V713AV_MY2022_Tx" SG_ 261 OffPeakTimeSetType_Rq 1;
BA_ "U_P708_MY2023_Tx" SG_ 261 OffPeakTimeSetType_Rq 1;
BA_ "U_V710_MY2023_Tx" SG_ 261 OffPeakTimeSetType_Rq 1;
BA_ "U_P702_MY2024_Tx" SG_ 261 OffPeakTimeSetType_Rq 1;
BA_ "GenSigSendType" SG_ 261 AudioToneTouch_D_Rq 3;
BA_ "U_V713N_MY2022_Tx" SG_ 261 AudioToneTouch_D_Rq 1;
BA_ "U_V713AV_MY2022_Tx" SG_ 261 AudioToneTouch_D_Rq 1;
BA_ "U_P708_MY2023_Tx" SG_ 261 AudioToneTouch_D_Rq 1;
BA_ "U_V710_MY2023_Tx" SG_ 261 AudioToneTouch_D_Rq 1;
BA_ "U_P702_MY2024_Tx" SG_ 261 AudioToneTouch_D_Rq 1;
BA_ "U_V713AV_MY2022_Rx" SG_ 995 KeyAssocCmplt_B_Rq 1;
BA_ "U_P708_MY2023_Rx" SG_ 995 KeyAssocCmplt_B_Rq 1;
BA_ "U_V710_MY2023_Rx" SG_ 995 KeyAssocCmplt_B_Rq 1;
BA_ "U_V713N_MY2022_Rx" SG_ 995 KeyAssocCmplt_B_Rq 1;
BA_ "U_P702_MY2024_Rx" SG_ 995 KeyAssocCmplt_B_Rq 1;
BA_ "U_V713N_MY2022_Rx" SG_ 995 FobAssocChime_B_Rq 1;
BA_ "U_V713AV_MY2022_Rx" SG_ 995 FobAssocChime_B_Rq 1;
BA_ "U_P708_MY2023_Rx" SG_ 995 FobAssocChime_B_Rq 1;
BA_ "U_V710_MY2023_Rx" SG_ 995 FobAssocChime_B_Rq 1;
BA_ "U_P702_MY2024_Rx" SG_ 995 FobAssocChime_B_Rq 1;
BA_ "GenSigStartValue" SG_ 995 PersIndexBcm_D_Actl 4;
BA_ "U_V713N_MY2022_Rx" SG_ 995 PersIndexBcm_D_Actl 1;
BA_ "U_V713AV_MY2022_Rx" SG_ 995 PersIndexBcm_D_Actl 1;
BA_ "U_P708_MY2023_Rx" SG_ 995 PersIndexBcm_D_Actl 1;
BA_ "U_V710_MY2023_Rx" SG_ 995 PersIndexBcm_D_Actl 1;
BA_ "U_P702_MY2024_Rx" SG_ 995 PersIndexBcm_D_Actl 1;
BA_ "U_V713N_MY2022_Rx" SG_ 995 FeatNoBcm_No_Actl 1;
BA_ "U_V713AV_MY2022_Rx" SG_ 995 FeatNoBcm_No_Actl 1;
BA_ "U_P708_MY2023_Rx" SG_ 995 FeatNoBcm_No_Actl 1;
BA_ "U_V710_MY2023_Rx" SG_ 995 FeatNoBcm_No_Actl 1;
BA_ "U_P702_MY2024_Rx" SG_ 995 FeatNoBcm_No_Actl 1;
BA_ "U_V713N_MY2022_Rx" SG_ 995 FeatConfigBcmActl 1;
BA_ "U_V713AV_MY2022_Rx" SG_ 995 FeatConfigBcmActl 1;
BA_ "U_P708_MY2023_Rx" SG_ 995 FeatConfigBcmActl 1;
BA_ "U_V710_MY2023_Rx" SG_ 995 FeatConfigBcmActl 1;
BA_ "U_P702_MY2024_Rx" SG_ 995 FeatConfigBcmActl 1;
BA_ "U_V710_MY2023_Rx" SG_ 995 LightAmbIntsty_No_Actl 1;
BA_ "U_P708_MY2023_Rx" SG_ 995 LightAmbIntsty_No_Actl 1;
BA_ "U_P702_MY2024_Rx" SG_ 995 LightAmbIntsty_No_Actl 1;
BA_ "U_V710_MY2023_Rx" SG_ 995 LightAmbColor_No_Actl 1;
BA_ "U_P708_MY2023_Rx" SG_ 995 LightAmbColor_No_Actl 1;
BA_ "U_P702_MY2024_Rx" SG_ 995 LightAmbColor_No_Actl 1;
BA_ "GenSigSendType" SG_ 753 RollCodeValet 3;
BA_ "U_V710_MY2023_Tx" SG_ 753 RollCodeValet 1;
BA_ "U_P708_MY2023_Tx" SG_ 753 RollCodeValet 1;
BA_ "U_P702_MY2024_Tx" SG_ 753 RollCodeValet 1;
BA_ "GenSigSendType" SG_ 1000 AHU_Bezel_Diag_St 3;
BA_ "U_P708_MY2023_Rx" SG_ 1000 AHU_Bezel_Diag_St 1;
BA_ "U_P702_MY2024_Rx" SG_ 1000 AHU_Bezel_Diag_St 1;
BA_ "U_V713N_MY2022_Tx" SG_ 1000 AHU_Bezel_Diag_St 1;
BA_ "U_V713AV_MY2022_Tx" SG_ 1000 AHU_Bezel_Diag_St 1;
BA_ "U_P708_MY2023_Tx" SG_ 1000 AHU_Bezel_Diag_St 1;
BA_ "U_V710_MY2023_Tx" SG_ 1000 AHU_Bezel_Diag_St 1;
BA_ "GenSigSendType" SG_ 1000 ThermalReduction_St 3;
BA_ "U_CDX74X_MY2024_Rx" SG_ 1000 ThermalReduction_St 1;
BA_ "U_V710_MY2023_Rx" SG_ 1000 ThermalReduction_St 1;
BA_ "U_V713N_MY2022_Tx" SG_ 1000 ThermalReduction_St 1;
BA_ "U_V713AV_MY2022_Tx" SG_ 1000 ThermalReduction_St 1;
BA_ "U_P708_MY2023_Tx" SG_ 1000 ThermalReduction_St 1;
BA_ "U_V710_MY2023_Tx" SG_ 1000 ThermalReduction_St 1;
BA_ "GenSigSendType" SG_ 1000 AHU_Shaker_St 3;
BA_ "U_P708_MY2023_Rx" SG_ 1000 AHU_Shaker_St 1;
BA_ "U_P702_MY2024_Rx" SG_ 1000 AHU_Shaker_St 1;
BA_ "U_V713N_MY2022_Tx" SG_ 1000 AHU_Shaker_St 1;
BA_ "U_V713AV_MY2022_Tx" SG_ 1000 AHU_Shaker_St 1;
BA_ "U_P708_MY2023_Tx" SG_ 1000 AHU_Shaker_St 1;
BA_ "U_V710_MY2023_Tx" SG_ 1000 AHU_Shaker_St 1;
BA_ "GenSigSendType" SG_ 1000 ACM_BeltminderAudioSt 3;
BA_ "U_P708_MY2023_Rx" SG_ 1000 ACM_BeltminderAudioSt 1;
BA_ "U_P702_MY2024_Rx" SG_ 1000 ACM_BeltminderAudioSt 1;
BA_ "U_V713N_MY2022_Tx" SG_ 1000 ACM_BeltminderAudioSt 1;
BA_ "U_V713AV_MY2022_Tx" SG_ 1000 ACM_BeltminderAudioSt 1;
BA_ "U_P708_MY2023_Tx" SG_ 1000 ACM_BeltminderAudioSt 1;
BA_ "U_V710_MY2023_Tx" SG_ 1000 ACM_BeltminderAudioSt 1;
BA_ "GenSigSendType" SG_ 1000 MyKeyVolumeLimitUp 3;
BA_ "U_P708_MY2023_Rx" SG_ 1000 MyKeyVolumeLimitUp 1;
BA_ "U_P702_MY2024_Rx" SG_ 1000 MyKeyVolumeLimitUp 1;
BA_ "U_V713N_MY2022_Tx" SG_ 1000 MyKeyVolumeLimitUp 1;
BA_ "U_V713AV_MY2022_Tx" SG_ 1000 MyKeyVolumeLimitUp 1;
BA_ "U_P708_MY2023_Tx" SG_ 1000 MyKeyVolumeLimitUp 1;
BA_ "U_V710_MY2023_Tx" SG_ 1000 MyKeyVolumeLimitUp 1;
BA_ "GenSigSendType" SG_ 1000 MyKeyVolumeLimitMode 3;
BA_ "U_P708_MY2023_Rx" SG_ 1000 MyKeyVolumeLimitMode 1;
BA_ "U_P702_MY2024_Rx" SG_ 1000 MyKeyVolumeLimitMode 1;
BA_ "U_V713N_MY2022_Tx" SG_ 1000 MyKeyVolumeLimitMode 1;
BA_ "U_V713AV_MY2022_Tx" SG_ 1000 MyKeyVolumeLimitMode 1;
BA_ "U_P708_MY2023_Tx" SG_ 1000 MyKeyVolumeLimitMode 1;
BA_ "U_V710_MY2023_Tx" SG_ 1000 MyKeyVolumeLimitMode 1;
BA_ "GenSigStartValue" SG_ 992 MsgCntrPersIndex_D_Rq 4;
BA_ "GenSigSendType" SG_ 992 MsgCntrPersIndex_D_Rq 3;
BA_ "U_P708_MY2023_Rx" SG_ 992 MsgCntrPersIndex_D_Rq 1;
BA_ "U_P702_MY2024_Rx" SG_ 992 MsgCntrPersIndex_D_Rq 1;
BA_ "U_V713N_MY2022_Tx" SG_ 992 MsgCntrPersIndex_D_Rq 1;
BA_ "U_V713AV_MY2022_Tx" SG_ 992 MsgCntrPersIndex_D_Rq 1;
BA_ "U_P708_MY2023_Tx" SG_ 992 MsgCntrPersIndex_D_Rq 1;
BA_ "U_V710_MY2023_Tx" SG_ 992 MsgCntrPersIndex_D_Rq 1;
BA_ "U_P702_MY2024_Tx" SG_ 992 MsgCntrPersIndex_D_Rq 1;
BA_ "GenSigSendType" SG_ 992 MsgCntrFeatConfigRq 3;
BA_ "U_P708_MY2023_Rx" SG_ 992 MsgCntrFeatConfigRq 1;
BA_ "U_P702_MY2024_Rx" SG_ 992 MsgCntrFeatConfigRq 1;
BA_ "U_V713N_MY2022_Tx" SG_ 992 MsgCntrFeatConfigRq 1;
BA_ "U_V713AV_MY2022_Tx" SG_ 992 MsgCntrFeatConfigRq 1;
BA_ "U_P708_MY2023_Tx" SG_ 992 MsgCntrFeatConfigRq 1;
BA_ "U_V710_MY2023_Tx" SG_ 992 MsgCntrFeatConfigRq 1;
BA_ "U_P702_MY2024_Tx" SG_ 992 MsgCntrFeatConfigRq 1;
BA_ "GenSigSendType" SG_ 992 MsgCntrFeatNoRq 3;
BA_ "U_P708_MY2023_Rx" SG_ 992 MsgCntrFeatNoRq 1;
BA_ "U_P702_MY2024_Rx" SG_ 992 MsgCntrFeatNoRq 1;
BA_ "U_V713N_MY2022_Tx" SG_ 992 MsgCntrFeatNoRq 1;
BA_ "U_V713AV_MY2022_Tx" SG_ 992 MsgCntrFeatNoRq 1;
BA_ "U_P708_MY2023_Tx" SG_ 992 MsgCntrFeatNoRq 1;
BA_ "U_V710_MY2023_Tx" SG_ 992 MsgCntrFeatNoRq 1;
BA_ "U_P702_MY2024_Tx" SG_ 992 MsgCntrFeatNoRq 1;
BA_ "GenSigSendType" SG_ 992 MsgCntrDsplyOp_D_Rq 3;
BA_ "U_P708_MY2023_Rx" SG_ 992 MsgCntrDsplyOp_D_Rq 1;
BA_ "U_P702_MY2024_Rx" SG_ 992 MsgCntrDsplyOp_D_Rq 1;
BA_ "U_V713N_MY2022_Tx" SG_ 992 MsgCntrDsplyOp_D_Rq 1;
BA_ "U_V713AV_MY2022_Tx" SG_ 992 MsgCntrDsplyOp_D_Rq 1;
BA_ "U_P708_MY2023_Tx" SG_ 992 MsgCntrDsplyOp_D_Rq 1;
BA_ "U_V710_MY2023_Tx" SG_ 992 MsgCntrDsplyOp_D_Rq 1;
BA_ "U_P702_MY2024_Tx" SG_ 992 MsgCntrDsplyOp_D_Rq 1;
VAL_ 935 CtaAlrtRight2_D_Stat 7 "NotUsed3" 6 "NotUsed2" 5 "NotUsed1" 4 "AlertZone4" 3 "AlertZone3" 2 "AlertZone2" 1 "AlertZone1" 0 "Off" ;
VAL_ 935 BttRight_D_Stat 7 "BTT5GFault" 6 "Disabled" 5 "Off" 4 "OffTemp" 3 "NotConnected" 2 "Pending" 1 "Connected" 0 "NotDetermined" ;
VAL_ 935 BttRight_D_RqDrv 3 "NotUsed" 2 "Request" 1 "NoRequest" 0 "Null" ;
VAL_ 935 CtaBrkRightMsgTxt_B_Rq 1 "Enable" 0 "Disable" ;
VAL_ 935 CtaRightBrkEnbl_B_Rq 1 "Enable" 0 "Disable" ;
VAL_ 935 CtaSnsRight_D_Stat 3 "Invalid" 2 "System_Failure" 1 "Blocked" 0 "Clear" ;
VAL_ 935 CtaAlrtRight_D_Stat 1 "On" 0 "Off" ;
VAL_ 935 CtaRight_D_Stat 7 "NotUsed_3" 6 "NotUsed_2" 5 "NotUsed_1" 4 "Invalid" 3 "Disabled" 2 "On" 1 "Trailer_Tow_Off" 0 "Off" ;
VAL_ 935 SodRight_D_Stat 7 "NotUsed_3" 6 "NotUsed_2" 5 "NotUsed_1" 4 "Invalid" 3 "Disabled" 2 "On" 1 "Trailer_Tow_Off" 0 "Off" ;
VAL_ 935 SodSnsRight_D_Stat 3 "Second_Warning_Audio" 2 "System_Failure" 1 "Blocked" 0 "Clear" ;
VAL_ 935 CtaRightBrkDecel_B_Rq 1 "Enable" 0 "Disable" ;
VAL_ 935 SodAlrtRight_D_Stat 3 "Bulb_Proveout" 2 "Flash" 1 "On" 0 "Off" ;
VAL_ 935 SodDetctRight_D_Stat 4 "Sensor_Blocked" 3 "Sensor_Fault" 2 "Flash_On" 1 "Alert_On" 0 "AlertOff_FlashOff_SensrClr" ;
VAL_ 934 CtaAlrtLeft2_D_Stat 7 "NotUsed3" 6 "NotUsed2" 5 "NotUsed1" 4 "AlertZone4" 3 "AlertZone3" 2 "AlertZone2" 1 "AlertZone1" 0 "Off" ;
VAL_ 934 BttLeft_D_Stat 7 "BTT5GFault" 6 "Disabled" 5 "Off" 4 "OffTemp" 3 "NotConnected" 2 "Pending" 1 "Connected" 0 "NotDetermined" ;
VAL_ 934 BttLeft_D_RqDrv 3 "NotUsed" 2 "Request" 1 "NoRequest" 0 "Null" ;
VAL_ 934 CtaBrkLeftMsgTxt_B_Rq 1 "Enable" 0 "Disable" ;
VAL_ 934 CtaLeftBrkDecel_B_Rq 1 "Enable" 0 "Disable" ;
VAL_ 934 CtaLeftBrkEnbl_B_Rq 1 "Enable" 0 "Disable" ;
VAL_ 934 CtaSnsLeft_D_Stat 3 "Invalid" 2 "System_Failure" 1 "Blocked" 0 "Clear" ;
VAL_ 934 SodDetctLeft_D_Stat 4 "Sensor_Blocked" 3 "Sensor_Fault" 2 "Flash_On" 1 "Alert_On" 0 "AlertOff_FlashOff_SensrClr" ;
VAL_ 934 CtaLeft_D_Stat 7 "NotUsed_3" 6 "NotUsed_2" 5 "NotUsed_1" 4 "Invalid" 3 "Disabled" 2 "On" 1 "Trailer_Tow_Off" 0 "Off" ;
VAL_ 934 CtaAlrtLeft_D_Stat 1 "On" 0 "Off" ;
VAL_ 934 SodLeft_D_Stat 7 "NotUsed_3" 6 "NotUsed_2" 5 "NotUsed_1" 4 "Invalid" 3 "Disabled" 2 "On" 1 "Trailer_Tow_Off" 0 "Off" ;
VAL_ 934 SodSnsLeft_D_Stat 3 "Second_Warning_Audio" 2 "System_Failure" 1 "Blocked" 0 "Clear" ;
VAL_ 934 SodAlrtLeft_D_Stat 3 "Bulb_Proveout" 2 "Flash" 1 "On" 0 "Off" ;
VAL_ 486 ResponseCode_No_Res 3 "NotUsed" 2 "Accepted" 1 "NotAccepted" 0 "Null" ;
VAL_ 486 ACU_ARAudioSource_Rsp 15 "iPod" 14 "USB" 13 "BTAudio" 0 "AmfmRadio" 1 "FrontDisc" 2 "SDARS_DAB" 3 "InDashCdChanger" 4 "VoiceRecogniser" 5 "TelematicUnit" 6 "BluetoothPhone" 7 "RearDisc" 8 "APIM" 9 "FrontAuxInput" 10 "Navigation" 11 "RearAux" 12 "NotReq" ;
VAL_ 486 ACU_AROperationType_Rsp 0 "Inactive" 1 "Requestaudioresource" 2 "Releaseaudioresource" 3 "Releaseallaudioresouces" 4 "Getresourceupdate" 5 "Getallresourceupdates" ;
VAL_ 486 ACU_ARReqstrSystem_Rsp 0 "FrontRequester" 1 "RearRequester" ;
VAL_ 486 ACU_ARResponse_Rsp 0 "Inactive" 1 "RequestAccepted" 2 "RequestAcceptedWoCtrl" 3 "RequestDenied" 4 "RessourceUpdateStatus" ;
VAL_ 486 ACU_ARReqstrPriority_Rp 0 "EmergencyServ" 1 "TelService" 2 "AutoAnswer" 3 "Ta" 4 "PttMutevoice" 5 "NavUserVoiceCmd" 6 "NavSysVoiceCmd" 7 "Radio" 8 "Disc" 9 "Alarm" 10 "Ptynews" 11 "Aux_ExtSource" 12 "MobileNavAndTelMute" 13 "ManualAudioMute" 14 "NotReq" ;
VAL_ 486 ACU_RUAudioSource_St 15 "iPod" 14 "USB" 13 "BTAudio" 0 "AmfmRadio" 1 "FrontDisc" 2 "SDARS_DAB" 3 "InDashCdChanger" 4 "VoiceRecogniser" 5 "TelematicUnit" 6 "BluetoothPhone" 7 "RearDisc" 8 "APIM" 9 "FrontAuxInput" 10 "Navigation" 11 "RearAux" 12 "NotReq" ;
VAL_ 486 ACU_RUReqstrSystem_St 0 "FrontRequester" 1 "RearRequester" ;
VAL_ 486 ACU_RUResReqstStatus_St 0 "NoResourceupdate" 1 "Deallocated" 2 "Allocated" 3 "Stacked" 4 "Granted" 5 "GrantedNoControlOfAudioSrc" ;
VAL_ 486 ACU_RUReqstrPriority_St 0 "EmergencyServ" 1 "TelService" 2 "AutoAnswer" 3 "Ta" 4 "PttMutevoice" 5 "NavUserVoiceCmd" 6 "NavSysVoiceCmd" 7 "Radio" 8 "Disc" 9 "Alarm" 10 "Ptynews" 11 "Aux_ExtSource" 12 "MobileNavAndTelMute" 13 "ManualAudioMute" 14 "NotReq" ;
VAL_ 553 CCOI_PolicyClient_St 15 "NotUsed_4" 14 "NotUsed_3" 13 "NotUsed_2" 12 "NotUsed_1" 11 "DataStorageError" 10 "StateMachineInconsistent" 9 "UnrecoverableSyncError" 8 "OnBoardSyncFailed" 7 "OnBoardImplemented" 6 "OnBoardSynchronized" 5 "OnBoardSynchronizing" 4 "OnBoardSyncNeeded" 3 "OffBoardUpdatePending" 2 "OnBoardUpdatePending" 1 "Waiting" 0 "Null" ;
VAL_ 553 ResetAvgFe_B_Rq 1 "Reset" 0 "Null" ;
VAL_ 553 ResetTrip2_B_Rq 1 "Reset" 0 "Null" ;
VAL_ 553 DistToChrgrBynd_L_Actl 511 "Faulty" 510 "NoDataExists" ;
VAL_ 553 SndImmrsnLvl_D_Rq 255 "NotUsed_127" 254 "NotUsed_126" 253 "NotUsed_125" 252 "NotUsed_124" 251 "NotUsed_123" 250 "NotUsed_122" 249 "NotUsed_121" 248 "NotUsed_120" 247 "NotUsed_119" 246 "NotUsed_118" 245 "NotUsed_117" 244 "NotUsed_116" 243 "NotUsed_115" 242 "NotUsed_114" 241 "NotUsed_113" 240 "NotUsed_112" 239 "NotUsed_111" 238 "NotUsed_110" 237 "NotUsed_109" 236 "NotUsed_108" 235 "NotUsed_107" 234 "NotUsed_106" 233 "NotUsed_105" 232 "NotUsed_104" 231 "NotUsed_103" 230 "NotUsed_102" 229 "NotUsed_101" 228 "NotUsed_100" 227 "NotUsed_99" 226 "NotUsed_98" 225 "NotUsed_97" 224 "NotUsed_96" 223 "NotUsed_95" 222 "NotUsed_94" 221 "NotUsed_93" 220 "NotUsed_92" 219 "NotUsed_91" 218 "NotUsed_90" 217 "NotUsed_89" 216 "NotUsed_88" 215 "NotUsed_87" 214 "NotUsed_86" 213 "NotUsed_85" 212 "NotUsed_84" 211 "NotUsed_83" 210 "NotUsed_82" 209 "NotUsed_81" 208 "NotUsed_80" 207 "NotUsed_79" 206 "NotUsed_78" 205 "NotUsed_77" 204 "NotUsed_76" 203 "NotUsed_75" 202 "NotUsed_74" 201 "NotUsed_73" 200 "NotUsed_72" 199 "NotUsed_71" 198 "NotUsed_70" 197 "NotUsed_69" 196 "NotUsed_68" 195 "NotUsed_67" 194 "NotUsed_66" 193 "NotUsed_65" 192 "NotUsed_64" 191 "NotUsed_63" 190 "NotUsed_62" 189 "NotUsed_61" 188 "NotUsed_60" 187 "NotUsed_59" 186 "NotUsed_58" 185 "NotUsed_57" 184 "NotUsed_56" 183 "NotUsed_55" 182 "NotUsed_54" 181 "NotUsed_53" 180 "NotUsed_52" 179 "NotUsed_51" 178 "NotUsed_50" 177 "NotUsed_49" 176 "NotUsed_48" 175 "NotUsed_47" 174 "NotUsed_46" 173 "NotUsed_45" 172 "NotUsed_44" 171 "NotUsed_43" 170 "NotUsed_42" 169 "NotUsed_41" 168 "NotUsed_40" 167 "NotUsed_39" 166 "NotUsed_38" 165 "NotUsed_37" 164 "NotUsed_36" 163 "NotUsed_35" 162 "NotUsed_34" 161 "NotUsed_33" 160 "NotUsed_32" 159 "NotUsed_31" 158 "NotUsed_30" 157 "NotUsed_29" 156 "NotUsed_28" 155 "NotUsed_27" 154 "NotUsed_26" 153 "NotUsed_25" 152 "NotUsed_24" 151 "NotUsed_23" 150 "NotUsed_22" 149 "NotUsed_21" 148 "NotUsed_20" 147 "NotUsed_19" 146 "NotUsed_18" 145 "NotUsed_17" 144 "NotUsed_16" 143 "NotUsed_15" 142 "NotUsed_14" 141 "NotUsed_13" 140 "NotUsed_12" 139 "NotUsed_11" 138 "NotUsed_10" 137 "NotUsed_9" 136 "NotUsed_8" 135 "NotUsed_7" 134 "NotUsed_6" 133 "NotUsed_5" 132 "NotUsed_4" 131 "NotUsed_3" 130 "NotUsed_2" 129 "NotUsed_1" 128 "Level127" 127 "Level126" 126 "Level125" 125 "Level124" 124 "Level123" 123 "Level122" 122 "Level121" 121 "Level120" 120 "Level119" 119 "Level118" 118 "Level117" 117 "Level116" 116 "Level115" 115 "Level114" 114 "Level113" 113 "Level112" 112 "Level111" 111 "Level110" 110 "Level109" 109 "Level108" 108 "Level107" 107 "Level106" 106 "Level105" 105 "Level104" 104 "Level103" 103 "Level102" 102 "Level101" 101 "Level100" 100 "Level99" 99 "Level98" 98 "Level97" 97 "Level96" 96 "Level95" 95 "Level94" 94 "Level93" 93 "Level92" 92 "Level91" 91 "Level90" 90 "Level89" 89 "Level88" 88 "Level87" 87 "Level86" 86 "Level85" 85 "Level84" 84 "Level83" 83 "Level82" 82 "Level81" 81 "Level80" 80 "Level79" 79 "Level78" 78 "Level77" 77 "Level76" 76 "Level75" 75 "Level74" 74 "Level73" 73 "Level72" 72 "Level71" 71 "Level70" 70 "Level69" 69 "Level68" 68 "Level67" 67 "Level66" 66 "Level65" 65 "Level64" 64 "Level63" 63 "Level62" 62 "Level61" 61 "Level60" 60 "Level59" 59 "Level58" 58 "Level57" 57 "Level56" 56 "Level55" 55 "Level54" 54 "Level53" 53 "Level52" 52 "Level51" 51 "Level50" 50 "Level49" 49 "Level48" 48 "Level47" 47 "Level46" 46 "Level45" 45 "Level44" 44 "Level43" 43 "Level42" 42 "Level41" 41 "Level40" 40 "Level39" 39 "Level38" 38 "Level37" 37 "Level36" 36 "Level35" 35 "Level34" 34 "Level33" 33 "Level32" 32 "Level31" 31 "Level30" 30 "Level29" 29 "Level28" 28 "Level27" 27 "Level26" 26 "Level25" 25 "Level24" 24 "Level23" 23 "Level22" 22 "Level21" 21 "Level20" 20 "Level19" 19 "Level18" 18 "Level17" 17 "Level16" 16 "Level15" 15 "Level14" 14 "Level13" 13 "Level12" 12 "Level11" 11 "Level10" 10 "Level9" 9 "Level8" 8 "Level7" 7 "Level6" 6 "Level5" 5 "Level4" 4 "Level3" 3 "Level2" 2 "Level1" 1 "Level0" 0 "Inactive" ;
VAL_ 553 InfoSysMasterPw_D_Stat 7 "NotUsed_6" 6 "NotUsed_5" 5 "NotUsed_4" 4 "NotUsed_3" 0 "Inactive" 1 "On" 2 "NotUsed_1" 3 "NotUsed_2" ;
VAL_ 553 ResetTrip1_B_Rq 1 "Reset" 0 "Null" ;
VAL_ 553 Disp_LangSel2_St 33 "Ukrainian" 32 "Indian_English" 31 "Thai" 30 "Slovak" 29 "Arabic" 28 "Taiwanese" 27 "Mandarin_Chinese" 26 "Korean" 25 "AU_English" 24 "Japanese" 23 "Braz_Portuguese" 22 "EU_Portuguese" 21 "Finish" 20 "Norwegian" 19 "Danish" 18 "Swedish" 17 "Hungarian" 16 "Greek" 15 "Czech" 14 "Polish" 13 "Flemish" 12 "Dutch" 11 "Russian" 10 "Turkish" 9 "Mex_Spanish" 8 "EU_Spanish" 7 "Cana_French" 6 "EU_French" 5 "Italian" 4 "German" 3 "NA_English" 2 "UK_English" 1 "Unknown" 0 "Invalid" ;
VAL_ 553 Disp_LangSel_St 31 "Thai" 30 "Slovak" 29 "Arabic" 28 "Taiwanese" 27 "Mandarin_Chinese" 26 "Korean" 25 "AU_English" 24 "Japanese" 23 "Braz_Portuguese" 22 "EU_Portuguese" 21 "Finish" 20 "Norwegian" 19 "Danish" 18 "Swedish" 17 "Hungarian" 16 "Greek" 15 "Czech" 14 "Polish" 13 "Flemish" 12 "Dutch" 11 "Russian" 10 "Turkish" 9 "Mex_Spanish" 8 "EU_Spanish" 7 "Cana_French" 6 "EU_French" 5 "Italian" 4 "German" 3 "NA_English" 2 "UK_English" 1 "Unknown" 0 "Invalid" ;
VAL_ 553 Diagnostic_Operation_Rq 7 "SignalStrength" 6 "SDARSESNNumber" 5 "SpeakerWalkAround" 4 "CalibrationPartNumber" 15 "Reserved" 3 "HardwarePartNumber" 2 "SoftwarePartNumber" 1 "GetAllBackgroundDiagRq" 0 "Inactive" ;
VAL_ 553 Bezel_Diag_Module_Rq 15 "Reserved" 3 "EFP" 2 "DSP_AMP" 1 "AHU" 0 "Inactive" ;
VAL_ 553 Audio_Demo_CMND 2 "On" 1 "Off" 0 "Inactive" ;
VAL_ 553 Audio_Visualizer 2 "On" 1 "Off" 0 "Inactive" ;
VAL_ 553 Surround_Sound_Upmix 2 "Surround" 1 "Stereo" 0 "Inactive" ;
VAL_ 553 Bezel_Diag_State_Rq 1 "Active" 0 "Inactive" ;
VAL_ 553 SurndSndUpmix2_D_Rq 4 "Audience" 3 "On_Stage" 2 "Surround" 1 "Stereo" 0 "Inactive" ;
VAL_ 739 VgfSet_D_Stat 3 "NotUsed" 2 "On" 1 "Off" 0 "Null" ;
VAL_ 739 OnbTrgtSocOvrrd_D_Rq 3 "NotUsed" 2 "Enable" 1 "Disable" 0 "Null" ;
VAL_ 739 BptDly_T_RqMnu 63 "Faulty" 62 "NoDataExists" ;
VAL_ 739 BptMnSoc_L_RqMnu 8191 "Faulty" 8190 "NoDataExists" ;
VAL_ 739 BptStrtStop_D_RqMnu 3 "NotUsed_1" 2 "Start" 1 "Stop" 0 "NoRequest" ;
VAL_ 739 BptMde_D_RqMnu 7 "NotUsed_4" 6 "NotUsed_3" 5 "NotUsed_2" 4 "NotUsed_1" 3 "Automatic" 2 "Manual" 1 "Off" 0 "Null" ;
VAL_ 739 VehHornOccAlrt_D_Stat 3 "NotUsed" 2 "On" 1 "Off" 0 "Null" ;
VAL_ 739 SeatOccRear_D_Stat 3 "NotUsed" 2 "On" 1 "Off" 0 "Null" ;
VAL_ 739 BabySeatInUse_D_Stat 3 "NotUsed" 2 "InUse" 1 "NotInUse" 0 "Null" ;
VAL_ 739 SeatOccChime_B_RqCancl 1 "Cancel" 0 "Null" ;
VAL_ 739 EngExhMdeHrStrt_D_Rq 31 "NotUsed_7" 30 "NotUsed_6" 29 "NotUsed_5" 28 "NotUsed_4" 27 "NotUsed_3" 26 "NotUsed_2" 25 "NotUsed_1" 24 "Hour23_11pm" 23 "Hour22_10pm" 22 "Hour21_9pm" 21 "Hour20_8pm" 20 "Hour19_7pm" 19 "Hour18_6pm" 18 "Hour17_5pm" 17 "Hour16_4pm" 16 "Hour15_3pm" 15 "Hour14_2pm" 14 "Hour13_1pm" 13 "Hour12_12pm" 12 "Hour11_11am" 11 "Hour10_10am" 10 "Hour9_9am" 9 "Hour8_8am" 8 "Hour7_7am" 7 "Hour6_6am" 6 "Hour5_5am" 5 "Hour4_4am" 4 "Hour3_3am" 3 "Hour2_2am" 2 "Hour1_1am" 1 "Hour0_12am" 0 "Null" ;
VAL_ 739 EngExhMdeHrEnd_D_Rq 31 "NotUsed_7" 30 "NotUsed_6" 29 "NotUsed_5" 28 "NotUsed_4" 27 "NotUsed_3" 26 "NotUsed_2" 25 "NotUsed_1" 24 "Hour23_11pm" 23 "Hour22_10pm" 22 "Hour21_9pm" 21 "Hour20_8pm" 20 "Hour19_7pm" 19 "Hour18_6pm" 18 "Hour17_5pm" 17 "Hour16_4pm" 16 "Hour15_3pm" 15 "Hour14_2pm" 14 "Hour13_1pm" 13 "Hour12_12pm" 12 "Hour11_11am" 11 "Hour10_10am" 10 "Hour9_9am" 9 "Hour8_8am" 8 "Hour7_7am" 7 "Hour6_6am" 6 "Hour5_5am" 5 "Hour4_4am" 4 "Hour3_3am" 3 "Hour2_2am" 2 "Hour1_1am" 1 "Hour0_12am" 0 "Null" ;
VAL_ 739 EngExhMdeHrEnbl_D_Rq 3 "NotConfigured" 2 "Enabled" 1 "Disabled" 0 "Null" ;
VAL_ 739 Partial_Amp_Shutdown 1 "Active" 0 "Inactive" ;
VAL_ 739 HMI_HMIMode_St 7 "NotUsed2" 6 "NotUsed1" 5 "Load_Shed_Active" 0 "Invalid" 1 "OffMode" 2 "On" 3 "Phone" 4 "Climate" ;
VAL_ 1009 ChrgCordUnlock_B_Rq 1 "Request" 0 "NoRequest" ;
VAL_ 1009 AutoHoldSwtch_D_Stat3 3 "Faulty" 2 "NotUsed" 1 "Pressed" 0 "Not_Pressed" ;
VAL_ 1009 TrlrTrgtAcquire_D_Rq 7 "NotUsed_2" 6 "NotUsed_1" 5 "ActivateRVCforTBA" 4 "CancelAcquisition" 3 "RetryAcquisition" 2 "AcquisitionSuccessful" 1 "StartAcquisition" 0 "Inactive" ;
VAL_ 1009 RearAudioCtlLck_D_Rq 2 "Unlock" 1 "Lock" 0 "Null" ;
VAL_ 1009 TrlrAidCancl_B_Rq 1 "Cancel" 0 "Null" ;
VAL_ 1009 CenterStackRing_D_Actl 3 "LimitedOn" 2 "On" 1 "Off" 0 "Null" ;
VAL_ 1009 ValetMode_D_Stat 3 "NotUsed" 2 "On" 1 "Off" 0 "Null" ;
VAL_ 1009 TrlrAidSetup_D_Stat 7 "Faulty" 6 "NotUsed_3" 5 "NotUsed_2" 4 "NotUsed_1" 3 "EnterParameters" 2 "EndSetup" 1 "BeginSetup" 0 "Null" ;
VAL_ 531 VehStop_D_Stat 3 "Faulty" 2 "NoDataExists" 1 "Yes" 0 "No" ;
VAL_ 531 TracCtlPtActv_B_Actl 1 "Active" 0 "Inactive" ;
VAL_ 531 PrkBrkYwLamp_D_Rq 3 "Fast_Flash" 2 "Slow_Flash" 1 "On" 0 "Off" ;
VAL_ 531 PrkBrkRedLamp_D_Rq 3 "Fast_Flash" 2 "Slow_Flash" 1 "On" 0 "Off" ;
VAL_ 531 PrkBrkMsgTxt_D_Rq 15 "Message15" 14 "Message14" 13 "Message13" 12 "Message12" 11 "Message11" 10 "Message10" 9 "Message9" 8 "Message8" 7 "Message7" 6 "Message6" 5 "Message5" 4 "Message4" 3 "Message3" 2 "Message2" 1 "Message1" 0 "No_Message" ;
VAL_ 531 PrkBrkStatus 7 "GeneralFault_MaintenceMode" 6 "ECD_by_Brake_ECU_Active" 5 "EPB_Limphome_Active" 4 "Rear_Caliper_Open" 3 "RWU_By_EPB_Active" 2 "Rear_Caliper_Transition" 1 "Rear_Caliper_Closed" 0 "Not_Supported" ;
VAL_ 531 LscmbbMntr_B_Err 1 "DisplayMessage" 0 "NoMessage" ;
VAL_ 531 LscmbbBrkDis_B_Actl 1 "Yes" 0 "No" ;
VAL_ 531 StabCtlBrkActv_B_Actl 1 "Yes" 0 "No" ;
VAL_ 531 CmbbBrkPrchg_B_Actl 1 "Yes" 0 "No" ;
VAL_ 531 CmbbBrkDecel_B_Actl 1 "Yes" 0 "No" ;
VAL_ 531 CmbbBaSensInc_B_Actl 1 "Yes" 0 "No" ;
VAL_ 531 AccBrkWarm_B_Actl 1 "Yes" 0 "No" ;
VAL_ 531 AccBrkTotTqMn_B_Actl 1 "Yes" 0 "No" ;
VAL_ 531 AccBrkPrchgActv_B_Actl 1 "Yes" 0 "No" ;
VAL_ 531 AccBrkDis_B_Actl 1 "Yes" 0 "No" ;
VAL_ 531 AccBrkDeny_B_Actl 1 "Yes" 0 "No" ;
VAL_ 531 AccBrkActv_B_Actl 1 "Yes" 0 "No" ;
VAL_ 531 PrplDrgCtlActv_B_Actl 1 "Active" 0 "Inactive" ;
VAL_ 531 AbsActv_B_Actl 1 "Yes" 0 "No" ;
VAL_ 531 CmbbBrkDis_B_Actl 1 "Yes" 0 "No" ;
VAL_ 531 CmbbDeny_B_ActlBrk 1 "Yes" 0 "No" ;
VAL_ 531 CcDis_B_Cmd 1 "Yes" 0 "No" ;
VAL_ 531 VehLongOvrGnd_A_Est 1023 "Fault" 1022 "Unknown" ;
VAL_ 531 AccStopActv_B_ActlBrk 1 "Yes" 0 "No" ;
VAL_ 531 AccDis_B_ActlEpb 1 "Yes" 0 "No" ;
VAL_ 531 LscmbbDeny_B_ActlBrk 1 "Yes" 0 "No" ;
VAL_ 531 LscmbbBrkDecel_B_Actl 1 "Yes" 0 "No" ;
VAL_ 531 LscmbbBaSensInc_B_Actl 1 "Yes" 0 "No" ;
VAL_ 531 LscmbBrkPrchg_B_Actl 1 "Active" 0 "Inactive" ;
VAL_ 531 VehicleStationary 1 "Yes" 0 "No" ;
VAL_ 549 BattTracLoThres_D_Rq2 7 "NotUsed" 6 "Thres80km_50mi" 5 "Thres50km_31mi" 4 "Thres30km_18mi" 3 "Thres50mi_80km" 2 "Thres30mi_48km" 1 "Thres20mi_32km" 0 "Null" ;
VAL_ 549 NavIod_D_Rq 7 "NotUsed_5" 6 "NotUsed_4" 5 "NotUsed_3" 4 "NotUsed_2" 3 "NotUsed_1" 2 "ModeChange" 1 "VideoOutput" 0 "NoRequest" ;
VAL_ 549 StrtInGearOk_D_Stat 3 "NotUsed" 2 "Accepted" 1 "NotAccepted" 0 "Null" ;
VAL_ 549 WwaActv_B_Stat 1 "Active" 0 "Inactive" ;
VAL_ 549 IPC_MyKeyVolLimit_St 0 "Invalid" 1 "Off" 2 "On" ;
VAL_ 549 HudVertSzMnuOn_B_Rq 1 "On" 0 "Off" ;
VAL_ 549 HudVertMnuOn_B_Rq 1 "Yes" 0 "No" ;
VAL_ 549 HudRotatMnuOn_B_Rq 1 "Yes" 0 "No" ;
VAL_ 549 HudCntntMnuOn_B_Rq 1 "On" 0 "Off" ;
VAL_ 549 HudBrightMnuOn_B_Rq 1 "Yes" 0 "No" ;
VAL_ 549 HdcOn_B_Rq 1 "On" 0 "Off" ;
VAL_ 549 IPC_Attn_Info_Audio 7 "Unknown" 6 "Attenuation_6" 5 "Attenuation_5" 4 "Attenuation_4" 3 "Attenuation_3" 2 "Attenuation_2" 1 "Attenuation_1" 0 "No_Attenuation_of_Audio" ;
VAL_ 549 BeltminderAudioMute 2 "On" 1 "Off" 0 "Invalid" ;
VAL_ 549 Power_Up_Chime_Modules 1 "Active" 0 "Inactive" ;
VAL_ 549 Chime_Source 2 "Cluster" 1 "Infotainment_Sys" 0 "Invalid" ;
VAL_ 549 TjaLcEnbl_D_DrvRq 0 "Inactive" 1 "Off" 2 "On" 3 "NotUsed" ;
VAL_ 549 CCOI_PolicyClient_St2 15 "NotUsed_4" 14 "NotUsed_3" 13 "NotUsed_2" 12 "NotUsed_1" 11 "DataStorageError" 10 "StateMachineInconsistent" 9 "UnrecoverableSyncError" 8 "OnBoardSyncFailed" 7 "OnBoardImplemented" 6 "OnBoardSynchronized" 5 "OnBoardSynchronizing" 4 "OnBoardSyncNeeded" 3 "OffBoardUpdatePending" 2 "OnBoardUpdatePending" 1 "Waiting" 0 "Null" ;
VAL_ 549 FactoryReset_Rq2 1 "ResetFactoryDefaults" 0 "Inactive" ;
VAL_ 549 IPC_New_Attn_Event 1 "Active" 0 "Inactive" ;
VAL_ 549 MetricActv_B_Dsply 1 "Active" 0 "Inactive" ;
VAL_ 765 BalrSwtch_D_Stat 3 "NotUsed" 2 "Pressed" 1 "NotPressed" 0 "Null" ;
VAL_ 765 BalrMde_D_Rq 3 "High" 2 "Medium" 1 "Low" 0 "Null" ;
VAL_ 765 RstrnOnPsngr_D_RqMnu 15 "Faulty" 14 "NotUsed_11" 13 "NotUsed_10" 12 "ConfiguredOff" 11 "NotUsed_9" 10 "On" 9 "NotUsed_8" 8 "NotUsed_7" 7 "NotUsed_6" 6 "NotUsed_5" 5 "Off" 4 "NotUsed_4" 3 "NotUsed_3" 2 "NotUsed_2" 1 "NotUsed_1" 0 "NoAction" ;
VAL_ 765 WaitToStartLamp_D_Falt 3 "NotUsed" 2 "Wait_to_start_lamp_failed" 1 "Diagnosis_not_ready" 0 "Wait_to_start_lamp_OK" ;
VAL_ 765 EsaOn_B_Rq 1 "On" 0 "Off" ;
VAL_ 765 BttOn_B_Rq 1 "On" 0 "Off" ;
VAL_ 765 Btt_L_Actl 127 "Faulty" 126 "NoDataExists" ;
VAL_ 765 RearDiffLck_D_RqArb 3 "Faulty" 2 "NotUsed" 1 "On" 0 "Off" ;
VAL_ 765 AwdMde_D_RqArb 7 "Faulty" 6 "NotUsed2" 5 "NoRequest" 4 "Neutral" 3 "FourByFourLow" 2 "FourByFourHigh" 1 "FourByFourAuto" 0 "FourByTwo" ;
VAL_ 765 SelDrvMdeTxtReset_B_Rq 1 "Yes" 0 "No" ;
VAL_ 765 AutoTowAllw_D_RqMnu 3 "TowHaulCommandedOn" 2 "AutoTowHaulEnabled" 1 "AutoTowHaulDisabled" 0 "NoSelection" ;
VAL_ 765 DrvInputRequired_B_Rq 1 "Yes" 0 "No" ;
VAL_ 765 SelDrvMdeDsply_B_Avail 1 "Available" 0 "NotAvailable" ;
VAL_ 765 EngExhMdeQuiet_D_Rq 3 "Faulty" 2 "QuietExhaust" 1 "LoudExhaust" 0 "Null" ;
VAL_ 765 AirSusp_D_RqDrv 3 "NotUsed" 2 "On" 1 "Off" 0 "NoModeSelected" ;
VAL_ 765 Mc_VehUntTrpCoUsrSel_St 0 "TripComputer_metric" 1 "TripComputer_imperial" ;
VAL_ 765 Mc_VehUnitTempUsrSel_St 0 "Temperature_deg_c" 1 "Temperature_deg_f" ;
VAL_ 765 Mc_VehDayNightUsrSel_St 2 "Night" 1 "Day" 0 "Invalid" ;
VAL_ 765 Mc_VehTimeFrmtUsrSel_St 2 "24h_mode" 1 "12h_mode" 0 "Invalid" ;
VAL_ 765 Mc_VehThemeUsrSel_St 2 "Theme_2" 1 "Theme_1" 0 "Invalid" ;
VAL_ 765 Mc_VehLangUsrSel_St 33 "Ukrainian" 32 "Indian_English" 31 "Thai" 30 "Slovak" 29 "Arabic" 28 "Taiwanese" 27 "Mandarin_Chinese" 26 "Korean" 25 "AU_English" 24 "Japanese" 23 "Braz_Portuguese" 22 "EU_Portuguese" 21 "Finish" 20 "Norwegian" 19 "Danish" 18 "Swedish" 17 "Hungarian" 16 "Greek" 15 "Czech" 14 "Polish" 13 "Flemish" 12 "Dutch" 11 "Russian" 10 "Turkish" 9 "Mex_Spanish" 8 "EU_Spanish" 7 "Cana_French" 6 "EU_French" 5 "Italian" 4 "German" 3 "NA_English" 2 "UK_English" 1 "Unknown" 0 "Invalid" ;
VAL_ 765 AwdRnge_D_ActlIpc 7 "Unknown" 6 "High_Range_2wd" 5 "High_Range_Auto" 4 "High_Range_Locked" 3 "Neutral" 2 "Low_Range_2wd" 1 "Low_Range_Auto" 0 "Low_Range_Locked" ;
VAL_ 765 AwdDrvMde_D_Rq 7 "Faulty" 6 "NotAvailable" 5 "RockCrawl" 4 "Baja" 3 "MudAndSand" 2 "Weather" 1 "Sport" 0 "Normal" ;
VAL_ 765 EngExhMdeQuiet_D2_Rq 7 "NotUsed_3" 6 "NotUsed_2" 5 "NotUsed_1" 4 "Track" 3 "Sport" 2 "Normal" 1 "Stealth" 0 "Null" ;
VAL_ 765 BrkLineLck_D_Rq 3 "Off" 2 "Engage" 1 "Initiate" 0 "NoRequest" ;
VAL_ 765 EdmSailMde_B_RqDrv 1 "On" 0 "Off" ;
VAL_ 765 Running_Board_Cmd 3 "Unused" 2 "Manually_Deployed" 1 "All_Enabled" 0 "All_Disabled" ;
VAL_ 508 Mc_DB1GtInfNbrOfItms_Rq 1 "OneItem" 0 "Standard" ;
VAL_ 508 Mc_DB1GetInfSetConf_Rq 31 "UnknownActive" 30 "Reserved_last" 9 "Reserved" 8 "Podcast" 7 "Audiobook" 6 "Composer" 5 "Track" 4 "Genre" 3 "Album" 2 "Artist" 1 "Playlist" 0 "Root" ;
VAL_ 508 Mc_DB1GetInfSetFilt3_Rq 1023 "All" 1022 "SIIndex_1022" 1 "SIIndex_1" 0 "NotEngaged" ;
VAL_ 508 Mc_DB1GetInfSetFilt2_Rq 65535 "All" 65534 "SIIndex_65534" 1 "SIIndex_1" 0 "NotEngaged" ;
VAL_ 508 Mc_DB1GetInfSetFilt1_Rq 65535 "All" 65534 "SIIndex_65534" 1 "SIIndex_1" 0 "NotEngaged" ;
VAL_ 507 Mc_DB1SetTrkSetConf_Rq 9 "Reserved" 8 "Podcast" 7 "Audiobook" 6 "Composer" 5 "Track" 4 "Genre" 3 "Album" 2 "Artist" 1 "Playlist" 0 "Root" 31 "UnknownActive" 30 "Reserved_last" ;
VAL_ 507 Mc_DB1SetTrkSetFilt3_Rq 1023 "All" 1022 "SIIndex_1022" 1 "SIIndex_1" 0 "NotEngaged" ;
VAL_ 507 Mc_DB1SetTrkSetFilt2_Rq 65535 "All" 65534 "SIIndex_65534" 1 "SIIndex_1" 0 "NotEngaged" ;
VAL_ 507 Mc_DB1SetTrkSetFilt1_Rq 65535 "All" 65534 "SIIndex_65534" 1 "SIIndex_1" 0 "NotEngaged" ;
VAL_ 506 Mc_AudioSourceSel3_Rq 4 "Reserved" 5 "SDcard" 3 "USB" 2 "BTAudio" 1 "CD" 0 "Inactive" ;
VAL_ 505 Mc_AudioSourceSel2_Rq 4 "Reserved" 5 "SDcard" 3 "USB" 2 "BTAudio" 1 "CD" 0 "Inactive" ;
VAL_ 505 Mc_CutItem2_Rq 3 "Inactive" 2 "ThreeQuarterFromBeginOneQ" 1 "End" 0 "Beginning" ;
VAL_ 505 Mc_FolderContent_Rq 2 "Inactive" 1 "ReqContentParentFolderOf" 0 "ReqContentParameterFolder" ;
VAL_ 403 McLangSel2_Rq 33 "Ukrainian" 32 "Indian_English" 31 "Thai" 30 "Slovak" 29 "Arabic" 28 "Taiwanese" 27 "Mandarin_Chinese" 26 "Korean" 25 "AU_English" 24 "Japanese" 23 "Braz_Portuguese" 22 "EU_Portuguese" 21 "Finish" 20 "Norwegian" 19 "Danish" 18 "Swedish" 17 "Hungarian" 16 "Greek" 15 "Czech" 14 "Polish" 13 "Flemish" 12 "Dutch" 11 "Russian" 10 "Turkish" 9 "Mex_Spanish" 8 "EU_Spanish" 7 "Cana_French" 6 "EU_French" 5 "Italian" 4 "German" 3 "NA_English" 2 "UK_English" 1 "Unknown" 0 "Invalid" ;
VAL_ 403 DealerCall_B_Rq 1 "Yes" 0 "Null" ;
VAL_ 403 Mc_RepeatGuidance_Rq 1 "Active" 0 "Inactive" ;
VAL_ 403 Mc_CancelRoute_Rq 1 "Cancel" 0 "Inactive" ;
VAL_ 403 Mc_CancelCurrWaypt_Rq 1 "Cancel" 0 "Inactive" ;
VAL_ 403 Mc_TextMessage_Rq 3 "Cancel" 2 "Ignore" 1 "Listen" 0 "Invalid" ;
VAL_ 403 Mc_BTInCallOptions_Rq 6 "EndHoldCall" 5 "HoldCall" 4 "GotoHandsfreeMode" 3 "GotoPrivacyMode" 2 "JoinCalls" 1 "SwitchCalls" 0 "Inactive" ;
VAL_ 403 Mc_PhMicrophoneMute_Rq 3 "Reserved" 2 "MicrophoneUnmute" 1 "MicrophoneMute" 0 "Inactive" ;
VAL_ 403 Mc_LangSel_Rq 31 "Thai" 30 "Slovak" 29 "Arabic" 28 "Taiwanese" 27 "Mandarin_Chinese" 26 "Korean" 25 "AU_English" 24 "Japanese" 23 "Braz_Portuguese" 22 "EU_Portuguese" 21 "Finish" 20 "Norwegian" 19 "Danish" 18 "Swedish" 17 "Hungarian" 16 "Greek" 15 "Czech" 14 "Polish" 13 "Flemish" 12 "Dutch" 11 "Russian" 10 "Turkish" 9 "Mex_Spanish" 8 "EU_Spanish" 7 "Cana_French" 6 "EU_French" 5 "Italian" 4 "German" 3 "NA_English" 2 "UK_English" 1 "Unknown" 0 "Invalid" ;
VAL_ 401 Bezel_Beeps_Rq 0 "Inactive" 2 "Disable" 1 "Enable" ;
VAL_ 401 Disp_VehUntTripCoUsrSel 3 "Inactive" 1 "Imperial" 0 "Metric" ;
VAL_ 401 Disp_VehUnitTempUsrSel 3 "Inactive" 1 "Fahrenheit" 0 "Celsius" ;
VAL_ 401 Disp_LangSel_Rq 31 "Thai" 30 "Slovak" 29 "Arabic" 28 "Taiwanese" 27 "Mandarin_Chinese" 26 "Korean" 25 "AU_English" 24 "Japanese" 23 "Braz_Portuguese" 22 "EU_Portuguese" 21 "Finish" 20 "Norwegian" 19 "Danish" 18 "Swedish" 17 "Hungarian" 16 "Greek" 15 "Czech" 14 "Polish" 13 "Flemish" 12 "Dutch" 11 "Russian" 10 "Turkish" 9 "Mex_Spanish" 8 "EU_Spanish" 7 "Cana_French" 6 "EU_French" 5 "Italian" 4 "German" 3 "NA_English" 2 "UK_English" 1 "Unknown" 0 "Invalid" ;
VAL_ 401 Disp_LangSel2_Rq 33 "Ukrainian" 32 "Indian_English" 31 "Thai" 30 "Slovak" 29 "Arabic" 28 "Taiwanese" 27 "Mandarin_Chinese" 26 "Korean" 25 "AU_English" 24 "Japanese" 23 "Braz_Portuguese" 22 "EU_Portuguese" 21 "Finish" 20 "Norwegian" 19 "Danish" 18 "Swedish" 17 "Hungarian" 16 "Greek" 15 "Czech" 14 "Polish" 13 "Flemish" 12 "Dutch" 11 "Russian" 10 "Turkish" 9 "Mex_Spanish" 8 "EU_Spanish" 7 "Cana_French" 6 "EU_French" 5 "Italian" 4 "German" 3 "NA_English" 2 "UK_English" 1 "Unknown" 0 "Invalid" ;
VAL_ 1143 ConsTipUnitPt_D_Dsply 3 "NotUsed" 2 "FuelEconomy" 1 "Distance" 0 "Percentage" ;
VAL_ 1143 ConsTipTot_Pc_Dsply 1023 "Faulty" 1022 "NoDataExists" ;
VAL_ 1143 ChrgCompltMsgTxt_D_Rq 3 "NotUsed_1" 2 "ChargeToFull" 1 "ChargeToFastChargeLimit" 0 "DefaultLabel" ;
VAL_ 1142 ConsTipV_No_Dsply 1023 "Faulty" 1022 "NoDataExists" ;
VAL_ 1142 ConsTipMsg3_D_Dsply 15 "NotUsed10" 14 "NotUsed9" 13 "NotUsed8" 12 "NotUsed7" 11 "NotUsed6" 10 "NotUsed5" 9 "NotUsed4" 8 "NotUsed3" 7 "NotUsed2" 6 "NotUsed1" 5 "ReduceIdleTime" 4 "ClimateUsage" 3 "VehicleSpeed" 2 "Deceleration" 1 "Acceleration" 0 "NoDisplay" ;
VAL_ 1142 ConsTipMsg2_D_Dsply 15 "NotUsed10" 14 "NotUsed9" 13 "NotUsed8" 12 "NotUsed7" 11 "NotUsed6" 10 "NotUsed5" 9 "NotUsed4" 8 "NotUsed3" 7 "NotUsed2" 6 "NotUsed1" 5 "ReduceIdleTime" 4 "ClimateUsage" 3 "VehicleSpeed" 2 "Deceleration" 1 "Acceleration" 0 "NoDisplay" ;
VAL_ 1142 ConsTipMsg1_D_Dsply 15 "NotUsed10" 14 "NotUsed9" 13 "NotUsed8" 12 "NotUsed7" 11 "NotUsed6" 10 "NotUsed5" 9 "NotUsed4" 8 "NotUsed3" 7 "NotUsed2" 6 "NotUsed1" 5 "ReduceIdleTime" 4 "ClimateUsage" 3 "VehicleSpeed" 2 "Deceleration" 1 "Acceleration" 0 "NoDisplay" ;
VAL_ 1142 ConsTipDecel_No_Dsply 1023 "Faulty" 1022 "NoDataExists" ;
VAL_ 1142 ConsTipA_No_Dsply 1023 "Faulty" 1022 "NoDataExists" ;
VAL_ 973 PersCtaSplitView_D_Stat 3 "EnabledFull" 2 "Enabled_180SwitchOnly" 1 "Disabled" 0 "Null" ;
VAL_ 973 LaSysOffStat_D_Dsply 3 "Level_3" 2 "Level_2" 1 "Level_1" 0 "Level_0" ;
VAL_ 973 TsrVl1RstrcMsgTxt2_D_Rq 7 "NotUsed" 6 "Time" 5 "Trailer" 4 "Snow" 3 "RainWet" 2 "NoRecognizableRestrictn" 1 "NoSpeedLimitRestrictn" 0 "Null" ;
VAL_ 973 TsrVl2RstrcMsgTxt2_D_Rq 7 "NotUsed" 6 "Time" 5 "Trailer" 4 "Snow" 3 "RainWet" 2 "NoRecognizableRestrictn" 1 "NoSpeedLimitRestrictn" 0 "Null" ;
VAL_ 973 TsrVl2PrmntMsgTxt_D_Rq 3 "NotUsed" 2 "ShowPermanentlyWithSupp" 1 "ShowPermanentlyWithoutSupp" 0 "DoNotShowSignPermanent" ;
VAL_ 973 TsrVl1PrmntMsgTxt_D_Rq 3 "NotUsed" 2 "ShowPermanentlyWithSupp" 1 "ShowPermanentlyWithoutSupp" 0 "DoNotShowSignPermanent" ;
VAL_ 973 TsrOvtkMsgTxt2_D_Rq 15 "NotUsed5" 14 "NotUsed4" 13 "NotUsed3" 12 "NotUsed2" 11 "NotUsed1" 10 "LimForTrucksCancelled" 9 "LimForTrucksWoQlfdRstrc" 8 "LimForTrucksWithoutRstrc" 7 "LimAllCancelled" 6 "LimAllWithRstrcTime" 5 "LimAllWithRstrcTrailer" 4 "LimAllWithRstrcSnow" 3 "LimAllWithRstrcRain" 2 "LimAllWithoutQlfdRstrc" 1 "LimAllWithoutRestriction" 0 "OvertakingAllowed" ;
VAL_ 973 WwaWarn_B_Rq 1 "On" 0 "Off" ;
VAL_ 973 RoadSignRgltry_D_Dsply 3 "NoEntry" 2 "Stop" 1 "Yield" 0 "None" ;
VAL_ 973 TsrVlUnitMsgTxt_D_Rq 3 "NoDataExists" 2 "Mph" 1 "Kph" 0 "Null" ;
VAL_ 973 TsrVLim2MsgTxt_D_Rq 255 "NoLimit" 254 "NotUsed2" 253 "NotUsed1" 252 "NotToBeDisplayed" 251 "LimitCancelled" 31 "1F_FA_Message31_250" 30 "Message30" 29 "Message29" 28 "Message28" 27 "Message27" 26 "Message26" 25 "Message25" 24 "Message24" 23 "Message23" 22 "Message22" 21 "Message21" 20 "Message20" 19 "Message19" 18 "Message18" 17 "Message17" 16 "Message16" 15 "Message15" 14 "Message14" 13 "Message13" 12 "Message12" 11 "Message11" 10 "Message10" 9 "Message9" 8 "Message8" 7 "Message7" 6 "Message6" 5 "Message5" 4 "Message4" 3 "Message3" 2 "Message2" 1 "Message1" 0 "Null" ;
VAL_ 973 TsrVLim1MsgTxt_D_Rq 255 "NoLimit" 254 "NotUsed2" 253 "NotUsed1" 252 "NotToBeDisplayed" 251 "LimitCancelled" 31 "1F_FA_Message31_250" 30 "Message30" 29 "Message29" 28 "Message28" 27 "Message27" 26 "Message26" 25 "Message25" 24 "Message24" 23 "Message23" 22 "Message22" 21 "Message21" 20 "Message20" 19 "Message19" 18 "Message18" 17 "Message17" 16 "Message16" 15 "Message15" 14 "Message14" 13 "Message13" 12 "Message12" 11 "Message11" 10 "Message10" 9 "Message9" 8 "Message8" 7 "Message7" 6 "Message6" 5 "Message5" 4 "Message4" 3 "Message3" 2 "Message2" 1 "Message1" 0 "Null" ;
VAL_ 973 TsrVl2StatMsgTxt_D_Rq 3 "LimitOutdated" 2 "LimitReiable" 1 "LimitChanged" 0 "Null" ;
VAL_ 973 TsrVl2RstrcMsgTxt_D_Rq 3 "NotUsed" 2 "NoRecognizableRestriction" 1 "NoSpeedLimitRestriction" 0 "Null" ;
VAL_ 973 TsrVl1StatMsgTxt_D_Rq 3 "LimitOutdated" 2 "LimitReiable" 1 "LimitChanged" 0 "Null" ;
VAL_ 973 TsrVl1RstrcMsgTxt_D_Rq 3 "NotUsed" 2 "NoRecognizableRestriction" 1 "NoSpeedLimitRestriction" 0 "Null" ;
VAL_ 973 TsrStatMsgTxt_D_Rq 7 "NotUsed" 6 "NoDataExists" 5 "TSR_Error" 4 "Available_NavigationOnly" 3 "Available_CameraOnly" 2 "Available_FusionMode" 1 "TSR_Off" 0 "Null" ;
VAL_ 973 TsrOvtkStatMsgTxt_D_Rq 3 "LimitOutdated" 2 "LimitReiable" 1 "LimitChanged" 0 "Null" ;
VAL_ 973 TsrOvtkMsgTxt_D_Rq 7 "LimForTrucksCancelled" 6 "LimForTrucksWoQlfdRstrc" 5 "LimForTrucksWithoutRstrc" 4 "LimAllCancelled" 3 "LimAllWithoutQlfdRstrc" 2 "LimAllWithoutRestriction" 1 "OvertakingAllowed" 0 "Null" ;
VAL_ 973 TsrOswWarnMsgTxt_D_Rq 3 "NotUsed" 2 "True" 1 "False" 0 "Null" ;
VAL_ 973 TsrMsgTxt_D_Rq 15 "NotUsed6" 14 "NotUsed5" 13 "NotUsed4" 12 "NotUsed3" 11 "NotUsed2" 10 "NotUsed1" 9 "RecgnzdSignNotUsblForDsply" 8 "LimitedSystemPerformance" 7 "OffRoad" 6 "RegionNotSupported" 5 "CountryNotSupported" 4 "WrngNavDatIncompDatCarrier" 3 "NoNavDataAvailable" 2 "NoNavAvailableSwitchedOff" 1 "NoInformationAllOK" 0 "Null" ;
VAL_ 756 AdjustableChimeVol2_Rq 15 "NotUsed_3" 14 "NotUsed_2" 13 "NotUsed_1" 12 "LevelPlus6" 11 "LevelPlus5" 10 "LevelPlus4" 9 "LevelPlus3" 8 "LevelPlus2" 7 "LevelPlus1" 6 "LevelMinus1" 5 "LevelMinus2" 4 "LevelMinus3" 3 "LevelMinus4" 2 "LevelMinus5" 1 "LevelMinus6" 0 "DefaultVolume" ;
VAL_ 756 Chime_Time_Criticality2 2 "Low" 1 "High" 0 "Inactive" ;
VAL_ 756 Chime_Occurence2 15 "Continuous" 14 "14Repititions" 13 "13Repititions" 12 "12Repititions" 11 "11Repititions" 10 "10Repititions" 9 "9Repititions" 8 "8Repititions" 7 "7Repititions" 6 "6Repititions" 5 "5Repititions" 4 "4Repititions" 3 "3Repititions" 2 "2Repititions" 1 "PlayOnce" 0 "Inactive" ;
VAL_ 756 Chime_Directionality2 3 "RearSpeakers" 2 "FrontSpeakers" 1 "ALL" 0 "Inactive" ;
VAL_ 756 Chime2Id_No_Rq 255 "Id255" 250 "Id250" 240 "Id240" 220 "Id220" 200 "Id200" 180 "Id180" 160 "Id160" 140 "Id140" 120 "Id120" 100 "Id100" 90 "Id90" 80 "Id80" 70 "Id70" 60 "Id60" 50 "Id50" 40 "Id40" 30 "Id30" 20 "Id20" 10 "Id10" 1 "Id1" 0 "Inactive" ;
VAL_ 544 ChimeId_No_Rq 255 "Id255" 250 "Id250" 240 "Id240" 220 "Id220" 200 "Id200" 180 "Id180" 160 "Id160" 140 "Id140" 120 "Id120" 100 "Id100" 90 "Id90" 80 "Id80" 70 "Id70" 60 "Id60" 50 "Id50" 40 "Id40" 30 "Id30" 20 "Id20" 10 "Id10" 1 "Id1" 0 "Inactive" ;
VAL_ 544 AdjustableChimeVol_Rq 15 "NotUsed_3" 14 "NotUsed_2" 13 "NotUsed_1" 12 "LevelPlus6" 11 "LevelPlus5" 10 "LevelPlus4" 9 "LevelPlus3" 8 "LevelPlus2" 7 "LevelPlus1" 6 "LevelMinus1" 5 "LevelMinus2" 4 "LevelMinus3" 3 "LevelMinus4" 2 "LevelMinus5" 1 "LevelMinus6" 0 "DefaultVolume" ;
VAL_ 544 Chime_Occurence 15 "Continuous" 14 "14Repititions" 13 "13Repititions" 12 "12Repititions" 11 "11Repititions" 10 "10Repititions" 9 "9Repititions" 8 "8Repititions" 7 "7Repititions" 6 "6Repititions" 5 "5Repititions" 4 "4Repititions" 3 "3Repititions" 2 "2Repititions" 1 "PlayOnce" 0 "Inactive" ;
VAL_ 544 Chime_Time_Criticality 2 "Low" 1 "High" 0 "Inactive" ;
VAL_ 544 Chime_Directionality 3 "RearSpeakers" 2 "FrontSpeakers" 1 "ALL" 0 "Inactive" ;
VAL_ 291 LangUpdate_Rsp 2 "Language_Not_Supported" 1 "Language_Updated" 0 "Inactive" ;
VAL_ 400 Mc_SetCurrStatMCCh_Rq 7 "MCChannel7" 6 "MCChannel6" 5 "MCChannel5" 4 "MCChannel4" 3 "MCChannel3" 2 "MCChannel2" 1 "MCChannel1" 0 "Inactive" ;
VAL_ 400 Mc_SetCurrentStatOp_Rq 0 "Inactive" 1 "SetCurrentFrequency" 2 "SetCurrentPiCode" 3 "SetCurrentStation" ;
VAL_ 400 Mc_PerTUPresetArea_Rq 13 "reserved" 12 "GetSAT3PresetData" 11 "GetSAT2PresetData" 15 "reserved_last" 10 "GetSAT1PresetData" 9 "GetDAB2PresetData" 8 "GetDAB1PresetData" 7 "GetDAB3PresetData" 6 "GetAmPresetData" 5 "GetAmAstPresetData" 4 "GetFmAstPresetData" 3 "GetFm3PresetData" 2 "GetFm2PresetData" 1 "GetFm1PresetData" 0 "Inactive" ;
VAL_ 647 HEC_BTIncomingCall_Rq 0 "Inactive" 1 "AcceptIncomingCall" 2 "DeclineIncomingCall" ;
VAL_ 647 HEC_BTEndTelService_Rq 1 "EndOngoingTelephonyCall" 0 "Inactive" ;
VAL_ 359 PrplWhlRgenMn_Tq_Actl 8191 "Faulty" ;
VAL_ 359 ElPw_D_StatStrtStop 15 "NotUsed6" 14 "NotUsed5" 13 "NotUsed4" 12 "NotUsed3" 11 "NotUsed2" 10 "NotUsed1" 9 "Supported_Level_4" 8 "Supported_Level_3" 7 "Supported_Level_2" 6 "Supported_Level_1" 5 "Limited_Support" 4 "Fault_Limited" 3 "LV_Event_in_Progress" 2 "Not_Supported_Imminent" 1 "Supported_All" 0 "Not_Supported" ;
VAL_ 359 PrplWhlTot2_Tq_Actl 65535 "Fault" 65534 "NoDataExists" ;
VAL_ 359 LscmbbDeny_B_ActlPrpl 1 "Denied" 0 "Allowed" ;
VAL_ 359 LscmbbEngTqMn_B_Actl 1 "Engine_Braking_Activated" 0 "Engine_Braking_Off" ;
VAL_ 359 PwPckTq_D_Stat 3 "PwPckOn_TqAvailable" 2 "StartInPrgrss_TqNotAvail" 1 "PwPckOn_TqNotAvailable" 0 "PwPckOff_TqNotAvailable" ;
VAL_ 359 Eng_D_Stat 3 "NotUsed" 2 "EngAutoStopped" 1 "EngOn" 0 "EngOff" ;
VAL_ 359 PlgActvArb_B_Actl 1 "On" 0 "Off" ;
VAL_ 359 ElPw_D_Stat 7 "NotUsed_3" 6 "NotUsed_2" 5 "NotUsed_1" 4 "Fault_Limited" 3 "LV_Event_In_Progress" 2 "Not_Supported_Imminent" 1 "Supported" 0 "Not_Supported" ;
VAL_ 359 TrnAinTq_D_Qf 3 "OK" 2 "Not_Within_Specifications" 1 "No_Data_Exists" 0 "Faulty" ;
VAL_ 990 PersIndexDdm_D_Actl 7 "Unused_3" 6 "Unused_2" 5 "Unused_1" 4 "Vehicle" 3 "PERS_4" 2 "PERS_3" 1 "PERS_2" 0 "PERS_1" ;
VAL_ 1091 WakeAlarm2_B_Typ 1 "CanAndEcuDriveCircuit" 0 "CanOnly" ;
VAL_ 1091 CamraRearOn_D2_Stat2 7 "Faulty" 6 "NotUsed_3" 5 "NotUsed_2" 4 "NotUsed_1" 3 "Decommission" 2 "Activate" 1 "Deactivate" 0 "Null" ;
VAL_ 1091 PoliceAux4Lamp_B_Rq2 1 "On" 0 "Off" ;
VAL_ 1091 PoliceAux3Lamp_B_Rq2 1 "On" 0 "Off" ;
VAL_ 1091 PoliceAux2Lamp_B_Rq2 1 "On" 0 "Off" ;
VAL_ 1091 PoliceAux1Lamp_B_Rq2 1 "On" 0 "Off" ;
VAL_ 1091 TowBarMsgTxt_D_Rq 7 "NotUsed3" 6 "NotUsed2" 5 "NotUsed1" 4 "TowBar_Ext_No_Trlr" 3 "Error_Dealer_Fix" 2 "Start_Engine_Swivel" 1 "Check_Tow_Bar" 0 "Null" ;
VAL_ 1091 ParkLampTrlrOut_B_Stat 1 "Out" 0 "Null" ;
VAL_ 1091 StopLampTrlrOut_B_Stat 1 "Out" 0 "Null" ;
VAL_ 1091 TrlrBattChrg_D_Stat 3 "Reverse" 2 "Normal" 1 "Low" 0 "Null" ;
VAL_ 1091 TrlrLampCtl_D_Stat 3 "NotUsed" 2 "TrlrLampCnnctDrvFailure" 1 "TrlrLampNotCnnctDrvFailure" 0 "Null" ;
VAL_ 1091 TrlrAlarmSpprt_D_Stat 3 "SupportedByBrakesAndLights" 2 "SupportedByLights" 1 "SupportedByBrakes" 0 "NotSupported" ;
VAL_ 1091 TurnLampTrlrRr_B_Stat 1 "Out" 0 "Null" ;
VAL_ 1091 TurnLampTrlrRl_B_Stat 1 "Out" 0 "Null" ;
VAL_ 1091 TrlrLampCnnct_B_Actl 1 "Yes" 0 "No" ;
VAL_ 1045 VehStab_D_Stat 15 "Faulty" 14 "No_Data_Exists" 13 "NotUsed6" 12 "NotUsed5" 11 "NotUsed4" 10 "NotUsed3" 9 "NotUsed2" 8 "Combined_OS_and_US" 7 "High_SSRA_no_OS" 6 "Straight" 5 "Post_Oversteer" 4 "Post_Transition" 3 "Countersteer" 2 "Understeer" 1 "Oversteer" 0 "Linear" ;
VAL_ 1045 BrkFluidLvl_D_Stat 3 "Invalid" 2 "Unknown" 1 "Low" 0 "OK" ;
VAL_ 1045 LsmcBrkDecel_D_Stat 7 "NotUsed_3" 6 "NotUsed_2" 5 "NotUsed_1" 4 "Denied" 3 "FaultDegraded" 2 "FaultExt" 1 "On" 0 "Off" ;
VAL_ 1045 VehYawNonLin_W_Rq 4095 "Fault" 4094 "Unknown" ;
VAL_ 1045 VehYawLin_W_Rq 4095 "Fault" 4094 "Unknown" ;
VAL_ 1045 VehVActlBrk_D_Qf 3 "OK" 2 "Not_Within_Specifications" 1 "No_Data_Exists" 0 "Faulty" ;
VAL_ 261 ChrgStatDsply_D_Rq 3 "NotUsed_2" 2 "NotUsed_1" 1 "On" 0 "Off" ;
VAL_ 261 NextUsageTimeToggle_Rq 0 "Inactive" 2 "Disable" 1 "Enable" ;
VAL_ 261 LongTermParking_Rq 2 "On" 1 "Off" 0 "Inactive" ;
VAL_ 261 ModemReset_D_Rq 15 "NotUsed_11" 14 "NotUsed_10" 13 "NotUsed_9" 12 "NotUsed_8" 11 "NotUsed_7" 10 "NotUsed_6" 9 "NotUsed_5" 8 "NotUsed_4" 7 "NotUsed_3" 6 "BrandConnectReset2" 5 "BrandConnectReset1" 4 "CcsReset" 3 "OnlineTrafficReset" 2 "PaakReset" 1 "WifiHotspotReset" 0 "Null" ;
VAL_ 261 StopStrtDrvMde_B_RqBtn3 1 "Pressed" 0 "Not_Pressed" ;
VAL_ 261 AudioToneTouchY_D_Rq 255 "Value254" 2 "Value1_up_to_0xFE_Value253" 1 "Value0" 0 "Null" ;
VAL_ 261 AudioToneTouchX_D_Rq 255 "Value254" 2 "Value1_up_to_0xFE_Value253" 1 "Value0" 0 "Null" ;
VAL_ 261 TCU_ESN_D_Rq 3 "NotUsed" 2 "TCU_ESN_Request" 1 "NoRequest" 0 "Inactive" ;
VAL_ 261 FactoryReset_Rq 1 "ResetFactoryDefaults" 0 "Inactive" ;
VAL_ 261 OffPeakTimeSetType_Rq 4 "WeekendEnd" 3 "WeekendStart" 2 "WeekdayEnd" 1 "WeekdayStart" 0 "Inactive" ;
VAL_ 261 AudioToneTouch_D_Rq 3 "NotUsed" 2 "Enabled" 1 "Disabled" 0 "Null" ;
VAL_ 995 KeyAssocCmplt_B_Rq 1 "Yes" 0 "No" ;
VAL_ 995 FobAssocChime_B_Rq 1 "On" 0 "Off" ;
VAL_ 995 PersIndexBcm_D_Actl 7 "Unused_3" 6 "Unused_2" 5 "Unused_1" 4 "Vehicle" 3 "PERS_4" 2 "PERS_3" 1 "PERS_2" 0 "PERS_1" ;
VAL_ 995 LightAmbIntsty_No_Actl 0 "Off" ;
VAL_ 1000 AHU_Bezel_Diag_St 15 "Reserved" 6 "SignalStrength" 5 "SDARSESNNumber" 4 "SpeakerWalkAround" 3 "CalibrationPartNumber" 2 "HardwarePartNumber" 1 "SoftwarePartNumber" 0 "Inactive_NOP" ;
VAL_ 1000 ThermalReduction_St 15 "Reserved" 14 "_13dB_AudioReduction" 13 "_12dB_AudioReduction" 12 "_11dB_AudioReduction" 11 "_10dB_AudioReduction" 10 "_9dB_AudioReduction" 9 "_8dB_AudioReduction" 8 "_7dB_AudioReduction" 7 "_6dB_AudioReduction" 6 "_5dB_AudioReduction" 5 "_4dB_AudioReduction" 4 "_3dB_AudioReduction" 3 "_2dB_AudioReduction" 2 "_1dB_AudioReduction" 1 "NoAudioReduction" 0 "Null" ;
VAL_ 1000 AHU_Shaker_St 1 "Active" 0 "Inactive" ;
VAL_ 1000 ACM_BeltminderAudioSt 0 "Invalid" 1 "Off" 2 "On" ;
VAL_ 1000 MyKeyVolumeLimitUp 2 "NotUpdated" 1 "Updated" 0 "Invalid" ;
VAL_ 1000 MyKeyVolumeLimitMode 0 "Invalid" 1 "Off" 2 "On" ;
VAL_ 992 MsgCntrPersIndex_D_Rq 7 "Unused_3" 6 "Unused_2" 5 "Unused_1" 4 "Vehicle" 3 "PERS_4" 2 "PERS_3" 1 "PERS_2" 0 "PERS_1" ;
VAL_ 992 MsgCntrDsplyOp_D_Rq 7 "Unused_2" 6 "Unused_1" 5 "Copy" 4 "Restore" 3 "Upload" 2 "Set" 1 "Query" 0 "Null" ;
